VERSION "isobus-dd-11783"

NS_ :

BS_:

BU_: DD_SOURCE

BO_ 2550595584 DD_GPV4_1792: 8 DD_SOURCE
 SG_ General_purpose_valve_load_sense_pressure : 7|16@0+ (5.0,0.0) [0.0|321275.0] "kPa" Vector__XXX
 SG_ General_purpose_valve_pilot_pressure : 23|8@0+ (16.0,0.0) [0.0|4000.0] "kPa" Vector__XXX
 SG_ General_purpose_valve_assembly_load_sense_pressure : 31|16@0+ (5.0,0.0) [0.0|321275.0] "kPa" Vector__XXX
 SG_ General_purpose_valve_assembly_supply_pressure : 47|16@0+ (5.0,0.0) [0.0|321275.0] "kPa" Vector__XXX
 SG_ Valve_Pilot_Pressure_Switch : 63|2@0+ (4.0,0.0) [0.0|3.0] "" Vector__XXX

BO_ 2619539456 DD_TIM12_8960: 15 DD_SOURCE
 SG_ Auxiliary_Valve_1_Flow : 39|16@0- (0.004,-128.512) [-128.512|128.508] "%" Vector__XXX
 SG_ Auxiliary_Valve_1_Automation_Status : 23|4@0+ (16.0,0.0) [0.0|15.0] "Bit Field" Vector__XXX
 SG_ Auxiliary_Valve_1_Exit_Reason_Code : 28|5@0+ (32.0,0.0) [0.0|31.0] "Bit Field" Vector__XXX
 SG_ TIM_server_heartbeat_counter : 15|8@0+ (1.0,0.0) [0.0|255.0] "count" Vector__XXX
 SG_ Auxiliary_valve_1_flow_type : 31|2@0+ (4.0,0.0) [0.0|3.0] "bit" Vector__XXX
 SG_ TIM_v1_Server_to_Client_function_ID_Message_Code : 7|8@0+ (1.0,0.0) [0.0|255.0] "count" Vector__XXX
 SG_ Number_of_TIM_server_functions_assigned_to_CF_to_follow : 119|8@0+ (1.0,0.0) [0.0|250.0] "byte" Vector__XXX

BO_ 2619604992 DD_TIM21_9216: 8 DD_SOURCE
 SG_ Auxiliary_Valve_1_Flow_Request : 39|16@0- (0.004,-128.512) [-128.512|128.508] "%" Vector__XXX
 SG_ TIM_client_heartbeat_counter : 15|8@0+ (16.0,0.0) [0.0|255.0] "count" Vector__XXX
 SG_ TIM_client_state : 19|4@0+ (16.0,0.0) [0.0|13.0] "count" Vector__XXX
 SG_ TIM_Client_Minimum_TIM_version_number : 31|8@0+ (1.0,0.0) [0.0|250.0] "count" Vector__XXX
 SG_ TIM_v1_Client_to_Server_function_ID_Message_Code : 7|8@0+ (1.0,0.0) [0.0|255.0] "count" Vector__XXX

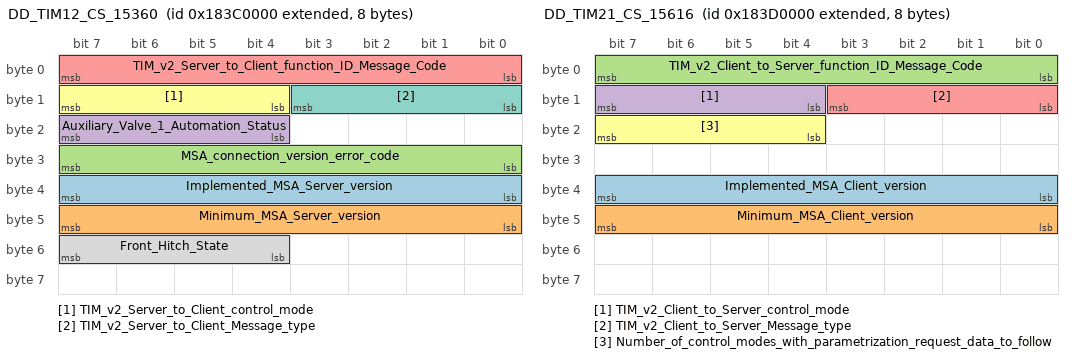
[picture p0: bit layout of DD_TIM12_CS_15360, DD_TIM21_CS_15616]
BO_ 2554068992 DD_TIM12_CS_15360: 8 DD_SOURCE
 SG_ Implemented_MSA_Server_version : 39|8@0+ (1.0,0.0) [0.0|255.0] "count" Vector__XXX
 SG_ Minimum_MSA_Server_version : 47|8@0+ (1.0,0.0) [0.0|255.0] "count" Vector__XXX
 SG_ MSA_connection_version_error_code : 31|8@0+ (1.0,0.0) [0.0|255.0] "count" Vector__XXX
 SG_ Auxiliary_Valve_1_Automation_Status : 23|4@0+ (16.0,0.0) [0.0|15.0] "Bit Field" Vector__XXX
 SG_ TIM_v2_Server_to_Client_function_ID_Message_Code : 7|8@0+ (1.0,0.0) [0.0|255.0] "count" Vector__XXX
 SG_ TIM_v2_Server_to_Client_control_mode : 15|4@0+ (16.0,0.0) [0.0|240.0] "" Vector__XXX
 SG_ TIM_v2_Server_to_Client_Message_type : 11|4@0+ (16.0,0.0) [0.0|240.0] "" Vector__XXX
 SG_ Front_Hitch_State : 55|4@0+ (16.0,0.0) [0.0|15.0] "Bit field" Vector__XXX

BO_ 2554134528 DD_TIM21_CS_15616: 8 DD_SOURCE
 SG_ Implemented_MSA_Client_version : 39|8@0+ (1.0,0.0) [0.0|255.0] "count" Vector__XXX
 SG_ Minimum_MSA_Client_version : 47|8@0+ (1.0,0.0) [0.0|255.0] "count" Vector__XXX
 SG_ TIM_v2_Client_to_Server_function_ID_Message_Code : 7|8@0+ (1.0,0.0) [0.0|255.0] "count" Vector__XXX
 SG_ TIM_v2_Client_to_Server_control_mode : 15|4@0+ (16.0,0.0) [0.0|240.0] "" Vector__XXX
 SG_ TIM_v2_Client_to_Server_Message_type : 11|4@0+ (16.0,0.0) [0.0|240.0] "" Vector__XXX
 SG_ Number_of_control_modes_with_parametrization_request_data_to_follow : 23|4@0+ (1.0,0.0) [0.0|15.0] "count" Vector__XXX

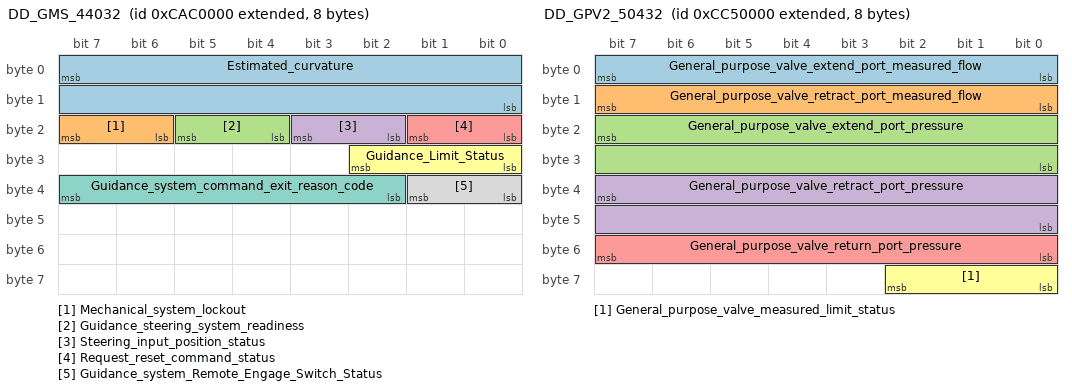
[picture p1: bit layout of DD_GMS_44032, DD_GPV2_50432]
BO_ 2360082432 DD_GMS_44032: 8 DD_SOURCE
 SG_ Estimated_curvature : 7|16@0- (0.25,-8032.0) [-8032.0|8031.75] "km-1" Vector__XXX
 SG_ Mechanical_system_lockout : 23|2@0+ (4.0,0.0) [0.0|3.0] "bit" Vector__XXX
 SG_ Guidance_steering_system_readiness : 21|2@0+ (4.0,0.0) [0.0|3.0] "bit" Vector__XXX
 SG_ Steering_input_position_status : 19|2@0+ (4.0,0.0) [0.0|3.0] "bit" Vector__XXX
 SG_ Request_reset_command_status : 17|2@0+ (4.0,0.0) [0.0|3.0] "bit" Vector__XXX
 SG_ Guidance_Limit_Status : 26|3@0+ (8.0,0.0) [0.0|7.0] "bit" Vector__XXX
 SG_ Guidance_system_command_exit_reason_code : 39|6@0+ (64.0,0.0) [0.0|63.0] "bit" Vector__XXX
 SG_ Guidance_system_Remote_Engage_Switch_Status : 33|2@0+ (4.0,0.0) [0.0|3.0] "bit" Vector__XXX

BO_ 2360147968 DD_GSC_44288: 8 DD_SOURCE
 SG_ Curvature_command : 7|16@0- (0.25,-8032.0) [-8032.0|8031.75] "km-1" Vector__XXX
 SG_ Curvature_command_status : 23|2@0+ (4.0,0.0) [0.0|3.0] "bit" Vector__XXX

BO_ 2361655296 DD_GPV3_50176: 8 DD_SOURCE
 SG_ General_purpose_valve_port_flow_Command : 7|8@0+ (0.4,0.0) [0.0|100.0] "%" Vector__XXX
 SG_ General_purpose_valve_state_Command : 23|4@0+ (16.0,0.0) [0.0|15.0] "bit" Vector__XXX
 SG_ General_purpose_value_fail_safe_mode_Command : 17|2@0+ (4.0,0.0) [0.0|3.0] "bit" Vector__XXX
 SG_ General_purpose_valve_port_flow_Extended_Resolution_Command : 31|16@0+ (0.0015625,0.0) [0.0|100.0] "%" Vector__XXX

BO_ 2361720832 DD_GPV2_50432: 8 DD_SOURCE
 SG_ General_purpose_valve_extend_port_measured_flow : 7|8@0- (1.0,-125.0) [-100.0|100.0] "%" Vector__XXX
 SG_ General_purpose_valve_retract_port_measured_flow : 15|8@0- (1.0,-125.0) [-100.0|100.0] "%" Vector__XXX
 SG_ General_purpose_valve_extend_port_pressure : 23|16@0+ (5.0,0.0) [0.0|321275.0] "kPa" Vector__XXX
 SG_ General_purpose_valve_retract_port_pressure : 39|16@0+ (5.0,0.0) [0.0|321275.0] "kPa" Vector__XXX
 SG_ General_purpose_valve_return_port_pressure : 55|8@0+ (16.0,0.0) [0.0|4000.0] "kPa" Vector__XXX
 SG_ General_purpose_valve_measured_limit_status : 58|3@0+ (8.0,0.0) [0.0|7.0] "bit" Vector__XXX

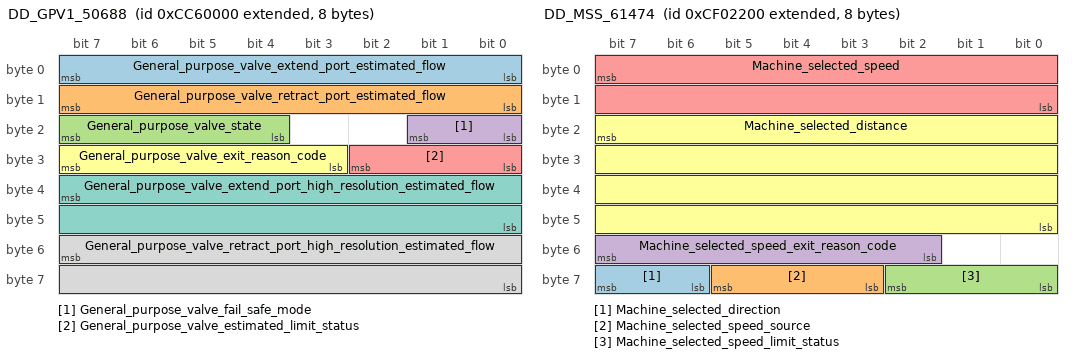
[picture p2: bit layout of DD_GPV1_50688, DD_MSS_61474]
BO_ 2361786368 DD_GPV1_50688: 8 DD_SOURCE
 SG_ General_purpose_valve_extend_port_estimated_flow : 7|8@0- (1.0,-125.0) [-100.0|100.0] "%" Vector__XXX
 SG_ General_purpose_valve_retract_port_estimated_flow : 15|8@0- (1.0,-125.0) [-100.0|100.0] "%" Vector__XXX
 SG_ General_purpose_valve_state : 23|4@0+ (16.0,0.0) [0.0|15.0] "bit" Vector__XXX
 SG_ General_purpose_valve_fail_safe_mode : 17|2@0+ (4.0,0.0) [0.0|3.0] "bit" Vector__XXX
 SG_ General_purpose_valve_estimated_limit_status : 26|3@0+ (8.0,0.0) [0.0|7.0] "bit" Vector__XXX
 SG_ General_purpose_valve_exit_reason_code : 31|5@0+ (32.0,0.0) [0.0|31.0] "bit" Vector__XXX
 SG_ General_purpose_valve_extend_port_high_resolution_estimated_flow : 39|16@0- (0.004,-125.0) [-100.0|100.0] "%" Vector__XXX
 SG_ General_purpose_valve_retract_port_high_resolution_estimated_flow : 55|16@0- (0.004,-125.0) [-100.0|100.0] "%" Vector__XXX

BO_ 2362114048 DD_PD_51968: 8 DD_SOURCE
 SG_ Process_data_command : 7|4@0+ (16.0,0.0) [0.0|15.0] "bit" Vector__XXX
 SG_ Process_data_element_number : 3|12@0+ (1.0,0.0) [0.0|4095.0] "bit" Vector__XXX
 SG_ Process_data_data_dictionary_identifier : 23|16@0+ (1.0,0.0) [0.0|65535.0] "bit" Vector__XXX
 SG_ Process_data_variable_value : 39|32@0+ (1.0,0.0) [0.0|4294967295.0] "VariantDetermined" Vector__XXX

BO_ 2563506176 DD_REQRR_52224: 8 DD_SOURCE
 SG_ PGN_of_the_request_1 : 7|24@0+ (1.0,0.0) [0.0|16.0] "PGN" Vector__XXX
 SG_ Repetition_rate_Command : 31|16@0+ (1.0,0.0) [0.0|64.0] "ms" Vector__XXX

BO_ 2362441728 DD_CL_53248: 8 DD_SOURCE
 SG_ Background_illumination_level_Command : 7|8@0+ (0.4,0.0) [0.0|102.0] "%" Vector__XXX

BO_ 2364547584 DD_MSS_61474: 8 DD_SOURCE
 SG_ Machine_selected_direction : 63|2@0+ (4.0,0.0) [0.0|3.0] "bit" Vector__XXX
 SG_ Machine_selected_speed_source : 61|3@0+ (8.0,0.0) [0.0|7.0] "bit" Vector__XXX
 SG_ Machine_selected_speed_limit_status : 58|3@0+ (8.0,0.0) [0.0|7.0] "bit" Vector__XXX
 SG_ Machine_selected_speed_exit_reason_code : 55|6@0+ (64.0,0.0) [0.0|63.0] "bit" Vector__XXX
 SG_ Machine_selected_speed : 7|16@0+ (0.001,0.0) [0.0|64.0] "m/s" Vector__XXX
 SG_ Machine_selected_distance : 23|32@0+ (0.001,0.0) [0.0|4.0] "m" Vector__XXX

BO_ 2364597248 DD_HRTBTM_61668: 8 DD_SOURCE
 SG_ Heartbeat_sequence_number : 7|8@0+ (1.0,0.0) [0.0|255.0] "count" Vector__XXX

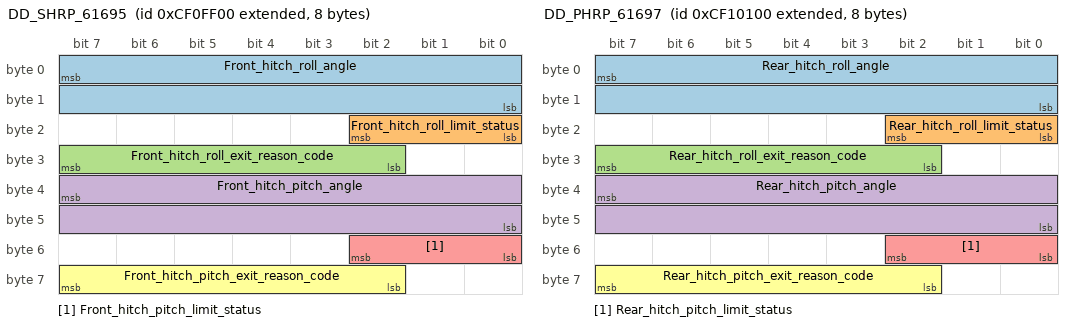
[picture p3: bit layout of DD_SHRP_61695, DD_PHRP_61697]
BO_ 2364604160 DD_SHRP_61695: 8 DD_SOURCE
 SG_ Front_hitch_roll_angle : 7|16@0- (0.002,-64.0) [-64.0|64.51] "deg" Vector__XXX
 SG_ Front_hitch_roll_limit_status : 18|3@0+ (8.0,0.0) [0.0|7.0] "bit" Vector__XXX
 SG_ Front_hitch_roll_exit_reason_code : 31|6@0+ (64.0,0.0) [0.0|63.0] "bit" Vector__XXX
 SG_ Front_hitch_pitch_angle : 39|16@0- (0.002,-64.0) [-64.0|64.51] "deg" Vector__XXX
 SG_ Front_hitch_pitch_limit_status : 50|3@0+ (8.0,0.0) [0.0|7.0] "bit" Vector__XXX
 SG_ Front_hitch_pitch_exit_reason_code : 63|6@0+ (64.0,0.0) [0.0|63.0] "bit" Vector__XXX

BO_ 2364604416 DD_SHRPC_61696: 8 DD_SOURCE
 SG_ Front_hitch_roll_command : 7|16@0- (0.002,-64.0) [-64.0|64.51] "deg" Vector__XXX
 SG_ Front_hitch_roll_sensitivity_command : 23|8@0+ (0.4,0.0) [0.0|100.0] "%" Vector__XXX
 SG_ Front_hitch_pitch_command : 31|16@0- (0.002,-64.0) [-64.0|64.51] "deg" Vector__XXX
 SG_ Front_hitch_pitch_sensitivity_command : 47|8@0+ (0.4,0.0) [0.0|100.0] "%" Vector__XXX

BO_ 2364604672 DD_PHRP_61697: 8 DD_SOURCE
 SG_ Rear_hitch_roll_angle : 7|16@0- (0.002,-64.0) [-64.0|64.51] "deg" Vector__XXX
 SG_ Rear_hitch_roll_limit_status : 18|3@0+ (8.0,0.0) [0.0|7.0] "bit" Vector__XXX
 SG_ Rear_hitch_roll_exit_reason_code : 31|6@0+ (64.0,0.0) [0.0|63.0] "bit" Vector__XXX
 SG_ Rear_hitch_pitch_angle : 39|16@0- (0.002,-64.0) [-64.0|64.51] "deg" Vector__XXX
 SG_ Rear_hitch_pitch_limit_status : 50|3@0+ (8.0,0.0) [0.0|7.0] "bit" Vector__XXX
 SG_ Rear_hitch_pitch_exit_reason_code : 63|6@0+ (64.0,0.0) [0.0|63.0] "bit" Vector__XXX

BO_ 2364604928 DD_PHRPC_61698: 8 DD_SOURCE
 SG_ Rear_hitch_roll_command : 7|16@0- (0.002,-64.0) [-64.0|64.51] "deg" Vector__XXX
 SG_ Rear_hitch_roll_sensitivity_command : 23|8@0+ (0.4,0.0) [0.0|100.0] "%" Vector__XXX
 SG_ Rear_hitch_pitch_command : 31|16@0- (0.002,-64.0) [-64.0|64.51] "deg" Vector__XXX
 SG_ Rear_hitch_pitch_sensitivity_command : 47|8@0+ (0.4,0.0) [0.0|100.0] "%" Vector__XXX

BO_ 2364620288 DD_FHYC_61758: 8 DD_SOURCE
 SG_ Front_hitch_yaw_command : 7|16@0- (1.0,-200.0) [-200.0|200.0] "deg" Vector__XXX

BO_ 2364620544 DD_RHYC_61759: 8 DD_SOURCE
 SG_ Rear_hitch_yaw_command : 7|16@0- (1.0,-200.0) [-200.0|200.0] "deg" Vector__XXX

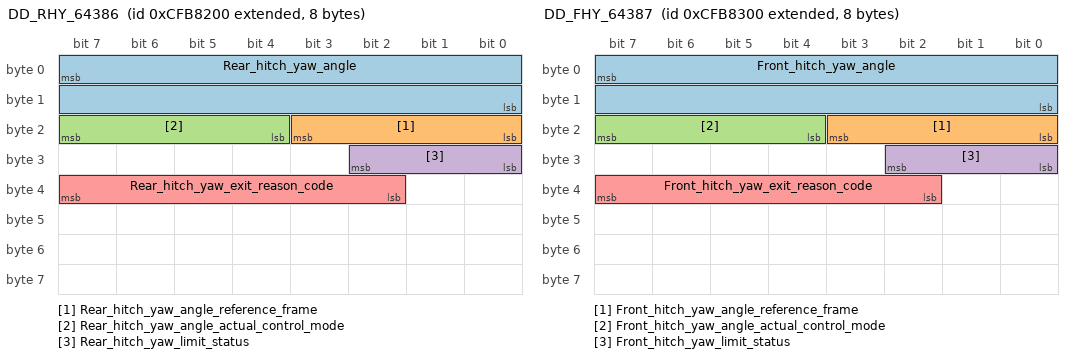
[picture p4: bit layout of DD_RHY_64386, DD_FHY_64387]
BO_ 2365293056 DD_RHY_64386: 8 DD_SOURCE
 SG_ Rear_hitch_yaw_angle : 7|16@0- (1.0,-200.0) [-200.0|200.0] "deg" Vector__XXX
 SG_ Rear_hitch_yaw_angle_reference_frame : 19|4@0+ (16.0,0.0) [0.0|15.0] "bit" Vector__XXX
 SG_ Rear_hitch_yaw_angle_actual_control_mode : 23|4@0+ (16.0,0.0) [0.0|15.0] "bit" Vector__XXX
 SG_ Rear_hitch_yaw_limit_status : 26|3@0+ (8.0,0.0) [0.0|7.0] "bit" Vector__XXX
 SG_ Rear_hitch_yaw_exit_reason_code : 39|6@0+ (64.0,0.0) [0.0|63.0] "bit" Vector__XXX

BO_ 2365293312 DD_FHY_64387: 8 DD_SOURCE
 SG_ Front_hitch_yaw_angle : 7|16@0- (1.0,-200.0) [-200.0|200.0] "deg" Vector__XXX
 SG_ Front_hitch_yaw_angle_reference_frame : 19|4@0+ (16.0,0.0) [0.0|15.0] "bit" Vector__XXX
 SG_ Front_hitch_yaw_angle_actual_control_mode : 23|4@0+ (16.0,0.0) [0.0|15.0] "bit" Vector__XXX
 SG_ Front_hitch_yaw_limit_status : 26|3@0+ (8.0,0.0) [0.0|7.0] "bit" Vector__XXX
 SG_ Front_hitch_yaw_exit_reason_code : 39|6@0+ (64.0,0.0) [0.0|63.0] "bit" Vector__XXX

BO_ 2365293568 DD_OPSTAT_64388: 8 DD_SOURCE
 SG_ Operator_Status_Sequence_Counter : 7|8@0+ (256.0,0.0) [0.0|255.0] "bit" Vector__XXX
 SG_ Operator_Presence_state : 15|2@0+ (4.0,0.0) [0.0|3.0] "bit" Vector__XXX
 SG_ Operator_Awareness_state : 13|2@0+ (4.0,0.0) [0.0|3.0] "bit" Vector__XXX
 SG_ Operator_Presence_and_Awareness_Status_Checksum : 63|8@0+ (256.0,0.0) [0.0|255.0] "bit" Vector__XXX

BO_ 2566655488 DD_PHRPS_64526: 8 DD_SOURCE
 SG_ Rear_hitch_roll_sensitivity : 7|8@0+ (0.4,0.0) [0.0|100.0] "%" Vector__XXX
 SG_ Rear_hitch_pitch_sensitivity : 15|8@0+ (0.4,0.0) [0.0|100.0] "%" Vector__XXX

BO_ 2566655744 DD_SHRPS_64527: 8 DD_SOURCE
 SG_ Front_hitch_roll_sensitivity : 7|8@0+ (0.4,0.0) [0.0|100.0] "%" Vector__XXX
 SG_ Front_hitch_pitch_sensitivity : 15|8@0+ (0.4,0.0) [0.0|100.0] "%" Vector__XXX

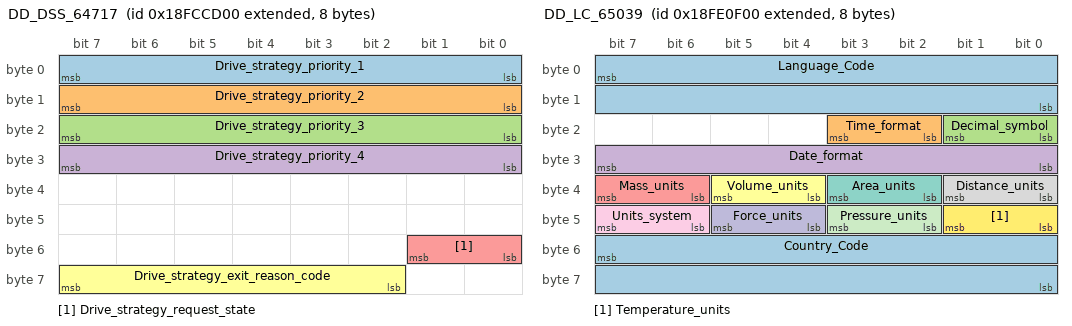
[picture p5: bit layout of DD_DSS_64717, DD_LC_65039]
BO_ 2566704384 DD_DSS_64717: 8 DD_SOURCE
 SG_ Drive_strategy_priority_1 : 7|8@0+ (256.0,0.0) [0.0|255.0] "bit" Vector__XXX
 SG_ Drive_strategy_priority_2 : 15|8@0+ (256.0,0.0) [0.0|255.0] "bit" Vector__XXX
 SG_ Drive_strategy_priority_3 : 23|8@0+ (256.0,0.0) [0.0|255.0] "bit" Vector__XXX
 SG_ Drive_strategy_priority_4 : 31|8@0+ (256.0,0.0) [0.0|255.0] "bit" Vector__XXX
 SG_ Drive_strategy_request_state : 49|2@0+ (4.0,0.0) [0.0|3.0] "bit" Vector__XXX
 SG_ Drive_strategy_exit_reason_code : 63|6@0+ (64.0,0.0) [0.0|63.0] "bit" Vector__XXX

BO_ 2365378048 DD_DSC_64718: 8 DD_SOURCE
 SG_ Drive_strategy_priority_1_request : 7|8@0+ (256.0,0.0) [0.0|255.0] "bit" Vector__XXX
 SG_ Drive_strategy_priority_2_request : 15|8@0+ (256.0,0.0) [0.0|255.0] "bit" Vector__XXX
 SG_ Drive_strategy_priority_3_request : 23|8@0+ (256.0,0.0) [0.0|255.0] "bit" Vector__XXX
 SG_ Drive_strategy_priority_4_request : 31|8@0+ (256.0,0.0) [0.0|255.0] "bit" Vector__XXX
 SG_ Restore_operator_drive_strategy_setting_request : 63|2@0+ (4.0,0.0) [0.0|3.0] "bit" Vector__XXX

BO_ 2365391360 DD_AISO_64770: 8 DD_SOURCE
 SG_ Stop_all_implement_operations : 63|2@0+ (4.0,0.0) [0.0|3.0] "bit" Vector__XXX
 SG_ Stop_All_Implement_Operations_Transition_Number : 55|8@0+ (256.0,0.0) [0.0|255.0] "bit" Vector__XXX

BO_ 2365391616 DD_IOS_64771: 8 DD_SOURCE
 SG_ Implement_operating_state_command : 63|2@0+ (4.0,0.0) [0.0|3.0] "bit" Vector__XXX

BO_ 2566730240 DD_ECUDP_64818: 8 DD_SOURCE
 SG_ Diagnostic_protocol_identification : 7|8@0+ (8.0,0.0) [0.0|2040.0] "Bit mapped" Vector__XXX

BO_ 2566734336 DD_ICC_64834: 8 DD_SOURCE
 SG_ ISOBUS_compliance_test_protocol_publication_year : 7|6@0+ (1.0,2000.0) [2000.0|2061.0] "Years" Vector__XXX
 SG_ ISOBUS_compliance_test_protocol_revision : 1|5@0+ (32.0,0.0) [0.0|30.0] "bit" Vector__XXX
 SG_ ISOBUS_compliance_certification_laboratory_ID : 10|11@0+ (2047.0,0.0) [0.0|2047.0] "bit" Vector__XXX
 SG_ ISOBUS_compliance_certification_type_Minimum_CF : 24|1@0+ (2.0,0.0) [0.0|1.0] "bit" Vector__XXX
 SG_ ISOBUS_compliance_certification_type_TECU_Class_1 : 25|1@0+ (2.0,0.0) [0.0|1.0] "bit" Vector__XXX
 SG_ ISOBUS_compliance_certification_type_TECU_Class_2 : 26|1@0+ (2.0,0.0) [0.0|1.0] "bit" Vector__XXX
 SG_ ISOBUS_compliance_certification_type_TECU_Class_3 : 27|1@0+ (2.0,0.0) [0.0|1.0] "bit" Vector__XXX
 SG_ ISOBUS_compliance_certification_type_Class_3_ECU : 28|1@0+ (2.0,0.0) [0.0|1.0] "bit" Vector__XXX
 SG_ ISOBUS_compliance_certification_type_Virtual_terminal : 29|1@0+ (2.0,0.0) [0.0|1.0] "bit" Vector__XXX
 SG_ ISOBUS_compliance_certification_type_VT_working_set_master : 30|1@0+ (2.0,0.0) [0.0|1.0] "bit" Vector__XXX
 SG_ ISOBUS_compliance_certification_type_VT_working_set_member : 31|1@0+ (2.0,0.0) [0.0|1.0] "bit" Vector__XXX
 SG_ ISOBUS_compliance_certification_type_Task_Controller : 32|1@0+ (2.0,0.0) [0.0|1.0] "bit" Vector__XXX
 SG_ ISOBUS_compliance_certification_type_TC_working_set_master : 33|1@0+ (2.0,0.0) [0.0|1.0] "bit" Vector__XXX
 SG_ ISOBUS_compliance_certification_type_TC_working_set_member : 34|1@0+ (2.0,0.0) [0.0|1.0] "bit" Vector__XXX
 SG_ ISOBUS_compliance_certification_type_File_server : 35|1@0+ (2.0,0.0) [0.0|1.0] "bit" Vector__XXX
 SG_ ISOBUS_compliance_certification_type_GPS_receiver : 36|1@0+ (2.0,0.0) [0.0|1.0] "bit" Vector__XXX
 SG_ ISOBUS_compliance_certification_reference_number : 55|16@0+ (1.0,0.0) [0.0|65535.0] "count" Vector__XXX
 SG_ ISOBUS_compliance_certification_message_revision : 40|1@0+ (2.0,0.0) [0.0|1.0] "bit" Vector__XXX

BO_ 2365408000 DD_MSSC_64835: 8 DD_SOURCE
 SG_ Machine_selected_speed_set_point_command : 7|16@0+ (0.001,0.0) [0.0|64.0] "m/s" Vector__XXX
 SG_ Machine_selected_speed_setpoint_limit : 23|16@0+ (0.001,0.0) [0.0|64.0] "m/s" Vector__XXX
 SG_ Machine_selected_direction_command : 63|2@0+ (4.0,0.0) [0.0|3.0] "bit" Vector__XXX

BO_ 2365458432 DD_RTF_65032: 8 DD_SOURCE
 SG_ Speed_information_engine_speed : 7|1@0+ (2.0,0.0) [0.0|1.0] "bit" Vector__XXX
 SG_ Speed_information_ground_based_speed : 6|1@0+ (2.0,0.0) [0.0|1.0] "bit" Vector__XXX
 SG_ Speed_information_wheel_based_speed : 5|1@0+ (2.0,0.0) [0.0|1.0] "bit" Vector__XXX
 SG_ Power_management_maintain_power : 4|1@0+ (2.0,0.0) [0.0|1.0] "bit" Vector__XXX
 SG_ Power_management_maximum_time_tractor_power : 3|1@0+ (2.0,0.0) [0.0|1.0] "bit" Vector__XXX
 SG_ Power_management_key_switch : 2|1@0+ (2.0,0.0) [0.0|1.0] "bit" Vector__XXX
 SG_ Tractor_ECU_class_request : 1|2@0+ (4.0,0.0) [0.0|3.0] "bit" Vector__XXX
 SG_ Language_command_storage_in_Tractor_ECU : 13|1@0+ (2.0,0.0) [0.0|1.0] "bit" Vector__XXX
 SG_ Lighting_minimal_set_as_existing_trailer_connector : 12|1@0+ (2.0,0.0) [0.0|1.0] "bit" Vector__XXX
 SG_ PTO_information_rear_shaft_engagement : 11|1@0+ (2.0,0.0) [0.0|1.0] "bit" Vector__XXX
 SG_ PTO_information_rear_shaft_speed : 10|1@0+ (2.0,0.0) [0.0|1.0] "bit" Vector__XXX
 SG_ Hitch_information_rear_in_work : 9|1@0+ (2.0,0.0) [0.0|1.0] "bit" Vector__XXX
 SG_ Hitch_information_rear_position : 8|1@0+ (2.0,0.0) [0.0|1.0] "bit" Vector__XXX
 SG_ Estimated_or_measured_auxiliary_valve_status : 23|1@0+ (2.0,0.0) [0.0|1.0] "bit" Vector__XXX
 SG_ Lighting_full_implement_lighting_message_set : 22|1@0+ (2.0,0.0) [0.0|1.0] "bit" Vector__XXX
 SG_ Additional_hitch_parameters_rear_draft : 21|1@0+ (2.0,0.0) [0.0|1.0] "bit" Vector__XXX
 SG_ Speed_and_distance_wheel_based_direction : 20|1@0+ (2.0,0.0) [0.0|1.0] "bit" Vector__XXX
 SG_ Speed_and_distance_wheel_based_distance : 19|1@0+ (2.0,0.0) [0.0|1.0] "bit" Vector__XXX
 SG_ Speed_and_distance_ground_based_direction : 18|1@0+ (2.0,0.0) [0.0|1.0] "bit" Vector__XXX
 SG_ Speed_and_distance_ground_based_distance : 17|1@0+ (2.0,0.0) [0.0|1.0] "bit" Vector__XXX
 SG_ Time_date : 16|1@0+ (2.0,0.0) [0.0|1.0] "bit" Vector__XXX
 SG_ PTO_commands_rear_PTO_mode_gear_command : 29|1@0+ (2.0,0.0) [0.0|1.0] "bit" Vector__XXX
 SG_ Limit_request_status_reporting : 28|1@0+ (2.0,0.0) [0.0|1.0] "bit" Vector__XXX
 SG_ Auxiliary_valve_commands : 27|1@0+ (2.0,0.0) [0.0|1.0] "bit" Vector__XXX
 SG_ PTO_commands_rear_PTO_engagement_command : 26|1@0+ (2.0,0.0) [0.0|1.0] "bit" Vector__XXX
 SG_ PTO_commands_rear_PTO_speed_command : 25|1@0+ (2.0,0.0) [0.0|1.0] "bit" Vector__XXX
 SG_ Hitch_commands_rear_hitch_position : 24|1@0+ (2.0,0.0) [0.0|1.0] "bit" Vector__XXX
 SG_ Direction_control : 39|1@0+ (2.0,0.0) [0.0|1.0] "bit" Vector__XXX
 SG_ Machine_selected_speed_control : 38|1@0+ (2.0,0.0) [0.0|1.0] "bit" Vector__XXX
 SG_ Machine_selected_speed : 37|1@0+ (2.0,0.0) [0.0|1.0] "bit" Vector__XXX
 SG_ Operator_external_light_controls : 36|1@0+ (2.0,0.0) [0.0|1.0] "bit" Vector__XXX
 SG_ Navigational_pseudo_range_noise_statistics : 34|1@0+ (2.0,0.0) [0.0|1.0] "bit" Vector__XXX
 SG_ Navigational_system_position_data : 33|1@0+ (2.0,0.0) [0.0|1.0] "bit" Vector__XXX
 SG_ Navigational_system_high_output_position : 32|1@0+ (2.0,0.0) [0.0|1.0] "bit" Vector__XXX
 SG_ PTO_commands_front_PTO_engagement_command : 47|1@0+ (2.0,0.0) [0.0|1.0] "bit" Vector__XXX
 SG_ PTO_commands_front_PTO_speed_command : 46|1@0+ (2.0,0.0) [0.0|1.0] "bit" Vector__XXX
 SG_ Hitch_commands_front_hitch_position : 45|1@0+ (2.0,0.0) [0.0|1.0] "bit" Vector__XXX
 SG_ Additional_hitch_parameters_front_draft : 44|1@0+ (2.0,0.0) [0.0|1.0] "bit" Vector__XXX
 SG_ PTO_information_front_shaft_engagement : 43|1@0+ (2.0,0.0) [0.0|1.0] "bit" Vector__XXX
 SG_ PTO_information_front_shaft_speed : 42|1@0+ (2.0,0.0) [0.0|1.0] "bit" Vector__XXX
 SG_ Hitch_information_front_in_work : 41|1@0+ (2.0,0.0) [0.0|1.0] "bit" Vector__XXX
 SG_ Hitch_information_front_position : 40|1@0+ (2.0,0.0) [0.0|1.0] "bit" Vector__XXX
 SG_ Drive_Strategy_Status_and_Commands : 55|1@0+ (2.0,0.0) [0.0|1.0] "bit" Vector__XXX
 SG_ External_Guidance_Status_and_Commands : 54|1@0+ (2.0,0.0) [0.0|1.0] "bit" Vector__XXX
 SG_ PTO_commands_front_PTO_mode_gear_command : 48|1@0+ (2.0,0.0) [0.0|1.0] "bit" Vector__XXX
 SG_ Tractor_facility_reserved_bit_indicator : 63|1@0+ (2.0,0.0) [0.0|1.0] "bit" Vector__XXX

BO_ 2365458688 DD_TFR_65033: 8 DD_SOURCE
 SG_ Speed_information_engine_speed : 7|1@0+ (2.0,0.0) [0.0|1.0] "bit" Vector__XXX
 SG_ Speed_information_ground_based_speed : 6|1@0+ (2.0,0.0) [0.0|1.0] "bit" Vector__XXX
 SG_ Speed_information_wheel_based_speed : 5|1@0+ (2.0,0.0) [0.0|1.0] "bit" Vector__XXX
 SG_ Power_management_maintain_power : 4|1@0+ (2.0,0.0) [0.0|1.0] "bit" Vector__XXX
 SG_ Power_management_maximum_time_tractor_power : 3|1@0+ (2.0,0.0) [0.0|1.0] "bit" Vector__XXX
 SG_ Power_management_key_switch : 2|1@0+ (2.0,0.0) [0.0|1.0] "bit" Vector__XXX
 SG_ Tractor_ECU_class_response : 1|2@0+ (4.0,0.0) [0.0|3.0] "bit" Vector__XXX
 SG_ Language_command_storage_in_Tractor_ECU : 13|1@0+ (2.0,0.0) [0.0|1.0] "bit" Vector__XXX
 SG_ Lighting_minimal_set_as_existing_trailer_connector : 12|1@0+ (2.0,0.0) [0.0|1.0] "bit" Vector__XXX
 SG_ PTO_information_rear_shaft_engagement : 11|1@0+ (2.0,0.0) [0.0|1.0] "bit" Vector__XXX
 SG_ PTO_information_rear_shaft_speed : 10|1@0+ (2.0,0.0) [0.0|1.0] "bit" Vector__XXX
 SG_ Hitch_information_rear_in_work : 9|1@0+ (2.0,0.0) [0.0|1.0] "bit" Vector__XXX
 SG_ Hitch_information_rear_position : 8|1@0+ (2.0,0.0) [0.0|1.0] "bit" Vector__XXX
 SG_ Estimated_or_measured_auxiliary_valve_status : 23|1@0+ (2.0,0.0) [0.0|1.0] "bit" Vector__XXX
 SG_ Lighting_full_implement_lighting_message_set : 22|1@0+ (2.0,0.0) [0.0|1.0] "bit" Vector__XXX
 SG_ Speed_and_distance_wheel_based_direction : 20|1@0+ (2.0,0.0) [0.0|1.0] "bit" Vector__XXX
 SG_ Speed_and_distance_wheel_based_distance : 19|1@0+ (2.0,0.0) [0.0|1.0] "bit" Vector__XXX
 SG_ Speed_and_distance_ground_based_direction : 18|1@0+ (2.0,0.0) [0.0|1.0] "bit" Vector__XXX
 SG_ Speed_and_distance_ground_based_distance : 17|1@0+ (2.0,0.0) [0.0|1.0] "bit" Vector__XXX
 SG_ Time_date : 16|1@0+ (2.0,0.0) [0.0|1.0] "bit" Vector__XXX
 SG_ PTO_commands_rear_PTO_mode_gear_command : 29|1@0+ (2.0,0.0) [0.0|1.0] "bit" Vector__XXX
 SG_ Tractor_facility_response_Limit_request_status_reporting : 28|1@0+ (2.0,0.0) [0.0|1.0] "bit" Vector__XXX
 SG_ Auxiliary_valve_commands : 27|1@0+ (2.0,0.0) [0.0|1.0] "bit" Vector__XXX
 SG_ PTO_commands_rear_PTO_engagement_command : 26|1@0+ (2.0,0.0) [0.0|1.0] "bit" Vector__XXX
 SG_ PTO_commands_rear_PTO_speed_command : 25|1@0+ (2.0,0.0) [0.0|1.0] "bit" Vector__XXX
 SG_ Hitch_commands_rear_hitch_position : 24|1@0+ (2.0,0.0) [0.0|1.0] "bit" Vector__XXX
 SG_ Direction_control : 39|1@0+ (2.0,0.0) [0.0|1.0] "bit" Vector__XXX
 SG_ Machine_selected_speed_control : 38|1@0+ (2.0,0.0) [0.0|1.0] "bit" Vector__XXX
 SG_ Machine_selected_speed : 37|1@0+ (2.0,0.0) [0.0|1.0] "bit" Vector__XXX
 SG_ Operator_external_light_controls : 36|1@0+ (2.0,0.0) [0.0|1.0] "bit" Vector__XXX
 SG_ Navigational_pseudo_range_noise_statistics : 34|1@0+ (2.0,0.0) [0.0|1.0] "bit" Vector__XXX
 SG_ Navigational_system_position_data : 33|1@0+ (2.0,0.0) [0.0|1.0] "bit" Vector__XXX
 SG_ Navigational_system_high_output_position : 32|1@0+ (2.0,0.0) [0.0|1.0] "bit" Vector__XXX
 SG_ PTO_commands_front_PTO_engagement_command : 47|1@0+ (2.0,0.0) [0.0|1.0] "bit" Vector__XXX
 SG_ PTO_commands_front_PTO_speed_command : 46|1@0+ (2.0,0.0) [0.0|1.0] "bit" Vector__XXX
 SG_ Hitch_commands_front_hitch_position : 45|1@0+ (2.0,0.0) [0.0|1.0] "bit" Vector__XXX
 SG_ Additional_hitch_parameters_front_draft : 44|1@0+ (2.0,0.0) [0.0|1.0] "bit" Vector__XXX
 SG_ PTO_information_front_shaft_engagement : 43|1@0+ (2.0,0.0) [0.0|1.0] "bit" Vector__XXX
 SG_ PTO_information_front_shaft_speed : 42|1@0+ (2.0,0.0) [0.0|1.0] "bit" Vector__XXX
 SG_ Hitch_information_front_in_work : 41|1@0+ (2.0,0.0) [0.0|1.0] "bit" Vector__XXX
 SG_ Hitch_information_front_position : 40|1@0+ (2.0,0.0) [0.0|1.0] "bit" Vector__XXX
 SG_ Drive_Strategy_Status_and_Commands : 55|1@0+ (2.0,0.0) [0.0|1.0] "bit" Vector__XXX
 SG_ External_Guidance_Status_and_Commands : 54|1@0+ (2.0,0.0) [0.0|1.0] "bit" Vector__XXX
 SG_ PTO_commands_front_PTO_mode_gear_command : 48|1@0+ (2.0,0.0) [0.0|1.0] "bit" Vector__XXX
 SG_ Tractor_facility_reserved_bit_indicator : 63|1@0+ (2.0,0.0) [0.0|1.0] "bit" Vector__XXX

BO_ 2365459200 DD_IRC_65035: 8 DD_SOURCE
 SG_ Tractor_control_mode_command_number_1 : 4|5@0+ (32.0,0.0) [0.0|31.0] "bit" Vector__XXX
 SG_ Tractor_control_mode_command_number_2 : 12|5@0+ (32.0,0.0) [0.0|31.0] "bit" Vector__XXX

BO_ 2633894912 DD_WSMEM_65036: 8 DD_SOURCE
 SG_ NAME_of_Working_Set_Member : 7|64@0+ (1.0,0.0) [0.0|1.8446744073709552e+19] "bit" Vector__XXX

BO_ 2633895168 DD_WSMSTR_65037: 8 DD_SOURCE
 SG_ Number_of_Members_in_Working_Set : 7|8@0+ (1.0,0.0) [0.0|250.0] "bit" Vector__XXX

BO_ 2566786560 DD_RESRR_65038: 8 DD_SOURCE
 SG_ PGN_of_the_request_2 : 7|24@0+ (1.0,0.0) [0.0|16777215.0] "PGN" Vector__XXX
 SG_ Repetition_rate : 31|16@0+ (1.0,0.0) [0.0|64.0] "ms" Vector__XXX

BO_ 2566786816 DD_LC_65039: 8 DD_SOURCE
 SG_ Language_Code : 7|16@0+ (7.0,0.0) [97.0|122.0] "7 bit ISO Latin 1 characters (lo" Vector__XXX
 SG_ Time_format : 19|2@0+ (4.0,0.0) [0.0|3.0] "bit" Vector__XXX
 SG_ Decimal_symbol : 17|2@0+ (4.0,0.0) [0.0|3.0] "bit" Vector__XXX
 SG_ Date_format : 31|8@0+ (1.0,0.0) [0.0|255.0] "binary" Vector__XXX
 SG_ Mass_units : 39|2@0+ (4.0,0.0) [0.0|3.0] "bit" Vector__XXX
 SG_ Volume_units : 37|2@0+ (4.0,0.0) [0.0|3.0] "bit" Vector__XXX
 SG_ Area_units : 35|2@0+ (4.0,0.0) [0.0|3.0] "bit" Vector__XXX
 SG_ Distance_units : 33|2@0+ (4.0,0.0) [0.0|3.0] "bit" Vector__XXX
 SG_ Units_system : 47|2@0+ (4.0,0.0) [0.0|3.0] "bit" Vector__XXX
 SG_ Force_units : 45|2@0+ (4.0,0.0) [0.0|3.0] "bit" Vector__XXX
 SG_ Pressure_units : 43|2@0+ (4.0,0.0) [0.0|3.0] "bit" Vector__XXX
 SG_ Temperature_units : 41|2@0+ (4.0,0.0) [0.0|3.0] "bit" Vector__XXX
 SG_ Country_Code : 55|16@0+ (7.0,0.0) [65.0|90.0] "7 bit ISO Latin 1 characters (up" Vector__XXX

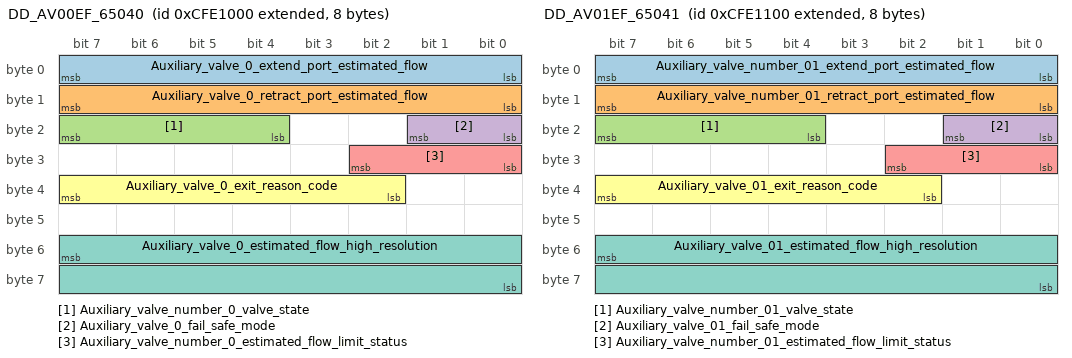
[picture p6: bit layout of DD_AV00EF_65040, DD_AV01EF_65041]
BO_ 2365460480 DD_AV00EF_65040: 8 DD_SOURCE
 SG_ Auxiliary_valve_0_extend_port_estimated_flow : 7|8@0- (1.0,-125.0) [-125.0|125.0] "%" Vector__XXX
 SG_ Auxiliary_valve_0_retract_port_estimated_flow : 15|8@0- (1.0,-125.0) [-125.0|125.0] "%" Vector__XXX
 SG_ Auxiliary_valve_number_0_valve_state : 23|4@0+ (16.0,0.0) [0.0|15.0] "bit" Vector__XXX
 SG_ Auxiliary_valve_0_fail_safe_mode : 17|2@0+ (4.0,0.0) [0.0|3.0] "bit" Vector__XXX
 SG_ Auxiliary_valve_number_0_estimated_flow_limit_status : 26|3@0+ (8.0,0.0) [0.0|7.0] "bit" Vector__XXX
 SG_ Auxiliary_valve_0_exit_reason_code : 39|6@0+ (64.0,0.0) [0.0|63.0] "bit" Vector__XXX
 SG_ Auxiliary_valve_0_estimated_flow_high_resolution : 55|16@0- (0.004,-125.0) [-100.0|100.0] "%" Vector__XXX

BO_ 2365460736 DD_AV01EF_65041: 8 DD_SOURCE
 SG_ Auxiliary_valve_number_01_extend_port_estimated_flow : 7|8@0- (1.0,-125.0) [-125.0|125.0] "%" Vector__XXX
 SG_ Auxiliary_valve_number_01_retract_port_estimated_flow : 15|8@0- (1.0,-125.0) [-125.0|125.0] "%" Vector__XXX
 SG_ Auxiliary_valve_number_01_valve_state : 23|4@0+ (16.0,0.0) [0.0|15.0] "bit" Vector__XXX
 SG_ Auxiliary_valve_01_fail_safe_mode : 17|2@0+ (4.0,0.0) [0.0|3.0] "bit" Vector__XXX
 SG_ Auxiliary_valve_number_01_estimated_flow_limit_status : 26|3@0+ (8.0,0.0) [0.0|7.0] "bit" Vector__XXX
 SG_ Auxiliary_valve_01_exit_reason_code : 39|6@0+ (64.0,0.0) [0.0|63.0] "bit" Vector__XXX
 SG_ Auxiliary_valve_01_estimated_flow_high_resolution : 55|16@0- (0.004,-125.0) [-100.0|100.0] "%" Vector__XXX

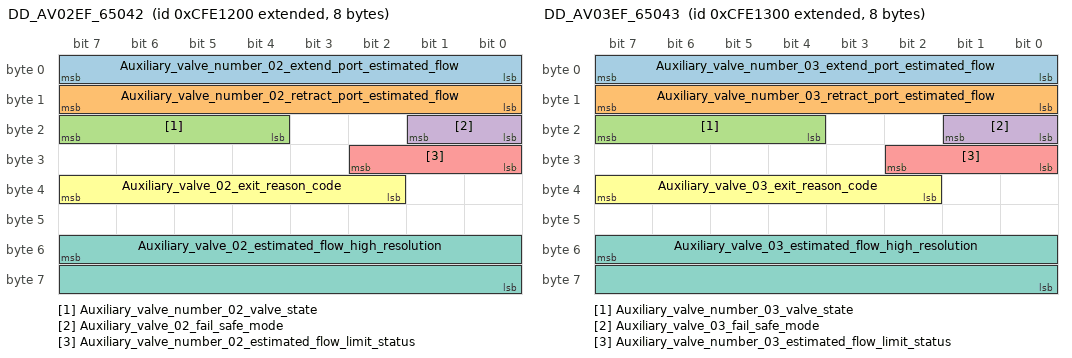
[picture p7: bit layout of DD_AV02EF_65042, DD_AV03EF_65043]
BO_ 2365460992 DD_AV02EF_65042: 8 DD_SOURCE
 SG_ Auxiliary_valve_number_02_extend_port_estimated_flow : 7|8@0- (1.0,-125.0) [-125.0|125.0] "%" Vector__XXX
 SG_ Auxiliary_valve_number_02_retract_port_estimated_flow : 15|8@0- (1.0,-125.0) [-125.0|125.0] "%" Vector__XXX
 SG_ Auxiliary_valve_number_02_valve_state : 23|4@0+ (16.0,0.0) [0.0|15.0] "bit" Vector__XXX
 SG_ Auxiliary_valve_02_fail_safe_mode : 17|2@0+ (4.0,0.0) [0.0|3.0] "bit" Vector__XXX
 SG_ Auxiliary_valve_number_02_estimated_flow_limit_status : 26|3@0+ (8.0,0.0) [0.0|7.0] "bit" Vector__XXX
 SG_ Auxiliary_valve_02_exit_reason_code : 39|6@0+ (64.0,0.0) [0.0|63.0] "bit" Vector__XXX
 SG_ Auxiliary_valve_02_estimated_flow_high_resolution : 55|16@0- (0.004,-125.0) [-100.0|100.0] "%" Vector__XXX

BO_ 2365461248 DD_AV03EF_65043: 8 DD_SOURCE
 SG_ Auxiliary_valve_number_03_extend_port_estimated_flow : 7|8@0- (1.0,-125.0) [-125.0|125.0] "%" Vector__XXX
 SG_ Auxiliary_valve_number_03_retract_port_estimated_flow : 15|8@0- (1.0,-125.0) [-125.0|125.0] "%" Vector__XXX
 SG_ Auxiliary_valve_number_03_valve_state : 23|4@0+ (16.0,0.0) [0.0|15.0] "bit" Vector__XXX
 SG_ Auxiliary_valve_03_fail_safe_mode : 17|2@0+ (4.0,0.0) [0.0|3.0] "bit" Vector__XXX
 SG_ Auxiliary_valve_number_03_estimated_flow_limit_status : 26|3@0+ (8.0,0.0) [0.0|7.0] "bit" Vector__XXX
 SG_ Auxiliary_valve_03_exit_reason_code : 39|6@0+ (64.0,0.0) [0.0|63.0] "bit" Vector__XXX
 SG_ Auxiliary_valve_03_estimated_flow_high_resolution : 55|16@0- (0.004,-125.0) [-100.0|100.0] "%" Vector__XXX

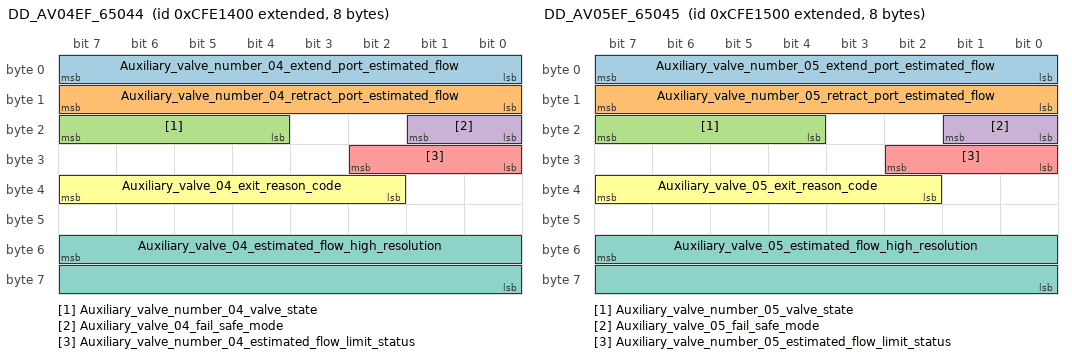
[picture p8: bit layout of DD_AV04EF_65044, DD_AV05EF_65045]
BO_ 2365461504 DD_AV04EF_65044: 8 DD_SOURCE
 SG_ Auxiliary_valve_number_04_extend_port_estimated_flow : 7|8@0- (1.0,-125.0) [-125.0|125.0] "%" Vector__XXX
 SG_ Auxiliary_valve_number_04_retract_port_estimated_flow : 15|8@0- (1.0,-125.0) [-125.0|125.0] "%" Vector__XXX
 SG_ Auxiliary_valve_number_04_valve_state : 23|4@0+ (16.0,0.0) [0.0|15.0] "bit" Vector__XXX
 SG_ Auxiliary_valve_04_fail_safe_mode : 17|2@0+ (4.0,0.0) [0.0|3.0] "bit" Vector__XXX
 SG_ Auxiliary_valve_number_04_estimated_flow_limit_status : 26|3@0+ (8.0,0.0) [0.0|7.0] "bit" Vector__XXX
 SG_ Auxiliary_valve_04_exit_reason_code : 39|6@0+ (64.0,0.0) [0.0|63.0] "bit" Vector__XXX
 SG_ Auxiliary_valve_04_estimated_flow_high_resolution : 55|16@0- (0.004,-125.0) [-100.0|100.0] "%" Vector__XXX

BO_ 2365461760 DD_AV05EF_65045: 8 DD_SOURCE
 SG_ Auxiliary_valve_number_05_extend_port_estimated_flow : 7|8@0- (1.0,-125.0) [-125.0|125.0] "%" Vector__XXX
 SG_ Auxiliary_valve_number_05_retract_port_estimated_flow : 15|8@0- (1.0,-125.0) [-125.0|125.0] "%" Vector__XXX
 SG_ Auxiliary_valve_number_05_valve_state : 23|4@0+ (16.0,0.0) [0.0|15.0] "bit" Vector__XXX
 SG_ Auxiliary_valve_05_fail_safe_mode : 17|2@0+ (4.0,0.0) [0.0|3.0] "bit" Vector__XXX
 SG_ Auxiliary_valve_number_05_estimated_flow_limit_status : 26|3@0+ (8.0,0.0) [0.0|7.0] "bit" Vector__XXX
 SG_ Auxiliary_valve_05_exit_reason_code : 39|6@0+ (64.0,0.0) [0.0|63.0] "bit" Vector__XXX
 SG_ Auxiliary_valve_05_estimated_flow_high_resolution : 55|16@0- (0.004,-125.0) [-100.0|100.0] "%" Vector__XXX

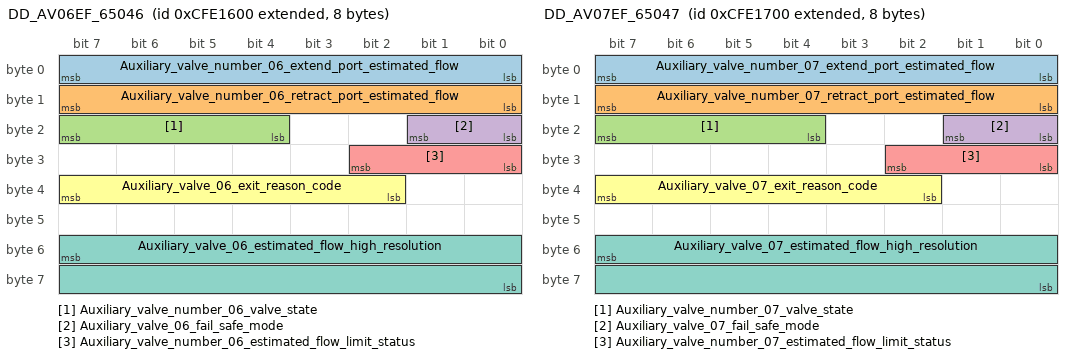
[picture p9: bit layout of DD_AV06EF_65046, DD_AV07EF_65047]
BO_ 2365462016 DD_AV06EF_65046: 8 DD_SOURCE
 SG_ Auxiliary_valve_number_06_extend_port_estimated_flow : 7|8@0- (1.0,-125.0) [-125.0|125.0] "%" Vector__XXX
 SG_ Auxiliary_valve_number_06_retract_port_estimated_flow : 15|8@0- (1.0,-125.0) [-125.0|125.0] "%" Vector__XXX
 SG_ Auxiliary_valve_number_06_valve_state : 23|4@0+ (16.0,0.0) [0.0|15.0] "bit" Vector__XXX
 SG_ Auxiliary_valve_06_fail_safe_mode : 17|2@0+ (4.0,0.0) [0.0|3.0] "bit" Vector__XXX
 SG_ Auxiliary_valve_number_06_estimated_flow_limit_status : 26|3@0+ (8.0,0.0) [0.0|7.0] "bit" Vector__XXX
 SG_ Auxiliary_valve_06_exit_reason_code : 39|6@0+ (64.0,0.0) [0.0|63.0] "bit" Vector__XXX
 SG_ Auxiliary_valve_06_estimated_flow_high_resolution : 55|16@0- (0.004,-125.0) [-100.0|100.0] "%" Vector__XXX

BO_ 2365462272 DD_AV07EF_65047: 8 DD_SOURCE
 SG_ Auxiliary_valve_number_07_extend_port_estimated_flow : 7|8@0- (1.0,-125.0) [-125.0|125.0] "%" Vector__XXX
 SG_ Auxiliary_valve_number_07_retract_port_estimated_flow : 15|8@0- (1.0,-125.0) [-125.0|125.0] "%" Vector__XXX
 SG_ Auxiliary_valve_number_07_valve_state : 23|4@0+ (16.0,0.0) [0.0|15.0] "bit" Vector__XXX
 SG_ Auxiliary_valve_07_fail_safe_mode : 17|2@0+ (4.0,0.0) [0.0|3.0] "bit" Vector__XXX
 SG_ Auxiliary_valve_number_07_estimated_flow_limit_status : 26|3@0+ (8.0,0.0) [0.0|7.0] "bit" Vector__XXX
 SG_ Auxiliary_valve_07_exit_reason_code : 39|6@0+ (64.0,0.0) [0.0|63.0] "bit" Vector__XXX
 SG_ Auxiliary_valve_07_estimated_flow_high_resolution : 55|16@0- (0.004,-125.0) [-100.0|100.0] "%" Vector__XXX

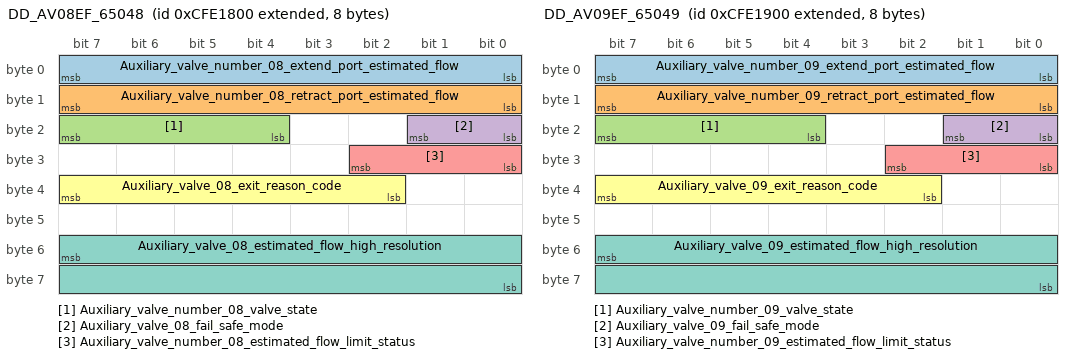
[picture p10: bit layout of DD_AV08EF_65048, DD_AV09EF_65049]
BO_ 2365462528 DD_AV08EF_65048: 8 DD_SOURCE
 SG_ Auxiliary_valve_number_08_extend_port_estimated_flow : 7|8@0- (1.0,-125.0) [-125.0|125.0] "%" Vector__XXX
 SG_ Auxiliary_valve_number_08_retract_port_estimated_flow : 15|8@0- (1.0,-125.0) [-125.0|125.0] "%" Vector__XXX
 SG_ Auxiliary_valve_number_08_valve_state : 23|4@0+ (16.0,0.0) [0.0|15.0] "bit" Vector__XXX
 SG_ Auxiliary_valve_08_fail_safe_mode : 17|2@0+ (4.0,0.0) [0.0|3.0] "bit" Vector__XXX
 SG_ Auxiliary_valve_number_08_estimated_flow_limit_status : 26|3@0+ (8.0,0.0) [0.0|7.0] "bit" Vector__XXX
 SG_ Auxiliary_valve_08_exit_reason_code : 39|6@0+ (64.0,0.0) [0.0|63.0] "bit" Vector__XXX
 SG_ Auxiliary_valve_08_estimated_flow_high_resolution : 55|16@0- (0.004,-125.0) [-100.0|100.0] "%" Vector__XXX

BO_ 2365462784 DD_AV09EF_65049: 8 DD_SOURCE
 SG_ Auxiliary_valve_number_09_extend_port_estimated_flow : 7|8@0- (1.0,-125.0) [-125.0|125.0] "%" Vector__XXX
 SG_ Auxiliary_valve_number_09_retract_port_estimated_flow : 15|8@0- (1.0,-125.0) [-125.0|125.0] "%" Vector__XXX
 SG_ Auxiliary_valve_number_09_valve_state : 23|4@0+ (16.0,0.0) [0.0|15.0] "bit" Vector__XXX
 SG_ Auxiliary_valve_09_fail_safe_mode : 17|2@0+ (4.0,0.0) [0.0|3.0] "bit" Vector__XXX
 SG_ Auxiliary_valve_number_09_estimated_flow_limit_status : 26|3@0+ (8.0,0.0) [0.0|7.0] "bit" Vector__XXX
 SG_ Auxiliary_valve_09_exit_reason_code : 39|6@0+ (64.0,0.0) [0.0|63.0] "bit" Vector__XXX
 SG_ Auxiliary_valve_09_estimated_flow_high_resolution : 55|16@0- (0.004,-125.0) [-100.0|100.0] "%" Vector__XXX

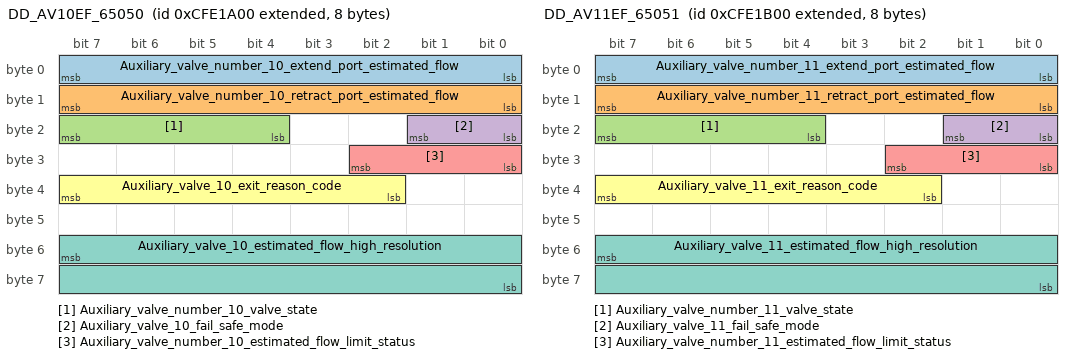
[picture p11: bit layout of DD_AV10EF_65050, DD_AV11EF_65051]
BO_ 2365463040 DD_AV10EF_65050: 8 DD_SOURCE
 SG_ Auxiliary_valve_number_10_extend_port_estimated_flow : 7|8@0- (1.0,-125.0) [-125.0|125.0] "%" Vector__XXX
 SG_ Auxiliary_valve_number_10_retract_port_estimated_flow : 15|8@0- (1.0,-125.0) [-125.0|125.0] "%" Vector__XXX
 SG_ Auxiliary_valve_number_10_valve_state : 23|4@0+ (16.0,0.0) [0.0|15.0] "bit" Vector__XXX
 SG_ Auxiliary_valve_10_fail_safe_mode : 17|2@0+ (4.0,0.0) [0.0|3.0] "bit" Vector__XXX
 SG_ Auxiliary_valve_number_10_estimated_flow_limit_status : 26|3@0+ (8.0,0.0) [0.0|7.0] "bit" Vector__XXX
 SG_ Auxiliary_valve_10_exit_reason_code : 39|6@0+ (64.0,0.0) [0.0|63.0] "bit" Vector__XXX
 SG_ Auxiliary_valve_10_estimated_flow_high_resolution : 55|16@0- (0.004,-125.0) [-100.0|100.0] "%" Vector__XXX

BO_ 2365463296 DD_AV11EF_65051: 8 DD_SOURCE
 SG_ Auxiliary_valve_number_11_extend_port_estimated_flow : 7|8@0- (1.0,-125.0) [-125.0|125.0] "%" Vector__XXX
 SG_ Auxiliary_valve_number_11_retract_port_estimated_flow : 15|8@0- (1.0,-125.0) [-125.0|125.0] "%" Vector__XXX
 SG_ Auxiliary_valve_number_11_valve_state : 23|4@0+ (16.0,0.0) [0.0|15.0] "bit" Vector__XXX
 SG_ Auxiliary_valve_11_fail_safe_mode : 17|2@0+ (4.0,0.0) [0.0|3.0] "bit" Vector__XXX
 SG_ Auxiliary_valve_number_11_estimated_flow_limit_status : 26|3@0+ (8.0,0.0) [0.0|7.0] "bit" Vector__XXX
 SG_ Auxiliary_valve_11_exit_reason_code : 39|6@0+ (64.0,0.0) [0.0|63.0] "bit" Vector__XXX
 SG_ Auxiliary_valve_11_estimated_flow_high_resolution : 55|16@0- (0.004,-125.0) [-100.0|100.0] "%" Vector__XXX

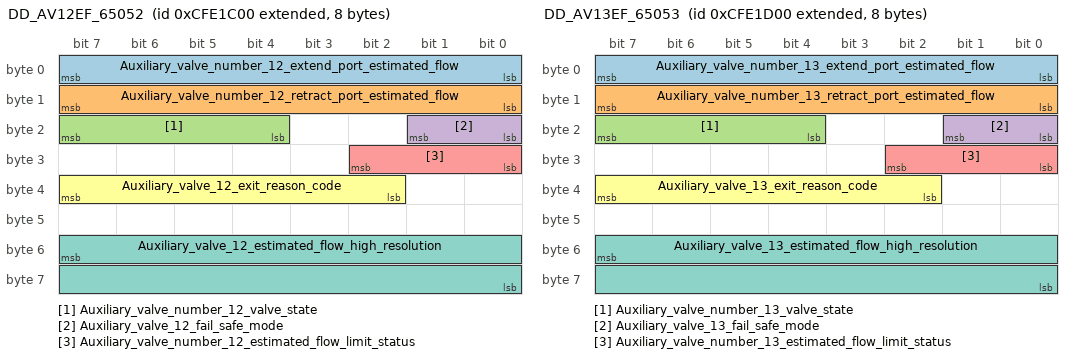
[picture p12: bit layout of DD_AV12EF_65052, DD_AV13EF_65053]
BO_ 2365463552 DD_AV12EF_65052: 8 DD_SOURCE
 SG_ Auxiliary_valve_number_12_extend_port_estimated_flow : 7|8@0- (1.0,-125.0) [-125.0|125.0] "%" Vector__XXX
 SG_ Auxiliary_valve_number_12_retract_port_estimated_flow : 15|8@0- (1.0,-125.0) [-125.0|125.0] "%" Vector__XXX
 SG_ Auxiliary_valve_number_12_valve_state : 23|4@0+ (16.0,0.0) [0.0|15.0] "bit" Vector__XXX
 SG_ Auxiliary_valve_12_fail_safe_mode : 17|2@0+ (4.0,0.0) [0.0|3.0] "bit" Vector__XXX
 SG_ Auxiliary_valve_number_12_estimated_flow_limit_status : 26|3@0+ (8.0,0.0) [0.0|7.0] "bit" Vector__XXX
 SG_ Auxiliary_valve_12_exit_reason_code : 39|6@0+ (64.0,0.0) [0.0|63.0] "bit" Vector__XXX
 SG_ Auxiliary_valve_12_estimated_flow_high_resolution : 55|16@0- (0.004,-125.0) [-100.0|100.0] "%" Vector__XXX

BO_ 2365463808 DD_AV13EF_65053: 8 DD_SOURCE
 SG_ Auxiliary_valve_number_13_extend_port_estimated_flow : 7|8@0- (1.0,-125.0) [-125.0|125.0] "%" Vector__XXX
 SG_ Auxiliary_valve_number_13_retract_port_estimated_flow : 15|8@0- (1.0,-125.0) [-125.0|125.0] "%" Vector__XXX
 SG_ Auxiliary_valve_number_13_valve_state : 23|4@0+ (16.0,0.0) [0.0|15.0] "bit" Vector__XXX
 SG_ Auxiliary_valve_13_fail_safe_mode : 17|2@0+ (4.0,0.0) [0.0|3.0] "bit" Vector__XXX
 SG_ Auxiliary_valve_number_13_estimated_flow_limit_status : 26|3@0+ (8.0,0.0) [0.0|7.0] "bit" Vector__XXX
 SG_ Auxiliary_valve_13_exit_reason_code : 39|6@0+ (64.0,0.0) [0.0|63.0] "bit" Vector__XXX
 SG_ Auxiliary_valve_13_estimated_flow_high_resolution : 55|16@0- (0.004,-125.0) [-100.0|100.0] "%" Vector__XXX

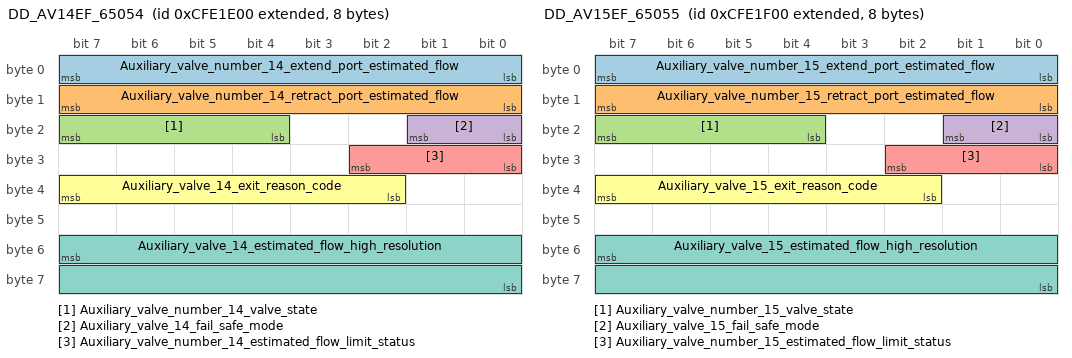
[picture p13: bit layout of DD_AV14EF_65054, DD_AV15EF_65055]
BO_ 2365464064 DD_AV14EF_65054: 8 DD_SOURCE
 SG_ Auxiliary_valve_number_14_extend_port_estimated_flow : 7|8@0- (1.0,-125.0) [-125.0|125.0] "%" Vector__XXX
 SG_ Auxiliary_valve_number_14_retract_port_estimated_flow : 15|8@0- (1.0,-125.0) [-125.0|125.0] "%" Vector__XXX
 SG_ Auxiliary_valve_number_14_valve_state : 23|4@0+ (16.0,0.0) [0.0|15.0] "bit" Vector__XXX
 SG_ Auxiliary_valve_14_fail_safe_mode : 17|2@0+ (4.0,0.0) [0.0|3.0] "bit" Vector__XXX
 SG_ Auxiliary_valve_number_14_estimated_flow_limit_status : 26|3@0+ (8.0,0.0) [0.0|7.0] "bit" Vector__XXX
 SG_ Auxiliary_valve_14_exit_reason_code : 39|6@0+ (64.0,0.0) [0.0|63.0] "bit" Vector__XXX
 SG_ Auxiliary_valve_14_estimated_flow_high_resolution : 55|16@0- (0.004,-125.0) [-100.0|100.0] "%" Vector__XXX

BO_ 2365464320 DD_AV15EF_65055: 8 DD_SOURCE
 SG_ Auxiliary_valve_number_15_extend_port_estimated_flow : 7|8@0- (1.0,-125.0) [-125.0|125.0] "%" Vector__XXX
 SG_ Auxiliary_valve_number_15_retract_port_estimated_flow : 15|8@0- (1.0,-125.0) [-125.0|125.0] "%" Vector__XXX
 SG_ Auxiliary_valve_number_15_valve_state : 23|4@0+ (16.0,0.0) [0.0|15.0] "bit" Vector__XXX
 SG_ Auxiliary_valve_15_fail_safe_mode : 17|2@0+ (4.0,0.0) [0.0|3.0] "bit" Vector__XXX
 SG_ Auxiliary_valve_number_15_estimated_flow_limit_status : 26|3@0+ (8.0,0.0) [0.0|7.0] "bit" Vector__XXX
 SG_ Auxiliary_valve_15_exit_reason_code : 39|6@0+ (64.0,0.0) [0.0|63.0] "bit" Vector__XXX
 SG_ Auxiliary_valve_15_estimated_flow_high_resolution : 55|16@0- (0.004,-125.0) [-100.0|100.0] "%" Vector__XXX

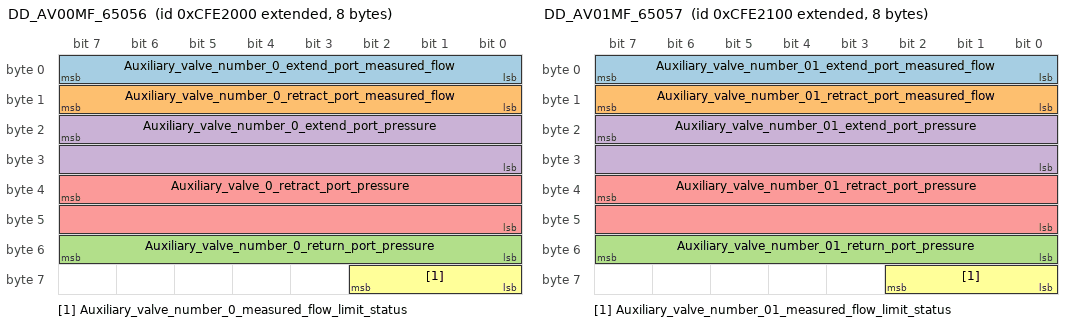
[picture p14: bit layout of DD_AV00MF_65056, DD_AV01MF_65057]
BO_ 2365464576 DD_AV00MF_65056: 8 DD_SOURCE
 SG_ Auxiliary_valve_number_0_extend_port_measured_flow : 7|8@0- (1.0,-125.0) [-125.0|125.0] "%" Vector__XXX
 SG_ Auxiliary_valve_number_0_retract_port_measured_flow : 15|8@0- (1.0,-125.0) [-125.0|125.0] "%" Vector__XXX
 SG_ Auxiliary_valve_number_0_return_port_pressure : 55|8@0+ (16.0,0.0) [0.0|4000.0] "kPa" Vector__XXX
 SG_ Auxiliary_valve_number_0_extend_port_pressure : 23|16@0+ (5.0,0.0) [0.0|321.0] "kPa" Vector__XXX
 SG_ Auxiliary_valve_0_retract_port_pressure : 39|16@0+ (5.0,0.0) [0.0|321.0] "kPa" Vector__XXX
 SG_ Auxiliary_valve_number_0_measured_flow_limit_status : 58|3@0+ (8.0,0.0) [0.0|7.0] "bit" Vector__XXX

BO_ 2365464832 DD_AV01MF_65057: 8 DD_SOURCE
 SG_ Auxiliary_valve_number_01_extend_port_measured_flow : 7|8@0- (1.0,-125.0) [-125.0|125.0] "%" Vector__XXX
 SG_ Auxiliary_valve_number_01_retract_port_measured_flow : 15|8@0- (1.0,-125.0) [-125.0|125.0] "%" Vector__XXX
 SG_ Auxiliary_valve_number_01_return_port_pressure : 55|8@0+ (16.0,0.0) [0.0|4000.0] "kPa" Vector__XXX
 SG_ Auxiliary_valve_number_01_extend_port_pressure : 23|16@0+ (5.0,0.0) [0.0|321.0] "kPa" Vector__XXX
 SG_ Auxiliary_valve_number_01_retract_port_pressure : 39|16@0+ (5.0,0.0) [0.0|321.0] "kPa" Vector__XXX
 SG_ Auxiliary_valve_number_01_measured_flow_limit_status : 58|3@0+ (8.0,0.0) [0.0|7.0] "bit" Vector__XXX

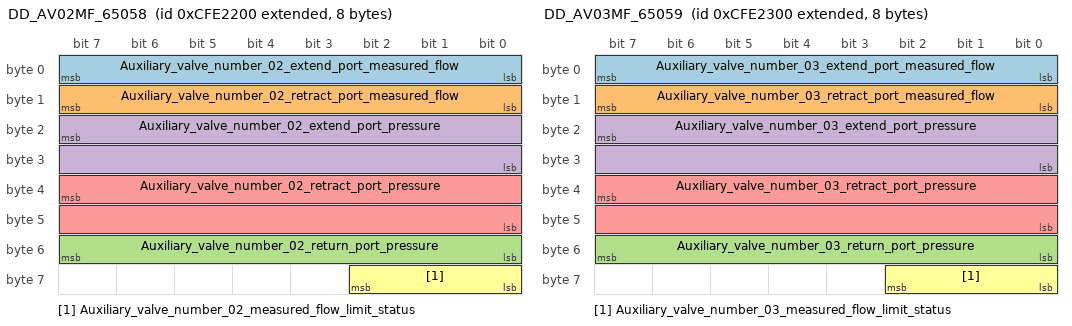
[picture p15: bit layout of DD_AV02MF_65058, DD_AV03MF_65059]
BO_ 2365465088 DD_AV02MF_65058: 8 DD_SOURCE
 SG_ Auxiliary_valve_number_02_extend_port_measured_flow : 7|8@0- (1.0,-125.0) [-125.0|125.0] "%" Vector__XXX
 SG_ Auxiliary_valve_number_02_retract_port_measured_flow : 15|8@0- (1.0,-125.0) [-125.0|125.0] "%" Vector__XXX
 SG_ Auxiliary_valve_number_02_return_port_pressure : 55|8@0+ (16.0,0.0) [0.0|4000.0] "kPa" Vector__XXX
 SG_ Auxiliary_valve_number_02_extend_port_pressure : 23|16@0+ (5.0,0.0) [0.0|321.0] "kPa" Vector__XXX
 SG_ Auxiliary_valve_number_02_retract_port_pressure : 39|16@0+ (5.0,0.0) [0.0|321.0] "kPa" Vector__XXX
 SG_ Auxiliary_valve_number_02_measured_flow_limit_status : 58|3@0+ (8.0,0.0) [0.0|7.0] "bit" Vector__XXX

BO_ 2365465344 DD_AV03MF_65059: 8 DD_SOURCE
 SG_ Auxiliary_valve_number_03_extend_port_measured_flow : 7|8@0- (1.0,-125.0) [-125.0|125.0] "%" Vector__XXX
 SG_ Auxiliary_valve_number_03_retract_port_measured_flow : 15|8@0- (1.0,-125.0) [-125.0|125.0] "%" Vector__XXX
 SG_ Auxiliary_valve_number_03_return_port_pressure : 55|8@0+ (16.0,0.0) [0.0|4000.0] "kPa" Vector__XXX
 SG_ Auxiliary_valve_number_03_extend_port_pressure : 23|16@0+ (5.0,0.0) [0.0|321.0] "kPa" Vector__XXX
 SG_ Auxiliary_valve_number_03_retract_port_pressure : 39|16@0+ (5.0,0.0) [0.0|321.0] "kPa" Vector__XXX
 SG_ Auxiliary_valve_number_03_measured_flow_limit_status : 58|3@0+ (8.0,0.0) [0.0|7.0] "bit" Vector__XXX

BO_ 2365465600 DD_AV04MF_65060: 8 DD_SOURCE
 SG_ Auxiliary_valve_number_04_extend_port_measured_flow : 7|8@0- (1.0,-125.0) [-125.0|125.0] "%" Vector__XXX
 SG_ Auxiliary_valve_number_04_retract_port_measured_flow : 15|8@0- (1.0,-125.0) [-125.0|125.0] "%" Vector__XXX
 SG_ Auxiliary_valve_number_04_return_port_pressure : 55|8@0+ (16.0,0.0) [0.0|4000.0] "kPa" Vector__XXX
 SG_ Auxiliary_valve_number_04_extend_port_pressure : 23|16@0+ (5.0,0.0) [0.0|321.0] "kPa" Vector__XXX
 SG_ Auxiliary_valve_number_04_retract_port_pressure : 39|16@0+ (5.0,0.0) [0.0|321.0] "kPa" Vector__XXX
 SG_ Auxiliary_valve_number_04_measured_flow_limit_status : 58|3@0+ (8.0,0.0) [0.0|7.0] "bit" Vector__XXX

BO_ 2365465856 DD_AV05MF_65061: 8 DD_SOURCE
 SG_ Auxiliary_valve_number_05_extend_port_measured_flow : 7|8@0- (1.0,-125.0) [-125.0|125.0] "%" Vector__XXX
 SG_ Auxiliary_valve_number_05_retract_port_measured_flow : 15|8@0- (1.0,-125.0) [-125.0|125.0] "%" Vector__XXX
 SG_ Auxiliary_valve_number_05_return_port_pressure : 55|8@0+ (16.0,0.0) [0.0|4000.0] "kPa" Vector__XXX
 SG_ Auxiliary_valve_number_05_extend_port_pressure : 23|16@0+ (5.0,0.0) [0.0|321.0] "kPa" Vector__XXX
 SG_ Auxiliary_valve_number_05_retract_port_pressure : 39|16@0+ (5.0,0.0) [0.0|321.0] "kPa" Vector__XXX
 SG_ Auxiliary_valve_number_05_measured_flow_limit_status : 58|3@0+ (8.0,0.0) [0.0|7.0] "bit" Vector__XXX

BO_ 2365466112 DD_AV06MF_65062: 8 DD_SOURCE
 SG_ Auxiliary_valve_number_06_extend_port_measured_flow : 7|8@0- (1.0,-125.0) [-125.0|125.0] "%" Vector__XXX
 SG_ Auxiliary_valve_number_06_retract_port_measured_flow : 15|8@0- (1.0,-125.0) [-125.0|125.0] "%" Vector__XXX
 SG_ Auxiliary_valve_number_06_return_port_pressure : 55|8@0+ (16.0,0.0) [0.0|4000.0] "kPa" Vector__XXX
 SG_ Auxiliary_valve_number_06_extend_port_pressure : 23|16@0+ (5.0,0.0) [0.0|321.0] "kPa" Vector__XXX
 SG_ Auxiliary_valve_number_06_retract_port_pressure : 39|16@0+ (5.0,0.0) [0.0|321.0] "kPa" Vector__XXX
 SG_ Auxiliary_valve_number_06_measured_flow_limit_status : 58|3@0+ (8.0,0.0) [0.0|7.0] "bit" Vector__XXX

BO_ 2365466368 DD_AV07MF_65063: 8 DD_SOURCE
 SG_ Auxiliary_valve_number_07_extend_port_measured_flow : 7|8@0- (1.0,-125.0) [-125.0|125.0] "%" Vector__XXX
 SG_ Auxiliary_valve_number_07_retract_port_measured_flow : 15|8@0- (1.0,-125.0) [-125.0|125.0] "%" Vector__XXX
 SG_ Auxiliary_valve_number_07_return_port_pressure : 55|8@0+ (16.0,0.0) [0.0|4000.0] "kPa" Vector__XXX
 SG_ Auxiliary_valve_number_07_extend_port_pressure : 23|16@0+ (5.0,0.0) [0.0|321.0] "kPa" Vector__XXX
 SG_ Auxiliary_valve_number_07_retract_port_pressure : 39|16@0+ (5.0,0.0) [0.0|321.0] "kPa" Vector__XXX
 SG_ Auxiliary_valve_number_07_measured_flow_limit_status : 58|3@0+ (8.0,0.0) [0.0|7.0] "bit" Vector__XXX

BO_ 2365466624 DD_AV08MF_65064: 8 DD_SOURCE
 SG_ Auxiliary_valve_number_08_extend_port_measured_flow : 7|8@0- (1.0,-125.0) [-125.0|125.0] "%" Vector__XXX
 SG_ Auxiliary_valve_number_08_retract_port_measured_flow : 15|8@0- (1.0,-125.0) [-125.0|125.0] "%" Vector__XXX
 SG_ Auxiliary_valve_number_08_return_port_pressure : 55|8@0+ (16.0,0.0) [0.0|4000.0] "kPa" Vector__XXX
 SG_ Auxiliary_valve_number_08_extend_port_pressure : 23|16@0+ (5.0,0.0) [0.0|321.0] "kPa" Vector__XXX
 SG_ Auxiliary_valve_number_08_retract_port_pressure : 39|16@0+ (5.0,0.0) [0.0|321.0] "kPa" Vector__XXX
 SG_ Auxiliary_valve_number_08_measured_flow_limit_status : 58|3@0+ (8.0,0.0) [0.0|7.0] "bit" Vector__XXX

BO_ 2365466880 DD_AV09MF_65065: 8 DD_SOURCE
 SG_ Auxiliary_valve_number_09_extend_port_measured_flow : 7|8@0- (1.0,-125.0) [-125.0|125.0] "%" Vector__XXX
 SG_ Auxiliary_valve_number_09_retract_port_measured_flow : 15|8@0- (1.0,-125.0) [-125.0|125.0] "%" Vector__XXX
 SG_ Auxiliary_valve_number_09_return_port_pressure : 55|8@0+ (16.0,0.0) [0.0|4000.0] "kPa" Vector__XXX
 SG_ Auxiliary_valve_number_09_extend_port_pressure : 23|16@0+ (5.0,0.0) [0.0|321.0] "kPa" Vector__XXX
 SG_ Auxiliary_valve_number_09_retract_port_pressure : 39|16@0+ (5.0,0.0) [0.0|321.0] "kPa" Vector__XXX
 SG_ Auxiliary_valve_number_09_measured_flow_limit_status : 58|3@0+ (8.0,0.0) [0.0|7.0] "bit" Vector__XXX

BO_ 2365467136 DD_AV10MF_65066: 8 DD_SOURCE
 SG_ Auxiliary_valve_number_10_extend_port_measured_flow : 7|8@0- (1.0,-125.0) [-125.0|125.0] "%" Vector__XXX
 SG_ Auxiliary_valve_number_10_retract_port_measured_flow : 15|8@0- (1.0,-125.0) [-125.0|125.0] "%" Vector__XXX
 SG_ Auxiliary_valve_number_10_return_port_pressure : 55|8@0+ (16.0,0.0) [0.0|4000.0] "kPa" Vector__XXX
 SG_ Auxiliary_valve_number_10_extend_port_pressure : 23|16@0+ (5.0,0.0) [0.0|321.0] "kPa" Vector__XXX
 SG_ Auxiliary_valve_number_10_retract_port_pressure : 39|16@0+ (5.0,0.0) [0.0|321.0] "kPa" Vector__XXX
 SG_ Auxiliary_valve_number_10_measured_flow_limit_status : 58|3@0+ (8.0,0.0) [0.0|7.0] "bit" Vector__XXX

BO_ 2365467392 DD_AV11MF_65067: 8 DD_SOURCE
 SG_ Auxiliary_valve_number_11_extend_port_measured_flow : 7|8@0- (1.0,-125.0) [-125.0|125.0] "%" Vector__XXX
 SG_ Auxiliary_valve_number_11_retract_port_measured_flow : 15|8@0- (1.0,-125.0) [-125.0|125.0] "%" Vector__XXX
 SG_ Auxiliary_valve_number_11_return_port_pressure : 55|8@0+ (16.0,0.0) [0.0|4000.0] "kPa" Vector__XXX
 SG_ Auxiliary_valve_number_11_extend_port_pressure : 23|16@0+ (5.0,0.0) [0.0|321.0] "kPa" Vector__XXX
 SG_ Auxiliary_valve_number_11_retract_port_pressure : 39|16@0+ (5.0,0.0) [0.0|321.0] "kPa" Vector__XXX
 SG_ Auxiliary_valve_number_11_measured_flow_limit_status : 58|3@0+ (8.0,0.0) [0.0|7.0] "bit" Vector__XXX

BO_ 2365467648 DD_AV12MF_65068: 8 DD_SOURCE
 SG_ Auxiliary_valve_number_12_extend_port_measured_flow : 7|8@0- (1.0,-125.0) [-125.0|125.0] "%" Vector__XXX
 SG_ Auxiliary_valve_number_12_retract_port_measured_flow : 15|8@0- (1.0,-125.0) [-125.0|125.0] "%" Vector__XXX
 SG_ Auxiliary_valve_number_12_return_port_pressure : 55|8@0+ (16.0,0.0) [0.0|4000.0] "kPa" Vector__XXX
 SG_ Auxiliary_valve_number_12_extend_port_pressure : 23|16@0+ (5.0,0.0) [0.0|321.0] "kPa" Vector__XXX
 SG_ Auxiliary_valve_number_12_retract_port_pressure : 39|16@0+ (5.0,0.0) [0.0|321.0] "kPa" Vector__XXX
 SG_ Auxiliary_valve_number_12_measured_flow_limit_status : 58|3@0+ (8.0,0.0) [0.0|7.0] "bit" Vector__XXX

BO_ 2365467904 DD_AV13MF_65069: 8 DD_SOURCE
 SG_ Auxiliary_valve_number_13_extend_port_measured_flow : 7|8@0- (1.0,-125.0) [-125.0|125.0] "%" Vector__XXX
 SG_ Auxiliary_valve_number_13_retract_port_measured_flow : 15|8@0- (1.0,-125.0) [-125.0|125.0] "%" Vector__XXX
 SG_ Auxiliary_valve_number_13_return_port_pressure : 55|8@0+ (16.0,0.0) [0.0|4000.0] "kPa" Vector__XXX
 SG_ Auxiliary_valve_number_13_extend_port_pressure : 23|16@0+ (5.0,0.0) [0.0|321.0] "kPa" Vector__XXX
 SG_ Auxiliary_valve_number_13_retract_port_pressure : 39|16@0+ (5.0,0.0) [0.0|321.0] "kPa" Vector__XXX
 SG_ Auxiliary_valve_number_13_measured_flow_limit_status : 58|3@0+ (8.0,0.0) [0.0|7.0] "bit" Vector__XXX

BO_ 2365468160 DD_AV14MF_65070: 8 DD_SOURCE
 SG_ Auxiliary_valve_number_14_extend_port_measured_flow : 7|8@0- (1.0,-125.0) [-125.0|125.0] "%" Vector__XXX
 SG_ Auxiliary_valve_number_14_retract_port_measured_flow : 15|8@0- (1.0,-125.0) [-125.0|125.0] "%" Vector__XXX
 SG_ Auxiliary_valve_number_14_return_port_pressure : 55|8@0+ (16.0,0.0) [0.0|4000.0] "kPa" Vector__XXX
 SG_ Auxiliary_valve_number_14_extend_port_pressure : 23|16@0+ (5.0,0.0) [0.0|321.0] "kPa" Vector__XXX
 SG_ Auxiliary_valve_number_14_retract_port_pressure : 39|16@0+ (5.0,0.0) [0.0|321.0] "kPa" Vector__XXX
 SG_ Auxiliary_valve_number_14_measured_flow_limit_status : 58|3@0+ (8.0,0.0) [0.0|7.0] "bit" Vector__XXX

BO_ 2365468416 DD_AV15MF_65071: 8 DD_SOURCE
 SG_ Auxiliary_valve_number_15_extend_port_measured_flow : 7|8@0- (1.0,-125.0) [-125.0|125.0] "%" Vector__XXX
 SG_ Auxiliary_valve_number_15_retract_port_measured_flow : 15|8@0- (1.0,-125.0) [-125.0|125.0] "%" Vector__XXX
 SG_ Auxiliary_valve_number_15_return_port_pressure : 55|8@0+ (16.0,0.0) [0.0|4000.0] "kPa" Vector__XXX
 SG_ Auxiliary_valve_number_15_extend_port_pressure : 23|16@0+ (5.0,0.0) [0.0|321.0] "kPa" Vector__XXX
 SG_ Auxiliary_valve_number_15_retract_port_pressure : 39|16@0+ (5.0,0.0) [0.0|321.0] "kPa" Vector__XXX
 SG_ Auxiliary_valve_number_15_measured_flow_limit_status : 58|3@0+ (8.0,0.0) [0.0|7.0] "bit" Vector__XXX

BO_ 2365468672 DD_AV00C_65072: 8 DD_SOURCE
 SG_ Auxiliary_valve_number_0_port_flow_Command : 7|8@0+ (0.4,0.0) [0.0|100.0] "%" Vector__XXX
 SG_ Auxiliary_valve_number_0_Resolution_mode_Command : 15|2@0+ (4.0,0.0) [0.0|3.0] "bit" Vector__XXX
 SG_ Auxiliary_valve_number_0_state_Command : 23|4@0+ (16.0,0.0) [0.0|15.0] "bit" Vector__XXX
 SG_ Auxiliary_valve_number_0_fail_safe_mode_Command : 17|2@0+ (4.0,0.0) [0.0|3.0] "bit" Vector__XXX
 SG_ Auxiliary_valve_number_0_port_flow_Extended_Resolution_Command : 31|16@0+ (0.0015625,0.0) [0.0|100.0] "%" Vector__XXX

BO_ 2365468928 DD_AV01C_65073: 8 DD_SOURCE
 SG_ Auxiliary_valve_number_1_port_flow_Command : 7|8@0+ (0.4,0.0) [0.0|100.0] "%" Vector__XXX
 SG_ Auxiliary_valve_number_1_Resolution_mode_Command : 15|2@0+ (4.0,0.0) [0.0|3.0] "bit" Vector__XXX
 SG_ Auxiliary_valve_number_1_state_Command : 23|4@0+ (16.0,0.0) [0.0|15.0] "bit" Vector__XXX
 SG_ Auxiliary_valve_number_1_fail_safe_mode_Command : 17|2@0+ (4.0,0.0) [0.0|3.0] "bit" Vector__XXX
 SG_ Auxiliary_valve_number_1_port_flow_Extended_Resolution_Command : 31|16@0+ (0.0015625,0.0) [0.0|100.0] "%" Vector__XXX

BO_ 2365469184 DD_AV02C_65074: 8 DD_SOURCE
 SG_ Auxiliary_valve_number_2_port_flow_Command : 7|8@0+ (0.4,0.0) [0.0|100.0] "%" Vector__XXX
 SG_ Auxiliary_valve_number_2_Resolution_mode_Command : 15|2@0+ (4.0,0.0) [0.0|3.0] "bit" Vector__XXX
 SG_ Auxiliary_valve_number_2_state_Command : 23|4@0+ (16.0,0.0) [0.0|15.0] "bit" Vector__XXX
 SG_ Auxiliary_valve_number_2_fail_safe_mode_Command : 17|2@0+ (4.0,0.0) [0.0|3.0] "bit" Vector__XXX
 SG_ Auxiliary_valve_number_2_port_flow_Extended_Resolution_Command : 31|16@0+ (0.0015625,0.0) [0.0|100.0] "%" Vector__XXX

BO_ 2365469440 DD_AV03C_65075: 8 DD_SOURCE
 SG_ Auxiliary_valve_number_3_port_flow_Command : 7|8@0+ (0.4,0.0) [0.0|100.0] "%" Vector__XXX
 SG_ Auxiliary_valve_number_3_Resolution_mode_Command : 15|2@0+ (4.0,0.0) [0.0|3.0] "bit" Vector__XXX
 SG_ Auxiliary_valve_number_3_state_Command : 23|4@0+ (16.0,0.0) [0.0|15.0] "bit" Vector__XXX
 SG_ Auxiliary_valve_number_3_fail_safe_mode_Command : 17|2@0+ (4.0,0.0) [0.0|3.0] "bit" Vector__XXX
 SG_ Auxiliary_valve_number_3_port_flow_Extended_Resolution_Command : 31|16@0+ (0.0015625,0.0) [0.0|100.0] "%" Vector__XXX

BO_ 2365469696 DD_AV04C_65076: 8 DD_SOURCE
 SG_ Auxiliary_valve_number_4_port_flow_Command : 7|8@0+ (0.4,0.0) [0.0|100.0] "%" Vector__XXX
 SG_ Auxiliary_valve_number_4_Resolution_mode_Command : 15|2@0+ (4.0,0.0) [0.0|3.0] "bit" Vector__XXX
 SG_ Auxiliary_valve_number_4_state_Command : 23|4@0+ (16.0,0.0) [0.0|15.0] "bit" Vector__XXX
 SG_ Auxiliary_valve_number_4_fail_safe_mode_Command : 17|2@0+ (4.0,0.0) [0.0|3.0] "bit" Vector__XXX
 SG_ Auxiliary_valve_number_4_port_flow_Extended_Resolution_Command : 31|16@0+ (0.0015625,0.0) [0.0|100.0] "%" Vector__XXX

BO_ 2365469952 DD_AV05C_65077: 8 DD_SOURCE
 SG_ Auxiliary_valve_number_5_port_flow_Command : 7|8@0+ (0.4,0.0) [0.0|100.0] "%" Vector__XXX
 SG_ Auxiliary_valve_number_5_Resolution_mode_Command : 15|2@0+ (4.0,0.0) [0.0|3.0] "bit" Vector__XXX
 SG_ Auxiliary_valve_number_5_state_Command : 23|4@0+ (16.0,0.0) [0.0|15.0] "bit" Vector__XXX
 SG_ Auxiliary_valve_number_5_fail_safe_mode_Command : 17|2@0+ (4.0,0.0) [0.0|3.0] "bit" Vector__XXX
 SG_ Auxiliary_valve_number_5_port_flow_Extended_Resolution_Command : 31|16@0+ (0.0015625,0.0) [0.0|100.0] "%" Vector__XXX

BO_ 2365470208 DD_AV06C_65078: 8 DD_SOURCE
 SG_ Auxiliary_valve_number_6_port_flow_Command : 7|8@0+ (0.4,0.0) [0.0|100.0] "%" Vector__XXX
 SG_ Auxiliary_valve_number_6_Resolution_mode_Command : 15|2@0+ (4.0,0.0) [0.0|3.0] "bit" Vector__XXX
 SG_ Auxiliary_valve_number_6_state_Command : 23|4@0+ (16.0,0.0) [0.0|15.0] "bit" Vector__XXX
 SG_ Auxiliary_valve_number_6_fail_safe_mode_Command : 17|2@0+ (4.0,0.0) [0.0|3.0] "bit" Vector__XXX
 SG_ Auxiliary_valve_number_6_port_flow_Extended_Resolution_Command : 31|16@0+ (0.0015625,0.0) [0.0|100.0] "%" Vector__XXX

BO_ 2365470464 DD_AV07C_65079: 8 DD_SOURCE
 SG_ Auxiliary_valve_number_7_port_flow_Command : 7|8@0+ (0.4,0.0) [0.0|100.0] "%" Vector__XXX
 SG_ Auxiliary_valve_number_7_Resolution_mode_Command : 15|2@0+ (4.0,0.0) [0.0|3.0] "bit" Vector__XXX
 SG_ Auxiliary_valve_number_7_state_Command : 23|4@0+ (16.0,0.0) [0.0|15.0] "bit" Vector__XXX
 SG_ Auxiliary_valve_number_7_fail_safe_mode_Command : 17|2@0+ (4.0,0.0) [0.0|3.0] "bit" Vector__XXX
 SG_ Auxiliary_valve_number_7_port_flow_Extended_Resolution_Command : 31|16@0+ (0.0015625,0.0) [0.0|100.0] "%" Vector__XXX

BO_ 2365470720 DD_AV08C_65080: 8 DD_SOURCE
 SG_ Auxiliary_valve_number_8_port_flow_Command : 7|8@0+ (0.4,0.0) [0.0|100.0] "%" Vector__XXX
 SG_ Auxiliary_valve_number_8_Resolution_mode_Command : 15|2@0+ (4.0,0.0) [0.0|3.0] "bit" Vector__XXX
 SG_ Auxiliary_valve_number_8_state_Command : 23|4@0+ (16.0,0.0) [0.0|15.0] "bit" Vector__XXX
 SG_ Auxiliary_valve_number_8_fail_safe_mode_Command : 17|2@0+ (4.0,0.0) [0.0|3.0] "bit" Vector__XXX
 SG_ Auxiliary_valve_number_8_port_flow_Extended_Resolution_Command : 31|16@0+ (0.0015625,0.0) [0.0|100.0] "%" Vector__XXX

BO_ 2365470976 DD_AV09C_65081: 8 DD_SOURCE
 SG_ Auxiliary_valve_number_9_port_flow_Command : 7|8@0+ (0.4,0.0) [0.0|100.0] "%" Vector__XXX
 SG_ Auxiliary_valve_number_9_Resolution_mode_Command : 15|2@0+ (4.0,0.0) [0.0|3.0] "bit" Vector__XXX
 SG_ Auxiliary_valve_number_9_state_Command : 23|4@0+ (16.0,0.0) [0.0|15.0] "bit" Vector__XXX
 SG_ Auxiliary_valve_number_9_fail_safe_mode_Command : 17|2@0+ (4.0,0.0) [0.0|3.0] "bit" Vector__XXX
 SG_ Auxiliary_valve_number_9_port_flow_Extended_Resolution_Command : 31|16@0+ (0.0015625,0.0) [0.0|100.0] "%" Vector__XXX

BO_ 2365471232 DD_AV10C_65082: 8 DD_SOURCE
 SG_ Auxiliary_valve_number_10_port_flow_Command : 7|8@0+ (0.4,0.0) [0.0|100.0] "%" Vector__XXX
 SG_ Auxiliary_valve_number_10_Resolution_mode_Command : 15|2@0+ (4.0,0.0) [0.0|3.0] "bit" Vector__XXX
 SG_ Auxiliary_valve_number_10_state_Command : 23|4@0+ (16.0,0.0) [0.0|15.0] "bit" Vector__XXX
 SG_ Auxiliary_valve_number_10_fail_safe_mode_Command : 17|2@0+ (4.0,0.0) [0.0|3.0] "bit" Vector__XXX
 SG_ Auxiliary_valve_number_10_port_flow_Extended_Resolution_Command : 31|16@0+ (0.0015625,0.0) [0.0|100.0] "%" Vector__XXX

BO_ 2365471488 DD_AV11C_65083: 8 DD_SOURCE
 SG_ Auxiliary_valve_number_11_port_flow_Command : 7|8@0+ (0.4,0.0) [0.0|100.0] "%" Vector__XXX
 SG_ Auxiliary_valve_number_11_Resolution_mode_Command : 15|2@0+ (4.0,0.0) [0.0|3.0] "bit" Vector__XXX
 SG_ Auxiliary_valve_number_11_state_Command : 23|4@0+ (16.0,0.0) [0.0|15.0] "bit" Vector__XXX
 SG_ Auxiliary_valve_number_11_fail_safe_mode_Command : 17|2@0+ (4.0,0.0) [0.0|3.0] "bit" Vector__XXX
 SG_ Auxiliary_valve_number_11_port_flow_Extended_Resolution_Command : 31|16@0+ (0.0015625,0.0) [0.0|100.0] "%" Vector__XXX

BO_ 2365471744 DD_AV12C_65084: 8 DD_SOURCE
 SG_ Auxiliary_valve_number_12_port_flow_Command : 7|8@0+ (0.4,0.0) [0.0|100.0] "%" Vector__XXX
 SG_ Auxiliary_valve_number_12_Resolution_mode_Command : 15|2@0+ (4.0,0.0) [0.0|3.0] "bit" Vector__XXX
 SG_ Auxiliary_valve_number_12_state_Command : 23|4@0+ (16.0,0.0) [0.0|15.0] "bit" Vector__XXX
 SG_ Auxiliary_valve_number_12_fail_safe_mode_Command : 17|2@0+ (4.0,0.0) [0.0|3.0] "bit" Vector__XXX
 SG_ Auxiliary_valve_number_12_port_flow_Extended_Resolution_Command : 31|16@0+ (0.0015625,0.0) [0.0|100.0] "%" Vector__XXX

BO_ 2365472000 DD_AV13C_65085: 8 DD_SOURCE
 SG_ Auxiliary_valve_number_13_port_flow_Command : 7|8@0+ (0.4,0.0) [0.0|100.0] "%" Vector__XXX
 SG_ Auxiliary_valve_number_13_Resolution_mode_Command : 15|2@0+ (4.0,0.0) [0.0|3.0] "bit" Vector__XXX
 SG_ Auxiliary_valve_number_13_state_Command : 23|4@0+ (16.0,0.0) [0.0|15.0] "bit" Vector__XXX
 SG_ Auxiliary_valve_number_13_fail_safe_mode_Command : 17|2@0+ (4.0,0.0) [0.0|3.0] "bit" Vector__XXX
 SG_ Auxiliary_valve_number_13_port_flow_Extended_Resolution_Command : 31|16@0+ (0.0015625,0.0) [0.0|100.0] "%" Vector__XXX

BO_ 2365472256 DD_AV14C_65086: 8 DD_SOURCE
 SG_ Auxiliary_valve_number_14_port_flow_Command : 7|8@0+ (0.4,0.0) [0.0|100.0] "%" Vector__XXX
 SG_ Auxiliary_valve_number_14_Resolution_mode_Command : 15|2@0+ (4.0,0.0) [0.0|3.0] "bit" Vector__XXX
 SG_ Auxiliary_valve_number_14_state_Command : 23|4@0+ (16.0,0.0) [0.0|15.0] "bit" Vector__XXX
 SG_ Auxiliary_valve_number_14_fail_safe_mode_Command : 17|2@0+ (4.0,0.0) [0.0|3.0] "bit" Vector__XXX
 SG_ Auxiliary_valve_number_14_port_flow_Extended_Resolution_Command : 31|16@0+ (0.0015625,0.0) [0.0|100.0] "%" Vector__XXX

BO_ 2365472512 DD_AV15C_65087: 8 DD_SOURCE
 SG_ Auxiliary_valve_number_15_port_flow_Command : 7|8@0+ (0.4,0.0) [0.0|100.0] "%" Vector__XXX
 SG_ Auxiliary_valve_number_15_Resolution_mode_Command : 15|2@0+ (4.0,0.0) [0.0|3.0] "bit" Vector__XXX
 SG_ Auxiliary_valve_number_15_state_Command : 23|4@0+ (16.0,0.0) [0.0|15.0] "bit" Vector__XXX
 SG_ Auxiliary_valve_number_15_fail_safe_mode_Command : 17|2@0+ (4.0,0.0) [0.0|3.0] "bit" Vector__XXX
 SG_ Auxiliary_valve_number_15_port_flow_Extended_Resolution_Command : 31|16@0+ (0.0015625,0.0) [0.0|100.0] "%" Vector__XXX

BO_ 2566799360 DD_LD_65088: 8 DD_SOURCE
 SG_ Daytime_running_lights : 7|2@0+ (4.0,0.0) [0.0|3.0] "bit" Vector__XXX
 SG_ Alternate_headlights : 5|2@0+ (4.0,0.0) [0.0|3.0] "bit" Vector__XXX
 SG_ Low_beam_headlights : 3|2@0+ (4.0,0.0) [0.0|3.0] "bit" Vector__XXX
 SG_ High_beam_headlights : 1|2@0+ (4.0,0.0) [0.0|3.0] "bit" Vector__XXX
 SG_ Tractor_front_fog_lights : 15|2@0+ (4.0,0.0) [0.0|3.0] "bit" Vector__XXX
 SG_ Rotating_beacon_light : 13|2@0+ (4.0,0.0) [0.0|3.0] "bit" Vector__XXX
 SG_ Right_turn_signal_lights : 11|2@0+ (4.0,0.0) [0.0|3.0] "bit" Vector__XXX
 SG_ Left_turn_signal_lights : 9|2@0+ (4.0,0.0) [0.0|3.0] "bit" Vector__XXX
 SG_ Back_up_lights_and_alarm_horn : 23|2@0+ (4.0,0.0) [0.0|3.0] "bit" Vector__XXX
 SG_ Center_stop_lights : 21|2@0+ (4.0,0.0) [0.0|3.0] "bit" Vector__XXX
 SG_ Right_stop_lights : 19|2@0+ (4.0,0.0) [0.0|3.0] "bit" Vector__XXX
 SG_ Left_stop_lights : 17|2@0+ (4.0,0.0) [0.0|3.0] "bit" Vector__XXX
 SG_ Implement_clearance_lights : 31|2@0+ (4.0,0.0) [0.0|3.0] "bit" Vector__XXX
 SG_ Tractor_clearance_lights : 29|2@0+ (4.0,0.0) [0.0|3.0] "bit" Vector__XXX
 SG_ Implement_marker_position_lights : 27|2@0+ (4.0,0.0) [0.0|3.0] "bit" Vector__XXX
 SG_ Tractor_marker_position_lights : 25|2@0+ (4.0,0.0) [0.0|3.0] "bit" Vector__XXX
 SG_ Rear_fog_lights : 39|2@0+ (4.0,0.0) [0.0|3.0] "bit" Vector__XXX
 SG_ Tractor_underside_mounted_work_lights : 37|2@0+ (4.0,0.0) [0.0|3.0] "bit" Vector__XXX
 SG_ Tractor_rear_low_mounted_work_lights : 35|2@0+ (4.0,0.0) [0.0|3.0] "bit" Vector__XXX
 SG_ Tractor_rear_high_mounted_work_lights : 33|2@0+ (4.0,0.0) [0.0|3.0] "bit" Vector__XXX
 SG_ Tractor_side_low_mounted_work_lights : 47|2@0+ (4.0,0.0) [0.0|3.0] "bit" Vector__XXX
 SG_ Tractor_side_high_mounted_work_lights : 45|2@0+ (4.0,0.0) [0.0|3.0] "bit" Vector__XXX
 SG_ Tractor_front_low_mounted_work_lights : 43|2@0+ (4.0,0.0) [0.0|3.0] "bit" Vector__XXX
 SG_ Tractor_front_high_mounted_work_lights : 41|2@0+ (4.0,0.0) [0.0|3.0] "bit" Vector__XXX
 SG_ Implement_OEM_option_2_light : 55|2@0+ (4.0,0.0) [0.0|3.0] "bit" Vector__XXX
 SG_ Implement_OEM_option_1_light : 53|2@0+ (4.0,0.0) [0.0|3.0] "bit" Vector__XXX
 SG_ Implement_right_forward_work_lights : 51|2@0+ (4.0,0.0) [0.0|3.0] "bit" Vector__XXX
 SG_ Implement_left_forward_work_lights : 49|2@0+ (4.0,0.0) [0.0|3.0] "bit" Vector__XXX
 SG_ Implement_right_facing_work_lights : 61|2@0+ (4.0,0.0) [0.0|3.0] "bit" Vector__XXX
 SG_ Implement_left_facing_work_lights : 59|2@0+ (4.0,0.0) [0.0|3.0] "bit" Vector__XXX
 SG_ Implement_rear_work_lights : 57|2@0+ (4.0,0.0) [0.0|3.0] "bit" Vector__XXX

BO_ 2365473024 DD_LCMD_65089: 8 DD_SOURCE
 SG_ Daytime_running_lights_Command : 7|2@0+ (4.0,0.0) [0.0|3.0] "bit" Vector__XXX
 SG_ Alternate_headlights_Command : 5|2@0+ (4.0,0.0) [0.0|3.0] "bit" Vector__XXX
 SG_ Low_beam_headlights_Command : 3|2@0+ (4.0,0.0) [0.0|3.0] "bit" Vector__XXX
 SG_ High_beam_headlights_Command : 1|2@0+ (4.0,0.0) [0.0|3.0] "bit" Vector__XXX
 SG_ Tractor_front_fog_lights_Command : 15|2@0+ (4.0,0.0) [0.0|3.0] "bit" Vector__XXX
 SG_ Rotating_beacon_light_Command : 13|2@0+ (4.0,0.0) [0.0|3.0] "bit" Vector__XXX
 SG_ Right_turn_signal_lights_Command : 11|2@0+ (4.0,0.0) [0.0|3.0] "bit" Vector__XXX
 SG_ Left_turn_signal_lights_Command : 9|2@0+ (4.0,0.0) [0.0|3.0] "bit" Vector__XXX
 SG_ Back_up_lights_and_alarm_horn_Command : 23|2@0+ (4.0,0.0) [0.0|3.0] "bit" Vector__XXX
 SG_ Centre_stop_lights_Command : 21|2@0+ (4.0,0.0) [0.0|3.0] "bit" Vector__XXX
 SG_ Right_stop_lights_Command : 19|2@0+ (4.0,0.0) [0.0|3.0] "bit" Vector__XXX
 SG_ Left_stop_lights_Command : 17|2@0+ (4.0,0.0) [0.0|3.0] "bit" Vector__XXX
 SG_ Implement_clearance_lights_Command : 31|2@0+ (4.0,0.0) [0.0|3.0] "bit" Vector__XXX
 SG_ Tractor_clearance_lights_Command : 29|2@0+ (4.0,0.0) [0.0|3.0] "bit" Vector__XXX
 SG_ Implement_marker_position_lights_Command : 27|2@0+ (4.0,0.0) [0.0|3.0] "bit" Vector__XXX
 SG_ Tractor_marker_position_lights_Command : 25|2@0+ (4.0,0.0) [0.0|3.0] "bit" Vector__XXX
 SG_ Rear_fog_lights_Command : 39|2@0+ (4.0,0.0) [0.0|3.0] "bit" Vector__XXX
 SG_ Tractor_underside_mounted_work_lights_Command : 37|2@0+ (4.0,0.0) [0.0|3.0] "bit" Vector__XXX
 SG_ Tractor_rear_low_mounted_work_lights_Command : 35|2@0+ (4.0,0.0) [0.0|3.0] "bit" Vector__XXX
 SG_ Tractor_rear_high_mounted_work_lights_Command : 33|2@0+ (4.0,0.0) [0.0|3.0] "bit" Vector__XXX
 SG_ Tractor_side_low_mounted_work_lights_Command : 47|2@0+ (4.0,0.0) [0.0|3.0] "bit" Vector__XXX
 SG_ Tractor_side_high_mounted_work_lights_Command : 45|2@0+ (4.0,0.0) [0.0|3.0] "bit" Vector__XXX
 SG_ Tractor_front_low_mounted_work_lights_Command : 43|2@0+ (4.0,0.0) [0.0|3.0] "bit" Vector__XXX
 SG_ Tractor_front_high_mounted_work_lights_Command : 41|2@0+ (4.0,0.0) [0.0|3.0] "bit" Vector__XXX
 SG_ Implement_OEM_option_2_light_Command : 55|2@0+ (4.0,0.0) [0.0|3.0] "bit" Vector__XXX
 SG_ Implement_OEM_option_1_light_Command : 53|2@0+ (4.0,0.0) [0.0|3.0] "bit" Vector__XXX
 SG_ Implement_right_forward_work_lights_Command : 51|2@0+ (4.0,0.0) [0.0|3.0] "bit" Vector__XXX
 SG_ Implement_left_forward_work_lights_Command : 49|2@0+ (4.0,0.0) [0.0|3.0] "bit" Vector__XXX
 SG_ Lighting_data_message_request_Command : 63|2@0+ (4.0,0.0) [0.0|3.0] "bit" Vector__XXX
 SG_ Implement_right_facing_work_lights_Command : 61|2@0+ (4.0,0.0) [0.0|3.0] "bit" Vector__XXX
 SG_ Implement_left_facing_work_lights_Command : 59|2@0+ (4.0,0.0) [0.0|3.0] "bit" Vector__XXX
 SG_ Implement_rear_work_lights_Command : 57|2@0+ (4.0,0.0) [0.0|3.0] "bit" Vector__XXX

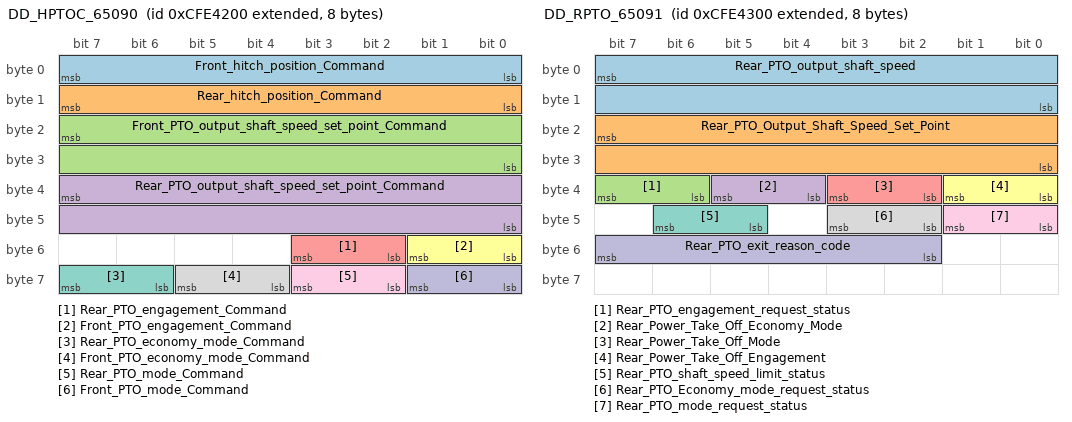
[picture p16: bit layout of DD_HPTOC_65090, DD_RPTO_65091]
BO_ 2365473280 DD_HPTOC_65090: 8 DD_SOURCE
 SG_ Front_hitch_position_Command : 7|8@0+ (0.4,0.0) [0.0|100.0] "%" Vector__XXX
 SG_ Rear_hitch_position_Command : 15|8@0+ (0.4,0.0) [0.0|100.0] "%" Vector__XXX
 SG_ Front_PTO_output_shaft_speed_set_point_Command : 23|16@0+ (0.125,0.0) [0.0|8.0] "1/min" Vector__XXX
 SG_ Rear_PTO_output_shaft_speed_set_point_Command : 39|16@0+ (0.125,0.0) [0.0|8.0] "1/min" Vector__XXX
 SG_ Rear_PTO_engagement_Command : 51|2@0+ (4.0,0.0) [0.0|3.0] "bit" Vector__XXX
 SG_ Front_PTO_engagement_Command : 49|2@0+ (4.0,0.0) [0.0|3.0] "bit" Vector__XXX
 SG_ Rear_PTO_economy_mode_Command : 63|2@0+ (4.0,0.0) [0.0|3.0] "bit" Vector__XXX
 SG_ Front_PTO_economy_mode_Command : 61|2@0+ (4.0,0.0) [0.0|3.0] "bit" Vector__XXX
 SG_ Rear_PTO_mode_Command : 59|2@0+ (4.0,0.0) [0.0|3.0] "bit" Vector__XXX
 SG_ Front_PTO_mode_Command : 57|2@0+ (4.0,0.0) [0.0|3.0] "bit" Vector__XXX

BO_ 2365473536 DD_RPTO_65091: 8 DD_SOURCE
 SG_ Rear_PTO_output_shaft_speed : 7|16@0+ (0.125,0.0) [0.0|8.0] "1/min" Vector__XXX
 SG_ Rear_PTO_Output_Shaft_Speed_Set_Point : 23|16@0+ (0.125,0.0) [0.0|8.0] "1/min" Vector__XXX
 SG_ Rear_PTO_engagement_request_status : 39|2@0+ (4.0,0.0) [0.0|3.0] "bit" Vector__XXX
 SG_ Rear_Power_Take_Off_Economy_Mode : 37|2@0+ (4.0,0.0) [0.0|3.0] "bit" Vector__XXX
 SG_ Rear_Power_Take_Off_Mode : 35|2@0+ (4.0,0.0) [0.0|3.0] "bit" Vector__XXX
 SG_ Rear_Power_Take_Off_Engagement : 33|2@0+ (4.0,0.0) [0.0|3.0] "bit" Vector__XXX
 SG_ Rear_PTO_shaft_speed_limit_status : 46|2@0+ (8.0,0.0) [0.0|7.0] "bit" Vector__XXX
 SG_ Rear_PTO_Economy_mode_request_status : 43|2@0+ (4.0,0.0) [0.0|3.0] "bit" Vector__XXX
 SG_ Rear_PTO_mode_request_status : 41|2@0+ (4.0,0.0) [0.0|3.0] "bit" Vector__XXX
 SG_ Rear_PTO_exit_reason_code : 55|6@0+ (64.0,0.0) [0.0|63.0] "bit" Vector__XXX

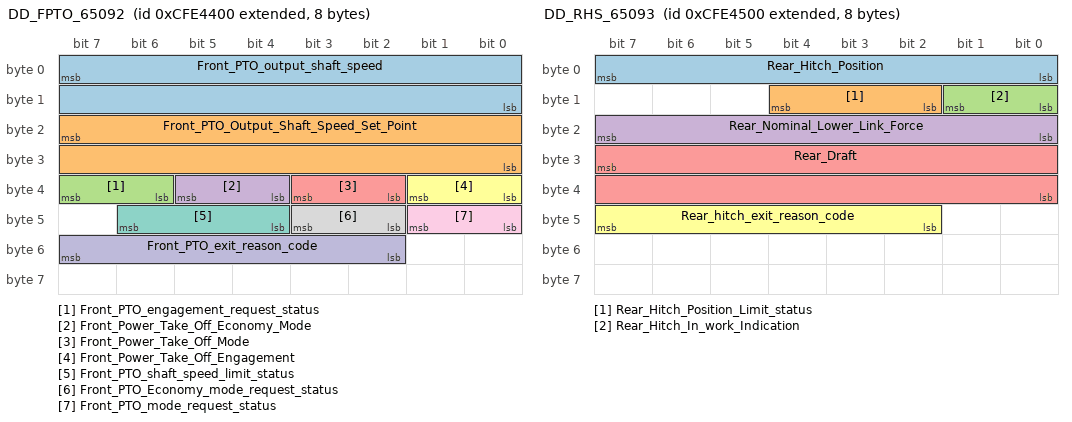
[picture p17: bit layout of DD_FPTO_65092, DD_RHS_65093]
BO_ 2365473792 DD_FPTO_65092: 8 DD_SOURCE
 SG_ Front_PTO_output_shaft_speed : 7|16@0+ (0.125,0.0) [0.0|8.0] "1/min" Vector__XXX
 SG_ Front_PTO_Output_Shaft_Speed_Set_Point : 23|16@0+ (0.125,0.0) [0.0|8.0] "1/min" Vector__XXX
 SG_ Front_PTO_engagement_request_status : 39|2@0+ (4.0,0.0) [0.0|3.0] "bit" Vector__XXX
 SG_ Front_Power_Take_Off_Economy_Mode : 37|2@0+ (4.0,0.0) [0.0|3.0] "bit" Vector__XXX
 SG_ Front_Power_Take_Off_Mode : 35|2@0+ (4.0,0.0) [0.0|3.0] "bit" Vector__XXX
 SG_ Front_Power_Take_Off_Engagement : 33|2@0+ (4.0,0.0) [0.0|3.0] "bit" Vector__XXX
 SG_ Front_PTO_shaft_speed_limit_status : 46|3@0+ (8.0,0.0) [0.0|7.0] "bit" Vector__XXX
 SG_ Front_PTO_Economy_mode_request_status : 43|2@0+ (4.0,0.0) [0.0|3.0] "bit" Vector__XXX
 SG_ Front_PTO_mode_request_status : 41|2@0+ (4.0,0.0) [0.0|3.0] "bit" Vector__XXX
 SG_ Front_PTO_exit_reason_code : 55|6@0+ (64.0,0.0) [0.0|63.0] "bit" Vector__XXX

BO_ 2365474048 DD_RHS_65093: 8 DD_SOURCE
 SG_ Rear_Hitch_Position : 7|8@0+ (0.4,0.0) [0.0|100.0] "%" Vector__XXX
 SG_ Rear_Hitch_Position_Limit_status : 12|3@0+ (8.0,0.0) [0.0|7.0] "bit" Vector__XXX
 SG_ Rear_Hitch_In_work_Indication : 9|2@0+ (4.0,0.0) [0.0|3.0] "bit" Vector__XXX
 SG_ Rear_Nominal_Lower_Link_Force : 23|8@0- (0.8,-100.0) [-100.0|100.0] "%" Vector__XXX
 SG_ Rear_Draft : 31|16@0- (10.0,-320000.0) [-320000.0|322550.0] "N" Vector__XXX
 SG_ Rear_hitch_exit_reason_code : 47|6@0+ (64.0,0.0) [0.0|63.0] "bit" Vector__XXX

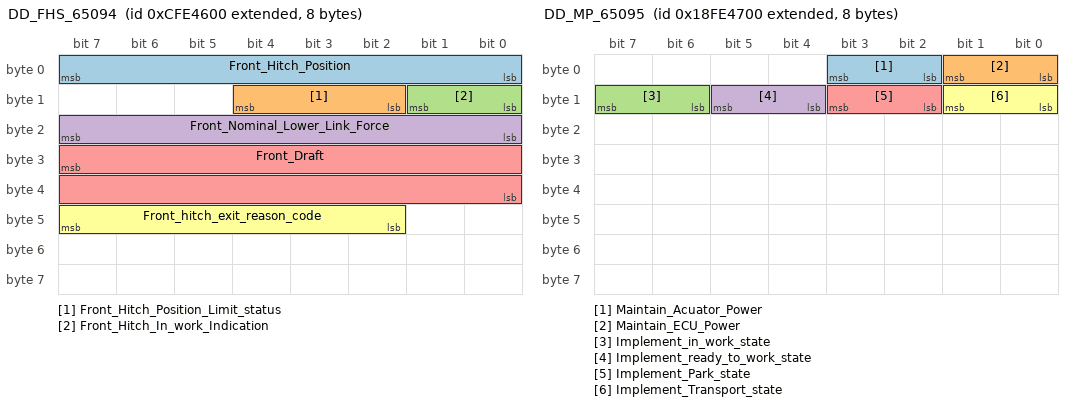
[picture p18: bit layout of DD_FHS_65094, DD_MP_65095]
BO_ 2365474304 DD_FHS_65094: 8 DD_SOURCE
 SG_ Front_Hitch_Position : 7|8@0+ (0.4,0.0) [0.0|100.0] "%" Vector__XXX
 SG_ Front_Hitch_Position_Limit_status : 12|3@0+ (8.0,0.0) [0.0|7.0] "bit" Vector__XXX
 SG_ Front_Hitch_In_work_Indication : 9|2@0+ (4.0,0.0) [0.0|3.0] "bit" Vector__XXX
 SG_ Front_Nominal_Lower_Link_Force : 23|8@0- (0.8,-100.0) [-100.0|100.0] "%" Vector__XXX
 SG_ Front_Draft : 31|16@0- (10.0,-320000.0) [-320000.0|322550.0] "N" Vector__XXX
 SG_ Front_hitch_exit_reason_code : 47|6@0+ (64.0,0.0) [0.0|63.0] "bit" Vector__XXX

BO_ 2566801152 DD_MP_65095: 8 DD_SOURCE
 SG_ Maintain_Acuator_Power : 3|2@0+ (4.0,0.0) [0.0|3.0] "bit" Vector__XXX
 SG_ Maintain_ECU_Power : 1|2@0+ (4.0,0.0) [0.0|3.0] "bit" Vector__XXX
 SG_ Implement_in_work_state : 15|2@0+ (4.0,0.0) [0.0|3.0] "bit" Vector__XXX
 SG_ Implement_ready_to_work_state : 13|2@0+ (4.0,0.0) [0.0|3.0] "bit" Vector__XXX
 SG_ Implement_Park_state : 11|2@0+ (4.0,0.0) [0.0|3.0] "bit" Vector__XXX
 SG_ Implement_Transport_state : 9|2@0+ (4.0,0.0) [0.0|3.0] "bit" Vector__XXX

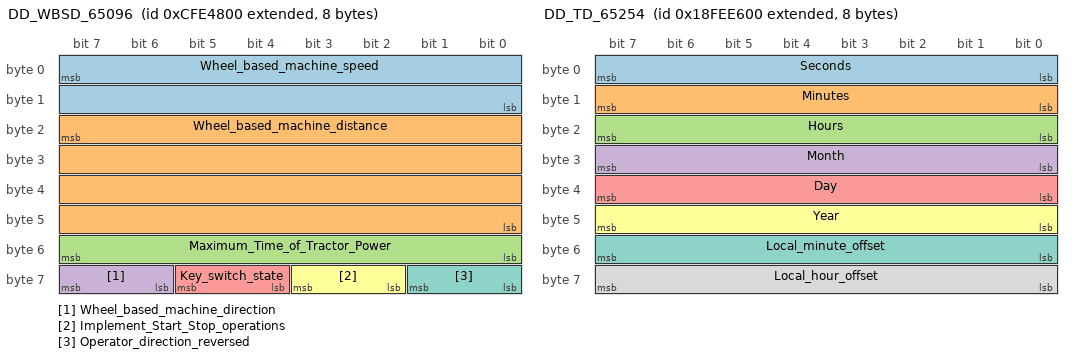
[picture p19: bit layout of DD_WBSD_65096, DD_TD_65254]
BO_ 2365474816 DD_WBSD_65096: 8 DD_SOURCE
 SG_ Wheel_based_machine_speed : 7|16@0+ (0.001,0.0) [0.0|64.255] "m/s" Vector__XXX
 SG_ Wheel_based_machine_distance : 23|32@0+ (0.001,0.0) [0.0|4211081.215] "m" Vector__XXX
 SG_ Maximum_Time_of_Tractor_Power : 55|8@0+ (1.0,0.0) [0.0|250.0] "min" Vector__XXX
 SG_ Wheel_based_machine_direction : 63|2@0+ (4.0,0.0) [0.0|3.0] "bit" Vector__XXX
 SG_ Key_switch_state : 61|2@0+ (4.0,0.0) [0.0|3.0] "bit" Vector__XXX
 SG_ Implement_Start_Stop_operations : 59|2@0+ (4.0,0.0) [0.0|3.0] "bit" Vector__XXX
 SG_ Operator_direction_reversed : 57|2@0+ (4.0,0.0) [0.0|3.0] "bit" Vector__XXX

BO_ 2365475072 DD_GBSD_65097: 8 DD_SOURCE
 SG_ Ground_based_machine_speed : 7|16@0+ (0.001,0.0) [0.0|64.255] "m/s" Vector__XXX
 SG_ Ground_based_machine_distance : 23|32@0+ (0.001,0.0) [0.0|4211081.215] "m" Vector__XXX
 SG_ Ground_based_machine_direction : 63|2@0+ (4.0,0.0) [0.0|3.0] "bit" Vector__XXX

BO_ 2566834688 DD_DM1_65226: 8 DD_SOURCE
 SG_ Suspect_Parameter_Number : 23|19@0+ (1.0,0.0) [0.0|524.0] "SPN" Vector__XXX
 SG_ Occurrence_Count : 47|7@0+ (1.0,0.0) [0.0|127.0] "OC" Vector__XXX
 SG_ SPN_Conversion_Method : 40|1@0+ (2.0,0.0) [0.0|1.0] "Bit Field" Vector__XXX

BO_ 2566834944 DD_DM2_65227: 8 DD_SOURCE
 SG_ Suspect_Parameter_Number : 23|19@0+ (1.0,0.0) [0.0|524.0] "SPN" Vector__XXX
 SG_ Occurrence_Count : 47|7@0+ (1.0,0.0) [0.0|127.0] "OC" Vector__XXX
 SG_ SPN_Conversion_Method : 40|1@0+ (2.0,0.0) [0.0|1.0] "Bit Field" Vector__XXX

BO_ 2566838784 DD_SOFT_65242: 201 DD_SOURCE
 SG_ Number_of_Software_Identification_Fields : 7|8@0+ (1.0,0.0) [0.0|125.0] "step" Vector__XXX
 SG_ Software_Identification : 15|1600@0+ (1.0,0.0) [0.0|255.0] "ASCII" Vector__XXX

BO_ 2566841856 DD_TD_65254: 8 DD_SOURCE
 SG_ Seconds : 7|8@0+ (0.25,0.0) [0.0|63.75] "s" Vector__XXX
 SG_ Minutes : 15|8@0+ (1.0,0.0) [0.0|255.0] "min" Vector__XXX
 SG_ Hours : 23|8@0+ (1.0,0.0) [0.0|255.0] "h" Vector__XXX
 SG_ Month : 31|8@0+ (1.0,0.0) [0.0|255.0] "month" Vector__XXX
 SG_ Day : 39|8@0+ (0.25,0.0) [0.0|63.75] "days" Vector__XXX
 SG_ Year : 47|8@0+ (1.0,1985.0) [0.0|2240.0] "year" Vector__XXX
 SG_ Local_minute_offset : 55|8@0+ (1.0,125.0) [0.0|380.0] "min" Vector__XXX
 SG_ Local_hour_offset : 63|8@0+ (1.0,125.0) [0.0|380.0] "h" Vector__XXX

BA_DEF_ BO_  "J1939PGN" INT 0 262143;
BA_DEF_ BO_  "GenMsgCycleTime" INT 0 60000;
BA_DEF_ BO_  "GenMsgPriority" INT 0 7;
BA_DEF_DEF_  "J1939PGN" 0;
BA_DEF_DEF_  "GenMsgCycleTime" 0;
BA_DEF_DEF_  "GenMsgPriority" 6;
BA_ "J1939PGN" BO_ 2550595584 1792;
BA_ "GenMsgCycleTime" BO_ 2550595584 100;
BA_ "J1939PGN" BO_ 2619539456 8960;
BA_ "GenMsgPriority" BO_ 2619539456 7;
BA_ "J1939PGN" BO_ 2619604992 9216;
BA_ "GenMsgPriority" BO_ 2619604992 7;
BA_ "J1939PGN" BO_ 2554068992 15360;
BA_ "J1939PGN" BO_ 2554134528 15616;
BA_ "J1939PGN" BO_ 2360082432 44032;
BA_ "GenMsgCycleTime" BO_ 2360082432 100;
BA_ "GenMsgPriority" BO_ 2360082432 3;
BA_ "J1939PGN" BO_ 2360147968 44288;
BA_ "GenMsgCycleTime" BO_ 2360147968 100;
BA_ "GenMsgPriority" BO_ 2360147968 3;
BA_ "J1939PGN" BO_ 2361655296 50176;
BA_ "GenMsgCycleTime" BO_ 2361655296 100;
BA_ "GenMsgPriority" BO_ 2361655296 3;
BA_ "J1939PGN" BO_ 2361720832 50432;
BA_ "GenMsgCycleTime" BO_ 2361720832 100;
BA_ "GenMsgPriority" BO_ 2361720832 3;
BA_ "J1939PGN" BO_ 2361786368 50688;
BA_ "GenMsgCycleTime" BO_ 2361786368 100;
BA_ "GenMsgPriority" BO_ 2361786368 3;
BA_ "J1939PGN" BO_ 2362114048 51968;
BA_ "GenMsgPriority" BO_ 2362114048 3;
BA_ "J1939PGN" BO_ 2563506176 52224;
BA_ "J1939PGN" BO_ 2362441728 53248;
BA_ "GenMsgCycleTime" BO_ 2362441728 5;
BA_ "GenMsgPriority" BO_ 2362441728 3;
BA_ "J1939PGN" BO_ 2364547584 61474;
BA_ "GenMsgCycleTime" BO_ 2364547584 100;
BA_ "GenMsgPriority" BO_ 2364547584 3;
BA_ "J1939PGN" BO_ 2364597248 61668;
BA_ "GenMsgCycleTime" BO_ 2364597248 100;
BA_ "GenMsgPriority" BO_ 2364597248 3;
BA_ "J1939PGN" BO_ 2364604160 61695;
BA_ "GenMsgCycleTime" BO_ 2364604160 100;
BA_ "GenMsgPriority" BO_ 2364604160 3;
BA_ "J1939PGN" BO_ 2364604416 61696;
BA_ "GenMsgCycleTime" BO_ 2364604416 100;
BA_ "GenMsgPriority" BO_ 2364604416 3;
BA_ "J1939PGN" BO_ 2364604672 61697;
BA_ "GenMsgCycleTime" BO_ 2364604672 100;
BA_ "GenMsgPriority" BO_ 2364604672 3;
BA_ "J1939PGN" BO_ 2364604928 61698;
BA_ "GenMsgCycleTime" BO_ 2364604928 100;
BA_ "GenMsgPriority" BO_ 2364604928 3;
BA_ "J1939PGN" BO_ 2364620288 61758;
BA_ "GenMsgCycleTime" BO_ 2364620288 100;
BA_ "GenMsgPriority" BO_ 2364620288 3;
BA_ "J1939PGN" BO_ 2364620544 61759;
BA_ "GenMsgCycleTime" BO_ 2364620544 100;
BA_ "GenMsgPriority" BO_ 2364620544 3;
BA_ "J1939PGN" BO_ 2365293056 64386;
BA_ "GenMsgCycleTime" BO_ 2365293056 100;
BA_ "GenMsgPriority" BO_ 2365293056 3;
BA_ "J1939PGN" BO_ 2365293312 64387;
BA_ "GenMsgCycleTime" BO_ 2365293312 100;
BA_ "GenMsgPriority" BO_ 2365293312 3;
BA_ "J1939PGN" BO_ 2365293568 64388;
BA_ "GenMsgCycleTime" BO_ 2365293568 1;
BA_ "GenMsgPriority" BO_ 2365293568 3;
BA_ "J1939PGN" BO_ 2566655488 64526;
BA_ "GenMsgCycleTime" BO_ 2566655488 100;
BA_ "J1939PGN" BO_ 2566655744 64527;
BA_ "GenMsgCycleTime" BO_ 2566655744 100;
BA_ "J1939PGN" BO_ 2566704384 64717;
BA_ "GenMsgCycleTime" BO_ 2566704384 500;
BA_ "J1939PGN" BO_ 2365378048 64718;
BA_ "GenMsgCycleTime" BO_ 2365378048 500;
BA_ "GenMsgPriority" BO_ 2365378048 3;
BA_ "J1939PGN" BO_ 2365391360 64770;
BA_ "GenMsgCycleTime" BO_ 2365391360 1;
BA_ "GenMsgPriority" BO_ 2365391360 3;
BA_ "J1939PGN" BO_ 2365391616 64771;
BA_ "GenMsgCycleTime" BO_ 2365391616 1;
BA_ "GenMsgPriority" BO_ 2365391616 3;
BA_ "J1939PGN" BO_ 2566730240 64818;
BA_ "J1939PGN" BO_ 2566734336 64834;
BA_ "J1939PGN" BO_ 2365408000 64835;
BA_ "GenMsgCycleTime" BO_ 2365408000 100;
BA_ "GenMsgPriority" BO_ 2365408000 3;
BA_ "J1939PGN" BO_ 2365458432 65032;
BA_ "GenMsgPriority" BO_ 2365458432 3;
BA_ "J1939PGN" BO_ 2365458688 65033;
BA_ "GenMsgPriority" BO_ 2365458688 3;
BA_ "J1939PGN" BO_ 2365459200 65035;
BA_ "GenMsgCycleTime" BO_ 2365459200 100;
BA_ "GenMsgPriority" BO_ 2365459200 3;
BA_ "J1939PGN" BO_ 2633894912 65036;
BA_ "GenMsgPriority" BO_ 2633894912 7;
BA_ "J1939PGN" BO_ 2633895168 65037;
BA_ "GenMsgPriority" BO_ 2633895168 7;
BA_ "J1939PGN" BO_ 2566786560 65038;
BA_ "J1939PGN" BO_ 2566786816 65039;
BA_ "J1939PGN" BO_ 2365460480 65040;
BA_ "GenMsgCycleTime" BO_ 2365460480 100;
BA_ "GenMsgPriority" BO_ 2365460480 3;
BA_ "J1939PGN" BO_ 2365460736 65041;
BA_ "GenMsgCycleTime" BO_ 2365460736 100;
BA_ "GenMsgPriority" BO_ 2365460736 3;
BA_ "J1939PGN" BO_ 2365460992 65042;
BA_ "GenMsgCycleTime" BO_ 2365460992 100;
BA_ "GenMsgPriority" BO_ 2365460992 3;
BA_ "J1939PGN" BO_ 2365461248 65043;
BA_ "GenMsgCycleTime" BO_ 2365461248 100;
BA_ "GenMsgPriority" BO_ 2365461248 3;
BA_ "J1939PGN" BO_ 2365461504 65044;
BA_ "GenMsgCycleTime" BO_ 2365461504 100;
BA_ "GenMsgPriority" BO_ 2365461504 3;
BA_ "J1939PGN" BO_ 2365461760 65045;
BA_ "GenMsgCycleTime" BO_ 2365461760 100;
BA_ "GenMsgPriority" BO_ 2365461760 3;
BA_ "J1939PGN" BO_ 2365462016 65046;
BA_ "GenMsgCycleTime" BO_ 2365462016 100;
BA_ "GenMsgPriority" BO_ 2365462016 3;
BA_ "J1939PGN" BO_ 2365462272 65047;
BA_ "GenMsgCycleTime" BO_ 2365462272 100;
BA_ "GenMsgPriority" BO_ 2365462272 3;
BA_ "J1939PGN" BO_ 2365462528 65048;
BA_ "GenMsgCycleTime" BO_ 2365462528 100;
BA_ "GenMsgPriority" BO_ 2365462528 3;
BA_ "J1939PGN" BO_ 2365462784 65049;
BA_ "GenMsgCycleTime" BO_ 2365462784 100;
BA_ "GenMsgPriority" BO_ 2365462784 3;
BA_ "J1939PGN" BO_ 2365463040 65050;
BA_ "GenMsgCycleTime" BO_ 2365463040 100;
BA_ "GenMsgPriority" BO_ 2365463040 3;
BA_ "J1939PGN" BO_ 2365463296 65051;
BA_ "GenMsgCycleTime" BO_ 2365463296 100;
BA_ "GenMsgPriority" BO_ 2365463296 3;
BA_ "J1939PGN" BO_ 2365463552 65052;
BA_ "GenMsgCycleTime" BO_ 2365463552 100;
BA_ "GenMsgPriority" BO_ 2365463552 3;
BA_ "J1939PGN" BO_ 2365463808 65053;
BA_ "GenMsgCycleTime" BO_ 2365463808 100;
BA_ "GenMsgPriority" BO_ 2365463808 3;
BA_ "J1939PGN" BO_ 2365464064 65054;
BA_ "GenMsgCycleTime" BO_ 2365464064 100;
BA_ "GenMsgPriority" BO_ 2365464064 3;
BA_ "J1939PGN" BO_ 2365464320 65055;
BA_ "GenMsgCycleTime" BO_ 2365464320 100;
BA_ "GenMsgPriority" BO_ 2365464320 3;
BA_ "J1939PGN" BO_ 2365464576 65056;
BA_ "GenMsgCycleTime" BO_ 2365464576 100;
BA_ "GenMsgPriority" BO_ 2365464576 3;
BA_ "J1939PGN" BO_ 2365464832 65057;
BA_ "GenMsgCycleTime" BO_ 2365464832 100;
BA_ "GenMsgPriority" BO_ 2365464832 3;
BA_ "J1939PGN" BO_ 2365465088 65058;
BA_ "GenMsgCycleTime" BO_ 2365465088 100;
BA_ "GenMsgPriority" BO_ 2365465088 3;
BA_ "J1939PGN" BO_ 2365465344 65059;
BA_ "GenMsgCycleTime" BO_ 2365465344 100;
BA_ "GenMsgPriority" BO_ 2365465344 3;
BA_ "J1939PGN" BO_ 2365465600 65060;
BA_ "GenMsgCycleTime" BO_ 2365465600 100;
BA_ "GenMsgPriority" BO_ 2365465600 3;
BA_ "J1939PGN" BO_ 2365465856 65061;
BA_ "GenMsgCycleTime" BO_ 2365465856 100;
BA_ "GenMsgPriority" BO_ 2365465856 3;
BA_ "J1939PGN" BO_ 2365466112 65062;
BA_ "GenMsgCycleTime" BO_ 2365466112 100;
BA_ "GenMsgPriority" BO_ 2365466112 3;
BA_ "J1939PGN" BO_ 2365466368 65063;
BA_ "GenMsgCycleTime" BO_ 2365466368 100;
BA_ "GenMsgPriority" BO_ 2365466368 3;
BA_ "J1939PGN" BO_ 2365466624 65064;
BA_ "GenMsgCycleTime" BO_ 2365466624 100;
BA_ "GenMsgPriority" BO_ 2365466624 3;
BA_ "J1939PGN" BO_ 2365466880 65065;
BA_ "GenMsgCycleTime" BO_ 2365466880 100;
BA_ "GenMsgPriority" BO_ 2365466880 3;
BA_ "J1939PGN" BO_ 2365467136 65066;
BA_ "GenMsgCycleTime" BO_ 2365467136 100;
BA_ "GenMsgPriority" BO_ 2365467136 3;
BA_ "J1939PGN" BO_ 2365467392 65067;
BA_ "GenMsgCycleTime" BO_ 2365467392 100;
BA_ "GenMsgPriority" BO_ 2365467392 3;
BA_ "J1939PGN" BO_ 2365467648 65068;
BA_ "GenMsgCycleTime" BO_ 2365467648 100;
BA_ "GenMsgPriority" BO_ 2365467648 3;
BA_ "J1939PGN" BO_ 2365467904 65069;
BA_ "GenMsgCycleTime" BO_ 2365467904 100;
BA_ "GenMsgPriority" BO_ 2365467904 3;
BA_ "J1939PGN" BO_ 2365468160 65070;
BA_ "GenMsgCycleTime" BO_ 2365468160 100;
BA_ "GenMsgPriority" BO_ 2365468160 3;
BA_ "J1939PGN" BO_ 2365468416 65071;
BA_ "GenMsgCycleTime" BO_ 2365468416 100;
BA_ "GenMsgPriority" BO_ 2365468416 3;
BA_ "J1939PGN" BO_ 2365468672 65072;
BA_ "GenMsgCycleTime" BO_ 2365468672 100;
BA_ "GenMsgPriority" BO_ 2365468672 3;
BA_ "J1939PGN" BO_ 2365468928 65073;
BA_ "GenMsgCycleTime" BO_ 2365468928 100;
BA_ "GenMsgPriority" BO_ 2365468928 3;
BA_ "J1939PGN" BO_ 2365469184 65074;
BA_ "GenMsgCycleTime" BO_ 2365469184 100;
BA_ "GenMsgPriority" BO_ 2365469184 3;
BA_ "J1939PGN" BO_ 2365469440 65075;
BA_ "GenMsgCycleTime" BO_ 2365469440 100;
BA_ "GenMsgPriority" BO_ 2365469440 3;
BA_ "J1939PGN" BO_ 2365469696 65076;
BA_ "GenMsgCycleTime" BO_ 2365469696 100;
BA_ "GenMsgPriority" BO_ 2365469696 3;
BA_ "J1939PGN" BO_ 2365469952 65077;
BA_ "GenMsgCycleTime" BO_ 2365469952 100;
BA_ "GenMsgPriority" BO_ 2365469952 3;
BA_ "J1939PGN" BO_ 2365470208 65078;
BA_ "GenMsgCycleTime" BO_ 2365470208 100;
BA_ "GenMsgPriority" BO_ 2365470208 3;
BA_ "J1939PGN" BO_ 2365470464 65079;
BA_ "GenMsgCycleTime" BO_ 2365470464 100;
BA_ "GenMsgPriority" BO_ 2365470464 3;
BA_ "J1939PGN" BO_ 2365470720 65080;
BA_ "GenMsgCycleTime" BO_ 2365470720 100;
BA_ "GenMsgPriority" BO_ 2365470720 3;
BA_ "J1939PGN" BO_ 2365470976 65081;
BA_ "GenMsgCycleTime" BO_ 2365470976 100;
BA_ "GenMsgPriority" BO_ 2365470976 3;
BA_ "J1939PGN" BO_ 2365471232 65082;
BA_ "GenMsgCycleTime" BO_ 2365471232 100;
BA_ "GenMsgPriority" BO_ 2365471232 3;
BA_ "J1939PGN" BO_ 2365471488 65083;
BA_ "GenMsgCycleTime" BO_ 2365471488 100;
BA_ "GenMsgPriority" BO_ 2365471488 3;
BA_ "J1939PGN" BO_ 2365471744 65084;
BA_ "GenMsgCycleTime" BO_ 2365471744 100;
BA_ "GenMsgPriority" BO_ 2365471744 3;
BA_ "J1939PGN" BO_ 2365472000 65085;
BA_ "GenMsgCycleTime" BO_ 2365472000 100;
BA_ "GenMsgPriority" BO_ 2365472000 3;
BA_ "J1939PGN" BO_ 2365472256 65086;
BA_ "GenMsgCycleTime" BO_ 2365472256 100;
BA_ "GenMsgPriority" BO_ 2365472256 3;
BA_ "J1939PGN" BO_ 2365472512 65087;
BA_ "GenMsgCycleTime" BO_ 2365472512 100;
BA_ "GenMsgPriority" BO_ 2365472512 3;
BA_ "J1939PGN" BO_ 2566799360 65088;
BA_ "J1939PGN" BO_ 2365473024 65089;
BA_ "GenMsgCycleTime" BO_ 2365473024 1;
BA_ "GenMsgPriority" BO_ 2365473024 3;
BA_ "J1939PGN" BO_ 2365473280 65090;
BA_ "GenMsgCycleTime" BO_ 2365473280 100;
BA_ "GenMsgPriority" BO_ 2365473280 3;
BA_ "J1939PGN" BO_ 2365473536 65091;
BA_ "GenMsgCycleTime" BO_ 2365473536 100;
BA_ "GenMsgPriority" BO_ 2365473536 3;
BA_ "J1939PGN" BO_ 2365473792 65092;
BA_ "GenMsgCycleTime" BO_ 2365473792 100;
BA_ "GenMsgPriority" BO_ 2365473792 3;
BA_ "J1939PGN" BO_ 2365474048 65093;
BA_ "GenMsgCycleTime" BO_ 2365474048 100;
BA_ "GenMsgPriority" BO_ 2365474048 3;
BA_ "J1939PGN" BO_ 2365474304 65094;
BA_ "GenMsgCycleTime" BO_ 2365474304 100;
BA_ "GenMsgPriority" BO_ 2365474304 3;
BA_ "J1939PGN" BO_ 2566801152 65095;
BA_ "J1939PGN" BO_ 2365474816 65096;
BA_ "GenMsgCycleTime" BO_ 2365474816 100;
BA_ "GenMsgPriority" BO_ 2365474816 3;
BA_ "J1939PGN" BO_ 2365475072 65097;
BA_ "GenMsgCycleTime" BO_ 2365475072 100;
BA_ "GenMsgPriority" BO_ 2365475072 3;
BA_ "J1939PGN" BO_ 2566834688 65226;
BA_ "GenMsgCycleTime" BO_ 2566834688 1000;
BA_ "J1939PGN" BO_ 2566834944 65227;
BA_ "J1939PGN" BO_ 2566838784 65242;
BA_ "J1939PGN" BO_ 2566841856 65254;

CM_ BO_ 2550595584 "ISOBUS DD: General Purpose Valve Pressure (PGN 1792, ISO 11783-7)";
CM_ SG_ 2550595584 General_purpose_valve_load_sense_pressure "SPN 4086 (Measured)";
CM_ SG_ 2550595584 General_purpose_valve_pilot_pressure "SPN 4087 (Measured)";
CM_ SG_ 2550595584 General_purpose_valve_assembly_load_sense_pressure "SPN 4088 (Measured)";
CM_ SG_ 2550595584 General_purpose_valve_assembly_supply_pressure "SPN 4089 (Measured)";
CM_ SG_ 2550595584 Valve_Pilot_Pressure_Switch "SPN 22130 (Measured)";
CM_ BO_ 2619539456 "ISOBUS DD: Tractor Implement Management (TIM) Server to TIM Client (PGN 8960, ISO 11783-7)";
CM_ SG_ 2619539456 Auxiliary_Valve_1_Flow "SPN 8665 (Measured)";
CM_ SG_ 2619539456 Auxiliary_Valve_1_Automation_Status "SPN 8697 (Status)";
CM_ SG_ 2619539456 Auxiliary_Valve_1_Exit_Reason_Code "SPN 8729 (Status)";
CM_ SG_ 2619539456 TIM_server_heartbeat_counter "SPN 13212 (Current Value)";
CM_ SG_ 2619539456 Auxiliary_valve_1_flow_type "SPN 13251 (Measured)";
CM_ SG_ 2619539456 TIM_v1_Server_to_Client_function_ID_Message_Code "SPN 23573 (Count (no error, N/A))";
CM_ SG_ 2619539456 Number_of_TIM_server_functions_assigned_to_CF_to_follow "SPN 23888 (Number of bytes)";
CM_ BO_ 2619604992 "ISOBUS DD: Tractor Implement Management (TIM) Client to TIM Server (PGN 9216, ISO 11783-7)";
CM_ SG_ 2619604992 Auxiliary_Valve_1_Flow_Request "SPN 8779 (Measured)";
CM_ SG_ 2619604992 TIM_client_heartbeat_counter "SPN 13285 (Current Value)";
CM_ SG_ 2619604992 TIM_client_state "SPN 13286 (Enumeration)";
CM_ SG_ 2619604992 TIM_Client_Minimum_TIM_version_number "SPN 13288 (Count)";
CM_ SG_ 2619604992 TIM_v1_Client_to_Server_function_ID_Message_Code "SPN 23575 (Count (no error, N/A))";
CM_ BO_ 2554068992 "ISOBUS DD: Tractor Implement Management (TIM) Server to TIM Client - Control Status (PGN 15360, ISO 11783-7)";
CM_ SG_ 2554068992 Implemented_MSA_Server_version "SPN 24695 (Count)";
CM_ SG_ 2554068992 Minimum_MSA_Server_version "SPN 24696 (Count)";
CM_ SG_ 2554068992 MSA_connection_version_error_code "SPN 24699 (Count)";
CM_ SG_ 2554068992 Auxiliary_Valve_1_Automation_Status "SPN 8697 (Status)";
CM_ SG_ 2554068992 TIM_v2_Server_to_Client_function_ID_Message_Code "SPN 23577 (Count (no error, N/A))";
CM_ SG_ 2554068992 TIM_v2_Server_to_Client_control_mode "SPN 23578 (Enumeration)";
CM_ SG_ 2554068992 TIM_v2_Server_to_Client_Message_type "SPN 23579 (Enumeration)";
CM_ SG_ 2554068992 Front_Hitch_State "SPN 23868 (Status)";
CM_ BO_ 2554134528 "ISOBUS DD: Tractor Implement Management (TIM) Client to TIM Server - Control Status (PGN 15616, ISO 11783-7)";
CM_ SG_ 2554134528 Implemented_MSA_Client_version "SPN 24697 (Count)";
CM_ SG_ 2554134528 Minimum_MSA_Client_version "SPN 24698 (Count)";
CM_ SG_ 2554134528 TIM_v2_Client_to_Server_function_ID_Message_Code "SPN 23580 (Count (no error, N/A))";
CM_ SG_ 2554134528 TIM_v2_Client_to_Server_control_mode "SPN 23581 (Enumeration)";
CM_ SG_ 2554134528 TIM_v2_Client_to_Server_Message_type "SPN 23582 (Enumeration)";
CM_ SG_ 2554134528 Number_of_control_modes_with_parametrization_request_data_to_follow "SPN 23875 (Count (no error, N/A))";
CM_ BO_ 2360082432 "ISOBUS DD: Agricultural Guidance Machine Info (PGN 44032, ISO 11783-7)";
CM_ SG_ 2360082432 Estimated_curvature "SPN 5238 (Measured)";
CM_ SG_ 2360082432 Mechanical_system_lockout "SPN 5243 (Measured)";
CM_ SG_ 2360082432 Guidance_steering_system_readiness "SPN 5242 (Measured)";
CM_ SG_ 2360082432 Steering_input_position_status "SPN 5241 (Measured)";
CM_ SG_ 2360082432 Request_reset_command_status "SPN 5240 (Measured)";
CM_ SG_ 2360082432 Guidance_Limit_Status "SPN 5726 (Measured)";
CM_ SG_ 2360082432 Guidance_system_command_exit_reason_code "SPN 5725 (Measured)";
CM_ SG_ 2360082432 Guidance_system_Remote_Engage_Switch_Status "SPN 9726 (Measured)";
CM_ BO_ 2360147968 "ISOBUS DD: Agricultural Guidance System command (PGN 44288, ISO 11783-7)";
CM_ SG_ 2360147968 Curvature_command "SPN 5237 (Command)";
CM_ SG_ 2360147968 Curvature_command_status "SPN 5239 (Command)";
CM_ BO_ 2361655296 "ISOBUS DD: General Purpose Valve command (PGN 50176, ISO 11783-7)";
CM_ SG_ 2361655296 General_purpose_valve_port_flow_Command "SPN 2944 (Command)";
CM_ SG_ 2361655296 General_purpose_valve_state_Command "SPN 2933 (Command)";
CM_ SG_ 2361655296 General_purpose_value_fail_safe_mode_Command "SPN 2935 (Command)";
CM_ SG_ 2361655296 General_purpose_valve_port_flow_Extended_Resolution_Command "SPN 9727 (Command)";
CM_ BO_ 2361720832 "ISOBUS DD: General Purpose Valve measured flow (PGN 50432, ISO 11783-7)";
CM_ SG_ 2361720832 General_purpose_valve_extend_port_measured_flow "SPN 2937 (Measured)";
CM_ SG_ 2361720832 General_purpose_valve_retract_port_measured_flow "SPN 2938 (Measured)";
CM_ SG_ 2361720832 General_purpose_valve_extend_port_pressure "SPN 2941 (Measured)";
CM_ SG_ 2361720832 General_purpose_valve_retract_port_pressure "SPN 2942 (Measured)";
CM_ SG_ 2361720832 General_purpose_valve_return_port_pressure "SPN 2943 (Measured)";
CM_ SG_ 2361720832 General_purpose_valve_measured_limit_status "SPN 5192 (Measured)";
CM_ BO_ 2361786368 "ISOBUS DD: General Purpose Valve estimated flow (PGN 50688, ISO 11783-7)";
CM_ SG_ 2361786368 General_purpose_valve_extend_port_estimated_flow "SPN 2939 (Measured)";
CM_ SG_ 2361786368 General_purpose_valve_retract_port_estimated_flow "SPN 2940 (Measured)";
CM_ SG_ 2361786368 General_purpose_valve_state "SPN 2932 (Measured)";
CM_ SG_ 2361786368 General_purpose_valve_fail_safe_mode "SPN 2934 (Measured)";
CM_ SG_ 2361786368 General_purpose_valve_estimated_limit_status "SPN 5193 (Measured)";
CM_ SG_ 2361786368 General_purpose_valve_exit_reason_code "SPN 9730 (Estimated)";
CM_ SG_ 2361786368 General_purpose_valve_extend_port_high_resolution_estimated_flow "SPN 9728 (Estimated)";
CM_ SG_ 2361786368 General_purpose_valve_retract_port_high_resolution_estimated_flow "SPN 9729 (Estimated)";
CM_ BO_ 2362114048 "ISOBUS DD: Process Data Message (PGN 51968, ISO 11783-7)";
CM_ SG_ 2362114048 Process_data_command "SPN 5199 ()";
CM_ SG_ 2362114048 Process_data_element_number "SPN 5200 ()";
CM_ SG_ 2362114048 Process_data_data_dictionary_identifier "SPN 5201 ()";
CM_ SG_ 2362114048 Process_data_variable_value "SPN 5202 ()";
CM_ BO_ 2563506176 "ISOBUS DD: Request for Repetition Rate (PGN 52224, ISO 11783-7)";
CM_ SG_ 2563506176 PGN_of_the_request_1 "SPN 21848 (Command)";
CM_ SG_ 2563506176 Repetition_rate_Command "SPN 2418 (Command)";
CM_ BO_ 2362441728 "ISOBUS DD: Background lighting level command (PGN 53248, ISO 11783-7)";
CM_ SG_ 2362441728 Background_illumination_level_Command "SPN 1487 (Command)";
CM_ BO_ 2364547584 "ISOBUS DD: Machine Selected Speed (PGN 61474, ISO 11783-7)";
CM_ SG_ 2364547584 Machine_selected_direction "SPN 4309 (Measured)";
CM_ SG_ 2364547584 Machine_selected_speed_source "SPN 4308 (Measured)";
CM_ SG_ 2364547584 Machine_selected_speed_limit_status "SPN 4307 (Measured)";
CM_ SG_ 2364547584 Machine_selected_speed_exit_reason_code "SPN 5818 (Measured)";
CM_ SG_ 2364547584 Machine_selected_speed "SPN 4305 (Measured)";
CM_ SG_ 2364547584 Machine_selected_distance "SPN 4306 (Measured)";
CM_ BO_ 2364597248 "ISOBUS DD: Heartbeat Message (PGN 61668, ISO 11783-7)";
CM_ SG_ 2364597248 Heartbeat_sequence_number "SPN 7345 (Current Value)";
CM_ BO_ 2364604160 "ISOBUS DD: Secondary or Front Hitch Roll and Pitch (PGN 61695, ISO 11783-7)";
CM_ SG_ 2364604160 Front_hitch_roll_angle "SPN 7790 (Measured)";
CM_ SG_ 2364604160 Front_hitch_roll_limit_status "SPN 7791 (Measured)";
CM_ SG_ 2364604160 Front_hitch_roll_exit_reason_code "SPN 7792 (Measured)";
CM_ SG_ 2364604160 Front_hitch_pitch_angle "SPN 7793 (Measured)";
CM_ SG_ 2364604160 Front_hitch_pitch_limit_status "SPN 7794 (Measured)";
CM_ SG_ 2364604160 Front_hitch_pitch_exit_reason_code "SPN 7795 (Measured)";
CM_ BO_ 2364604416 "ISOBUS DD: Secondary or Front Hitch Roll and Pitch command (PGN 61696, ISO 11783-7)";
CM_ SG_ 2364604416 Front_hitch_roll_command "SPN 7796 (Command)";
CM_ SG_ 2364604416 Front_hitch_roll_sensitivity_command "SPN 7797 (Command)";
CM_ SG_ 2364604416 Front_hitch_pitch_command "SPN 7798 (Command)";
CM_ SG_ 2364604416 Front_hitch_pitch_sensitivity_command "SPN 7799 (Command)";
CM_ BO_ 2364604672 "ISOBUS DD: Primary or Rear Hitch Roll and Pitch (PGN 61697, ISO 11783-7)";
CM_ SG_ 2364604672 Rear_hitch_roll_angle "SPN 7802 (Measured)";
CM_ SG_ 2364604672 Rear_hitch_roll_limit_status "SPN 7803 (Measured)";
CM_ SG_ 2364604672 Rear_hitch_roll_exit_reason_code "SPN 7804 (Measured)";
CM_ SG_ 2364604672 Rear_hitch_pitch_angle "SPN 7805 (Measured)";
CM_ SG_ 2364604672 Rear_hitch_pitch_limit_status "SPN 7806 (Measured)";
CM_ SG_ 2364604672 Rear_hitch_pitch_exit_reason_code "SPN 7807 (Measured)";
CM_ BO_ 2364604928 "ISOBUS DD: Primary or Rear Hitch Roll and Pitch command (PGN 61698, ISO 11783-7)";
CM_ SG_ 2364604928 Rear_hitch_roll_command "SPN 7808 (Command)";
CM_ SG_ 2364604928 Rear_hitch_roll_sensitivity_command "SPN 7809 (Command)";
CM_ SG_ 2364604928 Rear_hitch_pitch_command "SPN 7810 (Command)";
CM_ SG_ 2364604928 Rear_hitch_pitch_sensitivity_command "SPN 7811 (Command)";
CM_ BO_ 2364620288 "ISOBUS DD: Secondary or Front Hitch Yaw command (PGN 61758, ISO 11783-7)";
CM_ SG_ 2364620288 Front_hitch_yaw_command "SPN 9719 (Command)";
CM_ BO_ 2364620544 "ISOBUS DD: Primary or Rear Hitch Yaw command (PGN 61759, ISO 11783-7)";
CM_ SG_ 2364620544 Rear_hitch_yaw_command "SPN 9725 (Command)";
CM_ BO_ 2365293056 "ISOBUS DD: Primary or Rear Hitch Yaw (PGN 64386, ISO 11783-7)";
CM_ SG_ 2365293056 Rear_hitch_yaw_angle "SPN 9720 (Measured)";
CM_ SG_ 2365293056 Rear_hitch_yaw_angle_reference_frame "SPN 9721 (Measured)";
CM_ SG_ 2365293056 Rear_hitch_yaw_angle_actual_control_mode "SPN 9722 (Measured)";
CM_ SG_ 2365293056 Rear_hitch_yaw_limit_status "SPN 9723 (Measured)";
CM_ SG_ 2365293056 Rear_hitch_yaw_exit_reason_code "SPN 9724 (Measured)";
CM_ BO_ 2365293312 "ISOBUS DD: Secondary or Front Hitch Yaw (PGN 64387, ISO 11783-7)";
CM_ SG_ 2365293312 Front_hitch_yaw_angle "SPN 9714 (Measured)";
CM_ SG_ 2365293312 Front_hitch_yaw_angle_reference_frame "SPN 9715 (Measured)";
CM_ SG_ 2365293312 Front_hitch_yaw_angle_actual_control_mode "SPN 9716 (Measured)";
CM_ SG_ 2365293312 Front_hitch_yaw_limit_status "SPN 9717 (Measured)";
CM_ SG_ 2365293312 Front_hitch_yaw_exit_reason_code "SPN 9718 (Measured)";
CM_ BO_ 2365293568 "ISOBUS DD: Operator Status (PGN 64388, ISO 11783-7)";
CM_ SG_ 2365293568 Operator_Status_Sequence_Counter "SPN 5141 (Measured)";
CM_ SG_ 2365293568 Operator_Presence_state "SPN 9711 (Measured)";
CM_ SG_ 2365293568 Operator_Awareness_state "SPN 9712 (Measured)";
CM_ SG_ 2365293568 Operator_Presence_and_Awareness_Status_Checksum "SPN 9713 (Measured)";
CM_ BO_ 2566655488 "ISOBUS DD: Primary or Rear Hitch Roll and Pitch Sensitivity (PGN 64526, ISO 11783-7)";
CM_ SG_ 2566655488 Rear_hitch_roll_sensitivity "SPN 7812 (Measured)";
CM_ SG_ 2566655488 Rear_hitch_pitch_sensitivity "SPN 7813 (Measured)";
CM_ BO_ 2566655744 "ISOBUS DD: Secondary or Front Hitch Roll and Pitch Sensitivity (PGN 64527, ISO 11783-7)";
CM_ SG_ 2566655744 Front_hitch_roll_sensitivity "SPN 7800 (Measured)";
CM_ SG_ 2566655744 Front_hitch_pitch_sensitivity "SPN 7801 (Measured)";
CM_ BO_ 2566704384 "ISOBUS DD: Drive Strategy Status (PGN 64717, ISO 11783-7)";
CM_ SG_ 2566704384 Drive_strategy_priority_1 "SPN 5727 (Measured)";
CM_ SG_ 2566704384 Drive_strategy_priority_2 "SPN 5728 (Measured)";
CM_ SG_ 2566704384 Drive_strategy_priority_3 "SPN 5729 (Measured)";
CM_ SG_ 2566704384 Drive_strategy_priority_4 "SPN 5730 (Measured)";
CM_ SG_ 2566704384 Drive_strategy_request_state "SPN 5731 (Measured)";
CM_ SG_ 2566704384 Drive_strategy_exit_reason_code "SPN 5732 (Measured)";
CM_ BO_ 2365378048 "ISOBUS DD: Drive Strategy command (PGN 64718, ISO 11783-7)";
CM_ SG_ 2365378048 Drive_strategy_priority_1_request "SPN 5733 (Command)";
CM_ SG_ 2365378048 Drive_strategy_priority_2_request "SPN 5734 (Command)";
CM_ SG_ 2365378048 Drive_strategy_priority_3_request "SPN 5735 (Command)";
CM_ SG_ 2365378048 Drive_strategy_priority_4_request "SPN 5736 (Command)";
CM_ SG_ 2365378048 Restore_operator_drive_strategy_setting_request "SPN 5737 (Command)";
CM_ BO_ 2365391360 "ISOBUS DD: All implements stop operations switch state (PGN 64770, ISO 11783-7)";
CM_ SG_ 2365391360 Stop_all_implement_operations "SPN 5140 (Measured)";
CM_ SG_ 2365391360 Stop_All_Implement_Operations_Transition_Number "SPN 7443 (Measured)";
CM_ BO_ 2365391616 "ISOBUS DD: Implement Operating state command (PGN 64771, ISO 11783-7)";
CM_ SG_ 2365391616 Implement_operating_state_command "SPN 5139 (Command)";
CM_ BO_ 2566730240 "ISOBUS DD: ECU diagnostic protocol (PGN 64818, ISO 11783-7)";
CM_ SG_ 2566730240 Diagnostic_protocol_identification "SPN 21854 (Measured)";
CM_ BO_ 2566734336 "ISOBUS DD: ISOBUS compliance certification (PGN 64834, ISO 11783-7)";
CM_ SG_ 2566734336 ISOBUS_compliance_test_protocol_publication_year "SPN 4313 (Measured)";
CM_ SG_ 2566734336 ISOBUS_compliance_test_protocol_revision "SPN 4314 (Measured)";
CM_ SG_ 2566734336 ISOBUS_compliance_certification_laboratory_ID "SPN 4316 (Measured)";
CM_ SG_ 2566734336 ISOBUS_compliance_certification_type_Minimum_CF "SPN 4317 (Measured)";
CM_ SG_ 2566734336 ISOBUS_compliance_certification_type_TECU_Class_1 "SPN 4318 (Measured)";
CM_ SG_ 2566734336 ISOBUS_compliance_certification_type_TECU_Class_2 "SPN 4319 (Measured)";
CM_ SG_ 2566734336 ISOBUS_compliance_certification_type_TECU_Class_3 "SPN 4320 (Measured)";
CM_ SG_ 2566734336 ISOBUS_compliance_certification_type_Class_3_ECU "SPN 4321 (Measured)";
CM_ SG_ 2566734336 ISOBUS_compliance_certification_type_Virtual_terminal "SPN 4322 (Measured)";
CM_ SG_ 2566734336 ISOBUS_compliance_certification_type_VT_working_set_master "SPN 4323 (Measured)";
CM_ SG_ 2566734336 ISOBUS_compliance_certification_type_VT_working_set_member "SPN 4324 (Measured)";
CM_ SG_ 2566734336 ISOBUS_compliance_certification_type_Task_Controller "SPN 4325 (Measured)";
CM_ SG_ 2566734336 ISOBUS_compliance_certification_type_TC_working_set_master "SPN 4326 (Measured)";
CM_ SG_ 2566734336 ISOBUS_compliance_certification_type_TC_working_set_member "SPN 4327 (Measured)";
CM_ SG_ 2566734336 ISOBUS_compliance_certification_type_File_server "SPN 4328 (Measured)";
CM_ SG_ 2566734336 ISOBUS_compliance_certification_type_GPS_receiver "SPN 4329 (Measured)";
CM_ SG_ 2566734336 ISOBUS_compliance_certification_reference_number "SPN 4330 (Measured)";
CM_ SG_ 2566734336 ISOBUS_compliance_certification_message_revision "SPN 7446 (Measured)";
CM_ BO_ 2365408000 "ISOBUS DD: Machine Selected Speed command (PGN 64835, ISO 11783-7)";
CM_ SG_ 2365408000 Machine_selected_speed_set_point_command "SPN 4310 (Command)";
CM_ SG_ 2365408000 Machine_selected_speed_setpoint_limit "SPN 4311 (Command)";
CM_ SG_ 2365408000 Machine_selected_direction_command "SPN 4312 (Command)";
CM_ BO_ 2365458432 "ISOBUS DD: Required Tractor Facilities message (PGN 65032, ISO 11783-7)";
CM_ SG_ 2365458432 Speed_information_engine_speed "SPN 5233 (Command)";
CM_ SG_ 2365458432 Speed_information_ground_based_speed "SPN 5233 (Command)";
CM_ SG_ 2365458432 Speed_information_wheel_based_speed "SPN 5233 (Command)";
CM_ SG_ 2365458432 Power_management_maintain_power "SPN 5233 (Command)";
CM_ SG_ 2365458432 Power_management_maximum_time_tractor_power "SPN 5233 (Command)";
CM_ SG_ 2365458432 Power_management_key_switch "SPN 5233 (Command)";
CM_ SG_ 2365458432 Tractor_ECU_class_request "SPN 5232 (Command)";
CM_ SG_ 2365458432 Language_command_storage_in_Tractor_ECU "SPN 5233 (Command)";
CM_ SG_ 2365458432 Lighting_minimal_set_as_existing_trailer_connector "SPN 5233 (Command)";
CM_ SG_ 2365458432 PTO_information_rear_shaft_engagement "SPN 5233 (Command)";
CM_ SG_ 2365458432 PTO_information_rear_shaft_speed "SPN 5233 (Command)";
CM_ SG_ 2365458432 Hitch_information_rear_in_work "SPN 5233 (Command)";
CM_ SG_ 2365458432 Hitch_information_rear_position "SPN 5233 (Command)";
CM_ SG_ 2365458432 Estimated_or_measured_auxiliary_valve_status "SPN 5233 (Command)";
CM_ SG_ 2365458432 Lighting_full_implement_lighting_message_set "SPN 5233 (Command)";
CM_ SG_ 2365458432 Additional_hitch_parameters_rear_draft "SPN 5233 (Command)";
CM_ SG_ 2365458432 Speed_and_distance_wheel_based_direction "SPN 5233 (Command)";
CM_ SG_ 2365458432 Speed_and_distance_wheel_based_distance "SPN 5233 (Command)";
CM_ SG_ 2365458432 Speed_and_distance_ground_based_direction "SPN 5233 (Command)";
CM_ SG_ 2365458432 Speed_and_distance_ground_based_distance "SPN 5233 (Command)";
CM_ SG_ 2365458432 Time_date "SPN 5233 (Command)";
CM_ SG_ 2365458432 PTO_commands_rear_PTO_mode_gear_command "SPN 5233 (Command)";
CM_ SG_ 2365458432 Limit_request_status_reporting "SPN 7445 (Command)";
CM_ SG_ 2365458432 Auxiliary_valve_commands "SPN 5233 (Command)";
CM_ SG_ 2365458432 PTO_commands_rear_PTO_engagement_command "SPN 5233 (Command)";
CM_ SG_ 2365458432 PTO_commands_rear_PTO_speed_command "SPN 5233 (Command)";
CM_ SG_ 2365458432 Hitch_commands_rear_hitch_position "SPN 5233 (Command)";
CM_ SG_ 2365458432 Direction_control "SPN 5233 (Command)";
CM_ SG_ 2365458432 Machine_selected_speed_control "SPN 5233 (Command)";
CM_ SG_ 2365458432 Machine_selected_speed "SPN 5233 (Command)";
CM_ SG_ 2365458432 Operator_external_light_controls "SPN 5233 (Command)";
CM_ SG_ 2365458432 Navigational_pseudo_range_noise_statistics "SPN 5233 (Command)";
CM_ SG_ 2365458432 Navigational_system_position_data "SPN 5233 (Command)";
CM_ SG_ 2365458432 Navigational_system_high_output_position "SPN 5233 (Command)";
CM_ SG_ 2365458432 PTO_commands_front_PTO_engagement_command "SPN 5233 (Command)";
CM_ SG_ 2365458432 PTO_commands_front_PTO_speed_command "SPN 5233 (Command)";
CM_ SG_ 2365458432 Hitch_commands_front_hitch_position "SPN 5233 (Command)";
CM_ SG_ 2365458432 Additional_hitch_parameters_front_draft "SPN 5233 (Command)";
CM_ SG_ 2365458432 PTO_information_front_shaft_engagement "SPN 5233 (Command)";
CM_ SG_ 2365458432 PTO_information_front_shaft_speed "SPN 5233 (Command)";
CM_ SG_ 2365458432 Hitch_information_front_in_work "SPN 5233 (Command)";
CM_ SG_ 2365458432 Hitch_information_front_position "SPN 5233 (Command)";
CM_ SG_ 2365458432 Drive_Strategy_Status_and_Commands "SPN 5233 (Command)";
CM_ SG_ 2365458432 External_Guidance_Status_and_Commands "SPN 5233 (Command)";
CM_ SG_ 2365458432 PTO_commands_front_PTO_mode_gear_command "SPN 5233 (Command)";
CM_ SG_ 2365458432 Tractor_facility_reserved_bit_indicator "SPN 5236 (Measured)";
CM_ BO_ 2365458688 "ISOBUS DD: Tractor Facilities response message (PGN 65033, ISO 11783-7)";
CM_ SG_ 2365458688 Speed_information_engine_speed "SPN 5235 (Measured)";
CM_ SG_ 2365458688 Speed_information_ground_based_speed "SPN 5235 (Measured)";
CM_ SG_ 2365458688 Speed_information_wheel_based_speed "SPN 5235 (Measured)";
CM_ SG_ 2365458688 Power_management_maintain_power "SPN 5235 (Measured)";
CM_ SG_ 2365458688 Power_management_maximum_time_tractor_power "SPN 5235 (Measured)";
CM_ SG_ 2365458688 Power_management_key_switch "SPN 5235 (Measured)";
CM_ SG_ 2365458688 Tractor_ECU_class_response "SPN 5234 (Measured)";
CM_ SG_ 2365458688 Language_command_storage_in_Tractor_ECU "SPN 5235 (Measured)";
CM_ SG_ 2365458688 Lighting_minimal_set_as_existing_trailer_connector "SPN 5235 (Measured)";
CM_ SG_ 2365458688 PTO_information_rear_shaft_engagement "SPN 5235 (Measured)";
CM_ SG_ 2365458688 PTO_information_rear_shaft_speed "SPN 5235 (Measured)";
CM_ SG_ 2365458688 Hitch_information_rear_in_work "SPN 5235 (Measured)";
CM_ SG_ 2365458688 Hitch_information_rear_position "SPN 5235 (Measured)";
CM_ SG_ 2365458688 Estimated_or_measured_auxiliary_valve_status "SPN 5235 (Measured)";
CM_ SG_ 2365458688 Lighting_full_implement_lighting_message_set "SPN 5235 (Measured)";
CM_ SG_ 2365458688 Speed_and_distance_wheel_based_direction "SPN 5235 (Measured)";
CM_ SG_ 2365458688 Speed_and_distance_wheel_based_distance "SPN 5235 (Measured)";
CM_ SG_ 2365458688 Speed_and_distance_ground_based_direction "SPN 5235 (Measured)";
CM_ SG_ 2365458688 Speed_and_distance_ground_based_distance "SPN 5235 (Measured)";
CM_ SG_ 2365458688 Time_date "SPN 5235 (Measured)";
CM_ SG_ 2365458688 PTO_commands_rear_PTO_mode_gear_command "SPN 5235 (Measured)";
CM_ SG_ 2365458688 Tractor_facility_response_Limit_request_status_reporting "SPN 7444 (Measured)";
CM_ SG_ 2365458688 Auxiliary_valve_commands "SPN 5235 (Measured)";
CM_ SG_ 2365458688 PTO_commands_rear_PTO_engagement_command "SPN 5235 (Measured)";
CM_ SG_ 2365458688 PTO_commands_rear_PTO_speed_command "SPN 5235 (Measured)";
CM_ SG_ 2365458688 Hitch_commands_rear_hitch_position "SPN 5235 (Measured)";
CM_ SG_ 2365458688 Direction_control "SPN 5235 (Measured)";
CM_ SG_ 2365458688 Machine_selected_speed_control "SPN 5235 (Measured)";
CM_ SG_ 2365458688 Machine_selected_speed "SPN 5235 (Measured)";
CM_ SG_ 2365458688 Operator_external_light_controls "SPN 5235 (Measured)";
CM_ SG_ 2365458688 Navigational_pseudo_range_noise_statistics "SPN 5235 (Measured)";
CM_ SG_ 2365458688 Navigational_system_position_data "SPN 5235 (Measured)";
CM_ SG_ 2365458688 Navigational_system_high_output_position "SPN 5235 (Measured)";
CM_ SG_ 2365458688 PTO_commands_front_PTO_engagement_command "SPN 5235 (Measured)";
CM_ SG_ 2365458688 PTO_commands_front_PTO_speed_command "SPN 5235 (Measured)";
CM_ SG_ 2365458688 Hitch_commands_front_hitch_position "SPN 5235 (Measured)";
CM_ SG_ 2365458688 Additional_hitch_parameters_front_draft "SPN 5235 (Measured)";
CM_ SG_ 2365458688 PTO_information_front_shaft_engagement "SPN 5235 (Measured)";
CM_ SG_ 2365458688 PTO_information_front_shaft_speed "SPN 5235 (Measured)";
CM_ SG_ 2365458688 Hitch_information_front_in_work "SPN 5235 (Measured)";
CM_ SG_ 2365458688 Hitch_information_front_position "SPN 5235 (Measured)";
CM_ SG_ 2365458688 Drive_Strategy_Status_and_Commands "SPN 5235 (Measured)";
CM_ SG_ 2365458688 External_Guidance_Status_and_Commands "SPN 5235 (Measured)";
CM_ SG_ 2365458688 PTO_commands_front_PTO_mode_gear_command "SPN 5235 (Measured)";
CM_ SG_ 2365458688 Tractor_facility_reserved_bit_indicator "SPN 5236 (Measured)";
CM_ BO_ 2365459200 "ISOBUS DD: Tractor control mode command (PGN 65035, ISO 11783-7)";
CM_ SG_ 2365459200 Tractor_control_mode_command_number_1 "SPN 5204 (Command)";
CM_ SG_ 2365459200 Tractor_control_mode_command_number_2 "SPN 5204 (Command)";
CM_ BO_ 2633894912 "ISOBUS DD: Working Set Member (PGN 65036, ISO 11783-7)";
CM_ SG_ 2633894912 NAME_of_Working_Set_Member "SPN 2845 (Measured)";
CM_ BO_ 2633895168 "ISOBUS DD: Working Set Master (PGN 65037, ISO 11783-7)";
CM_ SG_ 2633895168 Number_of_Members_in_Working_Set "SPN 2409 (Measured)";
CM_ BO_ 2566786560 "ISOBUS DD: Response for Repetition Rate (PGN 65038, ISO 11783-7)";
CM_ SG_ 2566786560 PGN_of_the_request_2 "SPN 21855 (Command)";
CM_ SG_ 2566786560 Repetition_rate "SPN 5198 (Measured)";
CM_ BO_ 2566786816 "ISOBUS DD: Language command (PGN 65039, ISO 11783-7)";
CM_ SG_ 2566786816 Language_Code "SPN 2410 (Command)";
CM_ SG_ 2566786816 Time_format "SPN 2413 (Command)";
CM_ SG_ 2566786816 Decimal_symbol "SPN 2411 (Command)";
CM_ SG_ 2566786816 Date_format "SPN 2412 (Command)";
CM_ SG_ 2566786816 Mass_units "SPN 2417 (Command)";
CM_ SG_ 2566786816 Volume_units "SPN 2416 (Command)";
CM_ SG_ 2566786816 Area_units "SPN 2415 (Command)";
CM_ SG_ 2566786816 Distance_units "SPN 2414 (Command)";
CM_ SG_ 2566786816 Units_system "SPN 5197 (Command)";
CM_ SG_ 2566786816 Force_units "SPN 5196 (Command)";
CM_ SG_ 2566786816 Pressure_units "SPN 5195 (Command)";
CM_ SG_ 2566786816 Temperature_units "SPN 5194 (Command)";
CM_ SG_ 2566786816 Country_Code "SPN 9731 (Command)";
CM_ BO_ 2365460480 "ISOBUS DD: Auxiliary valve 0 estimated flow (PGN 65040, ISO 11783-7)";
CM_ SG_ 2365460480 Auxiliary_valve_0_extend_port_estimated_flow "SPN 1901 (Estimated)";
CM_ SG_ 2365460480 Auxiliary_valve_0_retract_port_estimated_flow "SPN 1902 (Estimated)";
CM_ SG_ 2365460480 Auxiliary_valve_number_0_valve_state "SPN 1903 (Measured)";
CM_ SG_ 2365460480 Auxiliary_valve_0_fail_safe_mode "SPN 1910 (Measured)";
CM_ SG_ 2365460480 Auxiliary_valve_number_0_estimated_flow_limit_status "SPN 5161 (Measured)";
CM_ SG_ 2365460480 Auxiliary_valve_0_exit_reason_code "SPN 5800 (Measured)";
CM_ SG_ 2365460480 Auxiliary_valve_0_estimated_flow_high_resolution "SPN 9732 (Estimated)";
CM_ BO_ 2365460736 "ISOBUS DD: Auxiliary valve 1 estimated flow (PGN 65041, ISO 11783-7)";
CM_ SG_ 2365460736 Auxiliary_valve_number_01_extend_port_estimated_flow "SPN 1913 (Estimated)";
CM_ SG_ 2365460736 Auxiliary_valve_number_01_retract_port_estimated_flow "SPN 1914 (Estimated)";
CM_ SG_ 2365460736 Auxiliary_valve_number_01_valve_state "SPN 1915 (Measured)";
CM_ SG_ 2365460736 Auxiliary_valve_01_fail_safe_mode "SPN 1922 (Measured)";
CM_ SG_ 2365460736 Auxiliary_valve_number_01_estimated_flow_limit_status "SPN 5163 (Measured)";
CM_ SG_ 2365460736 Auxiliary_valve_01_exit_reason_code "SPN 5801 (Measured)";
CM_ SG_ 2365460736 Auxiliary_valve_01_estimated_flow_high_resolution "SPN 9733 (Estimated)";
CM_ BO_ 2365460992 "ISOBUS DD: Auxiliary valve 2 estimated flow (PGN 65042, ISO 11783-7)";
CM_ SG_ 2365460992 Auxiliary_valve_number_02_extend_port_estimated_flow "SPN 1925 (Estimated)";
CM_ SG_ 2365460992 Auxiliary_valve_number_02_retract_port_estimated_flow "SPN 1926 (Estimated)";
CM_ SG_ 2365460992 Auxiliary_valve_number_02_valve_state "SPN 1927 (Measured)";
CM_ SG_ 2365460992 Auxiliary_valve_02_fail_safe_mode "SPN 1934 (Measured)";
CM_ SG_ 2365460992 Auxiliary_valve_number_02_estimated_flow_limit_status "SPN 5165 (Measured)";
CM_ SG_ 2365460992 Auxiliary_valve_02_exit_reason_code "SPN 5802 (Measured)";
CM_ SG_ 2365460992 Auxiliary_valve_02_estimated_flow_high_resolution "SPN 9734 (Estimated)";
CM_ BO_ 2365461248 "ISOBUS DD: Auxiliary valve 3 estimated flow (PGN 65043, ISO 11783-7)";
CM_ SG_ 2365461248 Auxiliary_valve_number_03_extend_port_estimated_flow "SPN 1937 (Estimated)";
CM_ SG_ 2365461248 Auxiliary_valve_number_03_retract_port_estimated_flow "SPN 1938 (Estimated)";
CM_ SG_ 2365461248 Auxiliary_valve_number_03_valve_state "SPN 1939 (Measured)";
CM_ SG_ 2365461248 Auxiliary_valve_03_fail_safe_mode "SPN 1946 (Measured)";
CM_ SG_ 2365461248 Auxiliary_valve_number_03_estimated_flow_limit_status "SPN 5167 (Measured)";
CM_ SG_ 2365461248 Auxiliary_valve_03_exit_reason_code "SPN 5803 (Measured)";
CM_ SG_ 2365461248 Auxiliary_valve_03_estimated_flow_high_resolution "SPN 9735 (Estimated)";
CM_ BO_ 2365461504 "ISOBUS DD: Auxiliary valve 4 estimated flow (PGN 65044, ISO 11783-7)";
CM_ SG_ 2365461504 Auxiliary_valve_number_04_extend_port_estimated_flow "SPN 1949 (Estimated)";
CM_ SG_ 2365461504 Auxiliary_valve_number_04_retract_port_estimated_flow "SPN 1950 (Estimated)";
CM_ SG_ 2365461504 Auxiliary_valve_number_04_valve_state "SPN 1951 (Measured)";
CM_ SG_ 2365461504 Auxiliary_valve_04_fail_safe_mode "SPN 1958 (Measured)";
CM_ SG_ 2365461504 Auxiliary_valve_number_04_estimated_flow_limit_status "SPN 5169 (Measured)";
CM_ SG_ 2365461504 Auxiliary_valve_04_exit_reason_code "SPN 5804 (Measured)";
CM_ SG_ 2365461504 Auxiliary_valve_04_estimated_flow_high_resolution "SPN 9736 (Estimated)";
CM_ BO_ 2365461760 "ISOBUS DD: Auxiliary valve 5 estimated flow (PGN 65045, ISO 11783-7)";
CM_ SG_ 2365461760 Auxiliary_valve_number_05_extend_port_estimated_flow "SPN 1961 (Estimated)";
CM_ SG_ 2365461760 Auxiliary_valve_number_05_retract_port_estimated_flow "SPN 1962 (Estimated)";
CM_ SG_ 2365461760 Auxiliary_valve_number_05_valve_state "SPN 1963 (Measured)";
CM_ SG_ 2365461760 Auxiliary_valve_05_fail_safe_mode "SPN 1970 (Measured)";
CM_ SG_ 2365461760 Auxiliary_valve_number_05_estimated_flow_limit_status "SPN 5171 (Measured)";
CM_ SG_ 2365461760 Auxiliary_valve_05_exit_reason_code "SPN 5805 (Measured)";
CM_ SG_ 2365461760 Auxiliary_valve_05_estimated_flow_high_resolution "SPN 9737 (Estimated)";
CM_ BO_ 2365462016 "ISOBUS DD: Auxiliary valve 6 estimated flow (PGN 65046, ISO 11783-7)";
CM_ SG_ 2365462016 Auxiliary_valve_number_06_extend_port_estimated_flow "SPN 1973 (Estimated)";
CM_ SG_ 2365462016 Auxiliary_valve_number_06_retract_port_estimated_flow "SPN 1974 (Estimated)";
CM_ SG_ 2365462016 Auxiliary_valve_number_06_valve_state "SPN 1975 (Measured)";
CM_ SG_ 2365462016 Auxiliary_valve_06_fail_safe_mode "SPN 1982 (Measured)";
CM_ SG_ 2365462016 Auxiliary_valve_number_06_estimated_flow_limit_status "SPN 5173 (Measured)";
CM_ SG_ 2365462016 Auxiliary_valve_06_exit_reason_code "SPN 5806 (Measured)";
CM_ SG_ 2365462016 Auxiliary_valve_06_estimated_flow_high_resolution "SPN 9738 (Estimated)";
CM_ BO_ 2365462272 "ISOBUS DD: Auxiliary valve 7 estimated flow (PGN 65047, ISO 11783-7)";
CM_ SG_ 2365462272 Auxiliary_valve_number_07_extend_port_estimated_flow "SPN 1985 (Estimated)";
CM_ SG_ 2365462272 Auxiliary_valve_number_07_retract_port_estimated_flow "SPN 1986 (Estimated)";
CM_ SG_ 2365462272 Auxiliary_valve_number_07_valve_state "SPN 1987 (Measured)";
CM_ SG_ 2365462272 Auxiliary_valve_07_fail_safe_mode "SPN 1994 (Measured)";
CM_ SG_ 2365462272 Auxiliary_valve_number_07_estimated_flow_limit_status "SPN 5175 (Measured)";
CM_ SG_ 2365462272 Auxiliary_valve_07_exit_reason_code "SPN 5807 (Measured)";
CM_ SG_ 2365462272 Auxiliary_valve_07_estimated_flow_high_resolution "SPN 9739 (Estimated)";
CM_ BO_ 2365462528 "ISOBUS DD: Auxiliary valve 8 estimated flow (PGN 65048, ISO 11783-7)";
CM_ SG_ 2365462528 Auxiliary_valve_number_08_extend_port_estimated_flow "SPN 1997 (Estimated)";
CM_ SG_ 2365462528 Auxiliary_valve_number_08_retract_port_estimated_flow "SPN 1998 (Estimated)";
CM_ SG_ 2365462528 Auxiliary_valve_number_08_valve_state "SPN 1999 (Measured)";
CM_ SG_ 2365462528 Auxiliary_valve_08_fail_safe_mode "SPN 2262 (Measured)";
CM_ SG_ 2365462528 Auxiliary_valve_number_08_estimated_flow_limit_status "SPN 5177 (Measured)";
CM_ SG_ 2365462528 Auxiliary_valve_08_exit_reason_code "SPN 5808 (Measured)";
CM_ SG_ 2365462528 Auxiliary_valve_08_estimated_flow_high_resolution "SPN 9740 (Estimated)";
CM_ BO_ 2365462784 "ISOBUS DD: Auxiliary valve 9 estimated flow (PGN 65049, ISO 11783-7)";
CM_ SG_ 2365462784 Auxiliary_valve_number_09_extend_port_estimated_flow "SPN 2265 (Estimated)";
CM_ SG_ 2365462784 Auxiliary_valve_number_09_retract_port_estimated_flow "SPN 2266 (Estimated)";
CM_ SG_ 2365462784 Auxiliary_valve_number_09_valve_state "SPN 2267 (Measured)";
CM_ SG_ 2365462784 Auxiliary_valve_09_fail_safe_mode "SPN 2274 (Measured)";
CM_ SG_ 2365462784 Auxiliary_valve_number_09_estimated_flow_limit_status "SPN 5179 (Measured)";
CM_ SG_ 2365462784 Auxiliary_valve_09_exit_reason_code "SPN 5809 (Measured)";
CM_ SG_ 2365462784 Auxiliary_valve_09_estimated_flow_high_resolution "SPN 9741 (Estimated)";
CM_ BO_ 2365463040 "ISOBUS DD: Auxiliary valve 10 estimated flow (PGN 65050, ISO 11783-7)";
CM_ SG_ 2365463040 Auxiliary_valve_number_10_extend_port_estimated_flow "SPN 2277 (Estimated)";
CM_ SG_ 2365463040 Auxiliary_valve_number_10_retract_port_estimated_flow "SPN 2278 (Estimated)";
CM_ SG_ 2365463040 Auxiliary_valve_number_10_valve_state "SPN 2279 (Measured)";
CM_ SG_ 2365463040 Auxiliary_valve_10_fail_safe_mode "SPN 2286 (Measured)";
CM_ SG_ 2365463040 Auxiliary_valve_number_10_estimated_flow_limit_status "SPN 5181 (Measured)";
CM_ SG_ 2365463040 Auxiliary_valve_10_exit_reason_code "SPN 5810 (Measured)";
CM_ SG_ 2365463040 Auxiliary_valve_10_estimated_flow_high_resolution "SPN 9742 (Estimated)";
CM_ BO_ 2365463296 "ISOBUS DD: Auxiliary valve 11 estimated flow (PGN 65051, ISO 11783-7)";
CM_ SG_ 2365463296 Auxiliary_valve_number_11_extend_port_estimated_flow "SPN 2289 (Estimated)";
CM_ SG_ 2365463296 Auxiliary_valve_number_11_retract_port_estimated_flow "SPN 2290 (Estimated)";
CM_ SG_ 2365463296 Auxiliary_valve_number_11_valve_state "SPN 2291 (Measured)";
CM_ SG_ 2365463296 Auxiliary_valve_11_fail_safe_mode "SPN 2298 (Measured)";
CM_ SG_ 2365463296 Auxiliary_valve_number_11_estimated_flow_limit_status "SPN 5183 (Measured)";
CM_ SG_ 2365463296 Auxiliary_valve_11_exit_reason_code "SPN 5811 (Measured)";
CM_ SG_ 2365463296 Auxiliary_valve_11_estimated_flow_high_resolution "SPN 9743 (Estimated)";
CM_ BO_ 2365463552 "ISOBUS DD: Auxiliary valve 12 estimated flow (PGN 65052, ISO 11783-7)";
CM_ SG_ 2365463552 Auxiliary_valve_number_12_extend_port_estimated_flow "SPN 2301 (Estimated)";
CM_ SG_ 2365463552 Auxiliary_valve_number_12_retract_port_estimated_flow "SPN 2302 (Estimated)";
CM_ SG_ 2365463552 Auxiliary_valve_number_12_valve_state "SPN 2303 (Measured)";
CM_ SG_ 2365463552 Auxiliary_valve_12_fail_safe_mode "SPN 2310 (Measured)";
CM_ SG_ 2365463552 Auxiliary_valve_number_12_estimated_flow_limit_status "SPN 5185 (Measured)";
CM_ SG_ 2365463552 Auxiliary_valve_12_exit_reason_code "SPN 5812 (Measured)";
CM_ SG_ 2365463552 Auxiliary_valve_12_estimated_flow_high_resolution "SPN 9744 (Estimated)";
CM_ BO_ 2365463808 "ISOBUS DD: Auxiliary valve 13 estimated flow (PGN 65053, ISO 11783-7)";
CM_ SG_ 2365463808 Auxiliary_valve_number_13_extend_port_estimated_flow "SPN 2313 (Estimated)";
CM_ SG_ 2365463808 Auxiliary_valve_number_13_retract_port_estimated_flow "SPN 2314 (Estimated)";
CM_ SG_ 2365463808 Auxiliary_valve_number_13_valve_state "SPN 2315 (Measured)";
CM_ SG_ 2365463808 Auxiliary_valve_13_fail_safe_mode "SPN 2322 (Measured)";
CM_ SG_ 2365463808 Auxiliary_valve_number_13_estimated_flow_limit_status "SPN 5187 (Measured)";
CM_ SG_ 2365463808 Auxiliary_valve_13_exit_reason_code "SPN 5813 (Measured)";
CM_ SG_ 2365463808 Auxiliary_valve_13_estimated_flow_high_resolution "SPN 9745 (Estimated)";
CM_ BO_ 2365464064 "ISOBUS DD: Auxiliary valve 14 estimated flow (PGN 65054, ISO 11783-7)";
CM_ SG_ 2365464064 Auxiliary_valve_number_14_extend_port_estimated_flow "SPN 2325 (Estimated)";
CM_ SG_ 2365464064 Auxiliary_valve_number_14_retract_port_estimated_flow "SPN 2326 (Estimated)";
CM_ SG_ 2365464064 Auxiliary_valve_number_14_valve_state "SPN 2327 (Measured)";
CM_ SG_ 2365464064 Auxiliary_valve_14_fail_safe_mode "SPN 2334 (Measured)";
CM_ SG_ 2365464064 Auxiliary_valve_number_14_estimated_flow_limit_status "SPN 5189 (Measured)";
CM_ SG_ 2365464064 Auxiliary_valve_14_exit_reason_code "SPN 5814 (Measured)";
CM_ SG_ 2365464064 Auxiliary_valve_14_estimated_flow_high_resolution "SPN 9746 (Estimated)";
CM_ BO_ 2365464320 "ISOBUS DD: Auxiliary valve 15 estimated flow (PGN 65055, ISO 11783-7)";
CM_ SG_ 2365464320 Auxiliary_valve_number_15_extend_port_estimated_flow "SPN 2337 (Estimated)";
CM_ SG_ 2365464320 Auxiliary_valve_number_15_retract_port_estimated_flow "SPN 2338 (Estimated)";
CM_ SG_ 2365464320 Auxiliary_valve_number_15_valve_state "SPN 2339 (Measured)";
CM_ SG_ 2365464320 Auxiliary_valve_15_fail_safe_mode "SPN 2346 (Measured)";
CM_ SG_ 2365464320 Auxiliary_valve_number_15_estimated_flow_limit_status "SPN 5191 (Measured)";
CM_ SG_ 2365464320 Auxiliary_valve_15_exit_reason_code "SPN 5815 (Measured)";
CM_ SG_ 2365464320 Auxiliary_valve_15_estimated_flow_high_resolution "SPN 9747 (Estimated)";
CM_ BO_ 2365464576 "ISOBUS DD: Auxiliary valve 0 measured flow (PGN 65056, ISO 11783-7)";
CM_ SG_ 2365464576 Auxiliary_valve_number_0_extend_port_measured_flow "SPN 1899 (Measured)";
CM_ SG_ 2365464576 Auxiliary_valve_number_0_retract_port_measured_flow "SPN 1900 (Measured)";
CM_ SG_ 2365464576 Auxiliary_valve_number_0_return_port_pressure "SPN 1906 (Measured)";
CM_ SG_ 2365464576 Auxiliary_valve_number_0_extend_port_pressure "SPN 1904 (Measured)";
CM_ SG_ 2365464576 Auxiliary_valve_0_retract_port_pressure "SPN 1905 (Measured)";
CM_ SG_ 2365464576 Auxiliary_valve_number_0_measured_flow_limit_status "SPN 5160 (Measured)";
CM_ BO_ 2365464832 "ISOBUS DD: Auxiliary valve 1 measured flow (PGN 65057, ISO 11783-7)";
CM_ SG_ 2365464832 Auxiliary_valve_number_01_extend_port_measured_flow "SPN 1911 (Measured)";
CM_ SG_ 2365464832 Auxiliary_valve_number_01_retract_port_measured_flow "SPN 1912 (Measured)";
CM_ SG_ 2365464832 Auxiliary_valve_number_01_return_port_pressure "SPN 1918 (Measured)";
CM_ SG_ 2365464832 Auxiliary_valve_number_01_extend_port_pressure "SPN 1916 (Measured)";
CM_ SG_ 2365464832 Auxiliary_valve_number_01_retract_port_pressure "SPN 1917 (Measured)";
CM_ SG_ 2365464832 Auxiliary_valve_number_01_measured_flow_limit_status "SPN 5162 (Measured)";
CM_ BO_ 2365465088 "ISOBUS DD: Auxiliary valve 2 measured flow (PGN 65058, ISO 11783-7)";
CM_ SG_ 2365465088 Auxiliary_valve_number_02_extend_port_measured_flow "SPN 1923 (Measured)";
CM_ SG_ 2365465088 Auxiliary_valve_number_02_retract_port_measured_flow "SPN 1924 (Measured)";
CM_ SG_ 2365465088 Auxiliary_valve_number_02_return_port_pressure "SPN 1930 (Measured)";
CM_ SG_ 2365465088 Auxiliary_valve_number_02_extend_port_pressure "SPN 1928 (Measured)";
CM_ SG_ 2365465088 Auxiliary_valve_number_02_retract_port_pressure "SPN 1929 (Measured)";
CM_ SG_ 2365465088 Auxiliary_valve_number_02_measured_flow_limit_status "SPN 5164 (Measured)";
CM_ BO_ 2365465344 "ISOBUS DD: Auxiliary valve 3 measured flow (PGN 65059, ISO 11783-7)";
CM_ SG_ 2365465344 Auxiliary_valve_number_03_extend_port_measured_flow "SPN 1935 (Measured)";
CM_ SG_ 2365465344 Auxiliary_valve_number_03_retract_port_measured_flow "SPN 1936 (Measured)";
CM_ SG_ 2365465344 Auxiliary_valve_number_03_return_port_pressure "SPN 1942 (Measured)";
CM_ SG_ 2365465344 Auxiliary_valve_number_03_extend_port_pressure "SPN 1940 (Measured)";
CM_ SG_ 2365465344 Auxiliary_valve_number_03_retract_port_pressure "SPN 1941 (Measured)";
CM_ SG_ 2365465344 Auxiliary_valve_number_03_measured_flow_limit_status "SPN 5166 (Measured)";
CM_ BO_ 2365465600 "ISOBUS DD: Auxiliary valve 4 measured flow (PGN 65060, ISO 11783-7)";
CM_ SG_ 2365465600 Auxiliary_valve_number_04_extend_port_measured_flow "SPN 1947 (Measured)";
CM_ SG_ 2365465600 Auxiliary_valve_number_04_retract_port_measured_flow "SPN 1948 (Measured)";
CM_ SG_ 2365465600 Auxiliary_valve_number_04_return_port_pressure "SPN 1954 (Measured)";
CM_ SG_ 2365465600 Auxiliary_valve_number_04_extend_port_pressure "SPN 1952 (Measured)";
CM_ SG_ 2365465600 Auxiliary_valve_number_04_retract_port_pressure "SPN 1953 (Measured)";
CM_ SG_ 2365465600 Auxiliary_valve_number_04_measured_flow_limit_status "SPN 5168 (Measured)";
CM_ BO_ 2365465856 "ISOBUS DD: Auxiliary valve 5 measured flow (PGN 65061, ISO 11783-7)";
CM_ SG_ 2365465856 Auxiliary_valve_number_05_extend_port_measured_flow "SPN 1959 (Measured)";
CM_ SG_ 2365465856 Auxiliary_valve_number_05_retract_port_measured_flow "SPN 1960 (Measured)";
CM_ SG_ 2365465856 Auxiliary_valve_number_05_return_port_pressure "SPN 1966 (Measured)";
CM_ SG_ 2365465856 Auxiliary_valve_number_05_extend_port_pressure "SPN 1964 (Measured)";
CM_ SG_ 2365465856 Auxiliary_valve_number_05_retract_port_pressure "SPN 1965 (Measured)";
CM_ SG_ 2365465856 Auxiliary_valve_number_05_measured_flow_limit_status "SPN 5170 (Measured)";
CM_ BO_ 2365466112 "ISOBUS DD: Auxiliary valve 6 measured flow (PGN 65062, ISO 11783-7)";
CM_ SG_ 2365466112 Auxiliary_valve_number_06_extend_port_measured_flow "SPN 1971 (Measured)";
CM_ SG_ 2365466112 Auxiliary_valve_number_06_retract_port_measured_flow "SPN 1972 (Measured)";
CM_ SG_ 2365466112 Auxiliary_valve_number_06_return_port_pressure "SPN 1978 (Measured)";
CM_ SG_ 2365466112 Auxiliary_valve_number_06_extend_port_pressure "SPN 1976 (Measured)";
CM_ SG_ 2365466112 Auxiliary_valve_number_06_retract_port_pressure "SPN 1977 (Measured)";
CM_ SG_ 2365466112 Auxiliary_valve_number_06_measured_flow_limit_status "SPN 5172 (Measured)";
CM_ BO_ 2365466368 "ISOBUS DD: Auxiliary valve 7 measured flow (PGN 65063, ISO 11783-7)";
CM_ SG_ 2365466368 Auxiliary_valve_number_07_extend_port_measured_flow "SPN 1983 (Measured)";
CM_ SG_ 2365466368 Auxiliary_valve_number_07_retract_port_measured_flow "SPN 1984 (Measured)";
CM_ SG_ 2365466368 Auxiliary_valve_number_07_return_port_pressure "SPN 1990 (Measured)";
CM_ SG_ 2365466368 Auxiliary_valve_number_07_extend_port_pressure "SPN 1988 (Measured)";
CM_ SG_ 2365466368 Auxiliary_valve_number_07_retract_port_pressure "SPN 1989 (Measured)";
CM_ SG_ 2365466368 Auxiliary_valve_number_07_measured_flow_limit_status "SPN 5174 (Measured)";
CM_ BO_ 2365466624 "ISOBUS DD: Auxiliary valve 8 measured flow (PGN 65064, ISO 11783-7)";
CM_ SG_ 2365466624 Auxiliary_valve_number_08_extend_port_measured_flow "SPN 1995 (Measured)";
CM_ SG_ 2365466624 Auxiliary_valve_number_08_retract_port_measured_flow "SPN 1996 (Measured)";
CM_ SG_ 2365466624 Auxiliary_valve_number_08_return_port_pressure "SPN 2258 (Measured)";
CM_ SG_ 2365466624 Auxiliary_valve_number_08_extend_port_pressure "SPN 2256 (Measured)";
CM_ SG_ 2365466624 Auxiliary_valve_number_08_retract_port_pressure "SPN 2257 (Measured)";
CM_ SG_ 2365466624 Auxiliary_valve_number_08_measured_flow_limit_status "SPN 5176 (Measured)";
CM_ BO_ 2365466880 "ISOBUS DD: Auxiliary valve 9 measured flow (PGN 65065, ISO 11783-7)";
CM_ SG_ 2365466880 Auxiliary_valve_number_09_extend_port_measured_flow "SPN 2263 (Measured)";
CM_ SG_ 2365466880 Auxiliary_valve_number_09_retract_port_measured_flow "SPN 2264 (Measured)";
CM_ SG_ 2365466880 Auxiliary_valve_number_09_return_port_pressure "SPN 2270 (Measured)";
CM_ SG_ 2365466880 Auxiliary_valve_number_09_extend_port_pressure "SPN 2268 (Measured)";
CM_ SG_ 2365466880 Auxiliary_valve_number_09_retract_port_pressure "SPN 2269 (Measured)";
CM_ SG_ 2365466880 Auxiliary_valve_number_09_measured_flow_limit_status "SPN 5178 (Measured)";
CM_ BO_ 2365467136 "ISOBUS DD: Auxiliary valve 10 measured flow (PGN 65066, ISO 11783-7)";
CM_ SG_ 2365467136 Auxiliary_valve_number_10_extend_port_measured_flow "SPN 2275 (Measured)";
CM_ SG_ 2365467136 Auxiliary_valve_number_10_retract_port_measured_flow "SPN 2276 (Measured)";
CM_ SG_ 2365467136 Auxiliary_valve_number_10_return_port_pressure "SPN 2282 (Measured)";
CM_ SG_ 2365467136 Auxiliary_valve_number_10_extend_port_pressure "SPN 2280 (Measured)";
CM_ SG_ 2365467136 Auxiliary_valve_number_10_retract_port_pressure "SPN 2281 (Measured)";
CM_ SG_ 2365467136 Auxiliary_valve_number_10_measured_flow_limit_status "SPN 5180 (Measured)";
CM_ BO_ 2365467392 "ISOBUS DD: Auxiliary valve 11 measured flow (PGN 65067, ISO 11783-7)";
CM_ SG_ 2365467392 Auxiliary_valve_number_11_extend_port_measured_flow "SPN 2287 (Measured)";
CM_ SG_ 2365467392 Auxiliary_valve_number_11_retract_port_measured_flow "SPN 2288 (Measured)";
CM_ SG_ 2365467392 Auxiliary_valve_number_11_return_port_pressure "SPN 2294 (Measured)";
CM_ SG_ 2365467392 Auxiliary_valve_number_11_extend_port_pressure "SPN 2292 (Measured)";
CM_ SG_ 2365467392 Auxiliary_valve_number_11_retract_port_pressure "SPN 2293 (Measured)";
CM_ SG_ 2365467392 Auxiliary_valve_number_11_measured_flow_limit_status "SPN 5182 (Measured)";
CM_ BO_ 2365467648 "ISOBUS DD: Auxiliary valve 12 measured flow (PGN 65068, ISO 11783-7)";
CM_ SG_ 2365467648 Auxiliary_valve_number_12_extend_port_measured_flow "SPN 2299 (Measured)";
CM_ SG_ 2365467648 Auxiliary_valve_number_12_retract_port_measured_flow "SPN 2300 (Measured)";
CM_ SG_ 2365467648 Auxiliary_valve_number_12_return_port_pressure "SPN 2306 (Measured)";
CM_ SG_ 2365467648 Auxiliary_valve_number_12_extend_port_pressure "SPN 2304 (Measured)";
CM_ SG_ 2365467648 Auxiliary_valve_number_12_retract_port_pressure "SPN 2305 (Measured)";
CM_ SG_ 2365467648 Auxiliary_valve_number_12_measured_flow_limit_status "SPN 5184 (Measured)";
CM_ BO_ 2365467904 "ISOBUS DD: Auxiliary valve 13 measured flow (PGN 65069, ISO 11783-7)";
CM_ SG_ 2365467904 Auxiliary_valve_number_13_extend_port_measured_flow "SPN 2311 (Measured)";
CM_ SG_ 2365467904 Auxiliary_valve_number_13_retract_port_measured_flow "SPN 2312 (Measured)";
CM_ SG_ 2365467904 Auxiliary_valve_number_13_return_port_pressure "SPN 2318 (Measured)";
CM_ SG_ 2365467904 Auxiliary_valve_number_13_extend_port_pressure "SPN 2316 (Measured)";
CM_ SG_ 2365467904 Auxiliary_valve_number_13_retract_port_pressure "SPN 2317 (Measured)";
CM_ SG_ 2365467904 Auxiliary_valve_number_13_measured_flow_limit_status "SPN 5186 (Measured)";
CM_ BO_ 2365468160 "ISOBUS DD: Auxiliary valve 14 measured flow (PGN 65070, ISO 11783-7)";
CM_ SG_ 2365468160 Auxiliary_valve_number_14_extend_port_measured_flow "SPN 2323 (Measured)";
CM_ SG_ 2365468160 Auxiliary_valve_number_14_retract_port_measured_flow "SPN 2324 (Measured)";
CM_ SG_ 2365468160 Auxiliary_valve_number_14_return_port_pressure "SPN 2330 (Measured)";
CM_ SG_ 2365468160 Auxiliary_valve_number_14_extend_port_pressure "SPN 2328 (Measured)";
CM_ SG_ 2365468160 Auxiliary_valve_number_14_retract_port_pressure "SPN 2329 (Measured)";
CM_ SG_ 2365468160 Auxiliary_valve_number_14_measured_flow_limit_status "SPN 5188 (Measured)";
CM_ BO_ 2365468416 "ISOBUS DD: Auxiliary valve 15 measured flow (PGN 65071, ISO 11783-7)";
CM_ SG_ 2365468416 Auxiliary_valve_number_15_extend_port_measured_flow "SPN 2335 (Measured)";
CM_ SG_ 2365468416 Auxiliary_valve_number_15_retract_port_measured_flow "SPN 2336 (Measured)";
CM_ SG_ 2365468416 Auxiliary_valve_number_15_return_port_pressure "SPN 2342 (Measured)";
CM_ SG_ 2365468416 Auxiliary_valve_number_15_extend_port_pressure "SPN 2340 (Measured)";
CM_ SG_ 2365468416 Auxiliary_valve_number_15_retract_port_pressure "SPN 2341 (Measured)";
CM_ SG_ 2365468416 Auxiliary_valve_number_15_measured_flow_limit_status "SPN 5190 (Measured)";
CM_ BO_ 2365468672 "ISOBUS DD: Auxiliary valve 0 command (PGN 65072, ISO 11783-7)";
CM_ SG_ 2365468672 Auxiliary_valve_number_0_port_flow_Command "SPN 1907 (Command)";
CM_ SG_ 2365468672 Auxiliary_valve_number_0_Resolution_mode_Command "SPN 7872 (Command)";
CM_ SG_ 2365468672 Auxiliary_valve_number_0_state_Command "SPN 1908 (Command)";
CM_ SG_ 2365468672 Auxiliary_valve_number_0_fail_safe_mode_Command "SPN 1909 (Command)";
CM_ SG_ 2365468672 Auxiliary_valve_number_0_port_flow_Extended_Resolution_Command "SPN 7856 (Command)";
CM_ BO_ 2365468928 "ISOBUS DD: Auxiliary valve 1 command (PGN 65073, ISO 11783-7)";
CM_ SG_ 2365468928 Auxiliary_valve_number_1_port_flow_Command "SPN 1919 (Command)";
CM_ SG_ 2365468928 Auxiliary_valve_number_1_Resolution_mode_Command "SPN 7873 (Command)";
CM_ SG_ 2365468928 Auxiliary_valve_number_1_state_Command "SPN 1920 (Command)";
CM_ SG_ 2365468928 Auxiliary_valve_number_1_fail_safe_mode_Command "SPN 1921 (Command)";
CM_ SG_ 2365468928 Auxiliary_valve_number_1_port_flow_Extended_Resolution_Command "SPN 7857 (Command)";
CM_ BO_ 2365469184 "ISOBUS DD: Auxiliary valve 2 command (PGN 65074, ISO 11783-7)";
CM_ SG_ 2365469184 Auxiliary_valve_number_2_port_flow_Command "SPN 1931 (Command)";
CM_ SG_ 2365469184 Auxiliary_valve_number_2_Resolution_mode_Command "SPN 7874 (Command)";
CM_ SG_ 2365469184 Auxiliary_valve_number_2_state_Command "SPN 1932 (Command)";
CM_ SG_ 2365469184 Auxiliary_valve_number_2_fail_safe_mode_Command "SPN 1933 (Command)";
CM_ SG_ 2365469184 Auxiliary_valve_number_2_port_flow_Extended_Resolution_Command "SPN 7858 (Command)";
CM_ BO_ 2365469440 "ISOBUS DD: Auxiliary valve 3 command (PGN 65075, ISO 11783-7)";
CM_ SG_ 2365469440 Auxiliary_valve_number_3_port_flow_Command "SPN 1943 (Command)";
CM_ SG_ 2365469440 Auxiliary_valve_number_3_Resolution_mode_Command "SPN 7875 (Command)";
CM_ SG_ 2365469440 Auxiliary_valve_number_3_state_Command "SPN 1944 (Command)";
CM_ SG_ 2365469440 Auxiliary_valve_number_3_fail_safe_mode_Command "SPN 1945 (Command)";
CM_ SG_ 2365469440 Auxiliary_valve_number_3_port_flow_Extended_Resolution_Command "SPN 7859 (Command)";
CM_ BO_ 2365469696 "ISOBUS DD: Auxiliary valve 4 command (PGN 65076, ISO 11783-7)";
CM_ SG_ 2365469696 Auxiliary_valve_number_4_port_flow_Command "SPN 1955 (Command)";
CM_ SG_ 2365469696 Auxiliary_valve_number_4_Resolution_mode_Command "SPN 7876 (Command)";
CM_ SG_ 2365469696 Auxiliary_valve_number_4_state_Command "SPN 1956 (Command)";
CM_ SG_ 2365469696 Auxiliary_valve_number_4_fail_safe_mode_Command "SPN 1957 (Command)";
CM_ SG_ 2365469696 Auxiliary_valve_number_4_port_flow_Extended_Resolution_Command "SPN 7860 (Command)";
CM_ BO_ 2365469952 "ISOBUS DD: Auxiliary valve 5 command (PGN 65077, ISO 11783-7)";
CM_ SG_ 2365469952 Auxiliary_valve_number_5_port_flow_Command "SPN 1967 (Command)";
CM_ SG_ 2365469952 Auxiliary_valve_number_5_Resolution_mode_Command "SPN 7877 (Command)";
CM_ SG_ 2365469952 Auxiliary_valve_number_5_state_Command "SPN 1968 (Command)";
CM_ SG_ 2365469952 Auxiliary_valve_number_5_fail_safe_mode_Command "SPN 1969 (Command)";
CM_ SG_ 2365469952 Auxiliary_valve_number_5_port_flow_Extended_Resolution_Command "SPN 7861 (Command)";
CM_ BO_ 2365470208 "ISOBUS DD: Auxiliary valve 6 command (PGN 65078, ISO 11783-7)";
CM_ SG_ 2365470208 Auxiliary_valve_number_6_port_flow_Command "SPN 1979 (Command)";
CM_ SG_ 2365470208 Auxiliary_valve_number_6_Resolution_mode_Command "SPN 7878 (Command)";
CM_ SG_ 2365470208 Auxiliary_valve_number_6_state_Command "SPN 1980 (Command)";
CM_ SG_ 2365470208 Auxiliary_valve_number_6_fail_safe_mode_Command "SPN 1981 (Command)";
CM_ SG_ 2365470208 Auxiliary_valve_number_6_port_flow_Extended_Resolution_Command "SPN 7862 (Command)";
CM_ BO_ 2365470464 "ISOBUS DD: Auxiliary valve 7 command (PGN 65079, ISO 11783-7)";
CM_ SG_ 2365470464 Auxiliary_valve_number_7_port_flow_Command "SPN 1991 (Command)";
CM_ SG_ 2365470464 Auxiliary_valve_number_7_Resolution_mode_Command "SPN 7879 (Command)";
CM_ SG_ 2365470464 Auxiliary_valve_number_7_state_Command "SPN 1992 (Command)";
CM_ SG_ 2365470464 Auxiliary_valve_number_7_fail_safe_mode_Command "SPN 1993 (Command)";
CM_ SG_ 2365470464 Auxiliary_valve_number_7_port_flow_Extended_Resolution_Command "SPN 7863 (Command)";
CM_ BO_ 2365470720 "ISOBUS DD: Auxiliary valve 8 command (PGN 65080, ISO 11783-7)";
CM_ SG_ 2365470720 Auxiliary_valve_number_8_port_flow_Command "SPN 2259 (Command)";
CM_ SG_ 2365470720 Auxiliary_valve_number_8_Resolution_mode_Command "SPN 7880 (Command)";
CM_ SG_ 2365470720 Auxiliary_valve_number_8_state_Command "SPN 2260 (Command)";
CM_ SG_ 2365470720 Auxiliary_valve_number_8_fail_safe_mode_Command "SPN 2261 (Command)";
CM_ SG_ 2365470720 Auxiliary_valve_number_8_port_flow_Extended_Resolution_Command "SPN 7864 (Command)";
CM_ BO_ 2365470976 "ISOBUS DD: Auxiliary valve 9 command (PGN 65081, ISO 11783-7)";
CM_ SG_ 2365470976 Auxiliary_valve_number_9_port_flow_Command "SPN 2271 (Command)";
CM_ SG_ 2365470976 Auxiliary_valve_number_9_Resolution_mode_Command "SPN 7881 (Command)";
CM_ SG_ 2365470976 Auxiliary_valve_number_9_state_Command "SPN 2272 (Command)";
CM_ SG_ 2365470976 Auxiliary_valve_number_9_fail_safe_mode_Command "SPN 2273 (Command)";
CM_ SG_ 2365470976 Auxiliary_valve_number_9_port_flow_Extended_Resolution_Command "SPN 7865 (Command)";
CM_ BO_ 2365471232 "ISOBUS DD: Auxiliary valve 10 command (PGN 65082, ISO 11783-7)";
CM_ SG_ 2365471232 Auxiliary_valve_number_10_port_flow_Command "SPN 2283 (Command)";
CM_ SG_ 2365471232 Auxiliary_valve_number_10_Resolution_mode_Command "SPN 7882 (Command)";
CM_ SG_ 2365471232 Auxiliary_valve_number_10_state_Command "SPN 2284 (Command)";
CM_ SG_ 2365471232 Auxiliary_valve_number_10_fail_safe_mode_Command "SPN 2285 (Command)";
CM_ SG_ 2365471232 Auxiliary_valve_number_10_port_flow_Extended_Resolution_Command "SPN 7866 (Command)";
CM_ BO_ 2365471488 "ISOBUS DD: Auxiliary valve 11 command (PGN 65083, ISO 11783-7)";
CM_ SG_ 2365471488 Auxiliary_valve_number_11_port_flow_Command "SPN 2295 (Command)";
CM_ SG_ 2365471488 Auxiliary_valve_number_11_Resolution_mode_Command "SPN 7883 (Command)";
CM_ SG_ 2365471488 Auxiliary_valve_number_11_state_Command "SPN 2296 (Command)";
CM_ SG_ 2365471488 Auxiliary_valve_number_11_fail_safe_mode_Command "SPN 2297 (Command)";
CM_ SG_ 2365471488 Auxiliary_valve_number_11_port_flow_Extended_Resolution_Command "SPN 7867 (Command)";
CM_ BO_ 2365471744 "ISOBUS DD: Auxiliary valve 12 command (PGN 65084, ISO 11783-7)";
CM_ SG_ 2365471744 Auxiliary_valve_number_12_port_flow_Command "SPN 2307 (Command)";
CM_ SG_ 2365471744 Auxiliary_valve_number_12_Resolution_mode_Command "SPN 7884 (Command)";
CM_ SG_ 2365471744 Auxiliary_valve_number_12_state_Command "SPN 2308 (Command)";
CM_ SG_ 2365471744 Auxiliary_valve_number_12_fail_safe_mode_Command "SPN 2309 (Command)";
CM_ SG_ 2365471744 Auxiliary_valve_number_12_port_flow_Extended_Resolution_Command "SPN 7868 (Command)";
CM_ BO_ 2365472000 "ISOBUS DD: Auxiliary valve 13 command (PGN 65085, ISO 11783-7)";
CM_ SG_ 2365472000 Auxiliary_valve_number_13_port_flow_Command "SPN 2319 (Command)";
CM_ SG_ 2365472000 Auxiliary_valve_number_13_Resolution_mode_Command "SPN 7885 (Command)";
CM_ SG_ 2365472000 Auxiliary_valve_number_13_state_Command "SPN 2320 (Command)";
CM_ SG_ 2365472000 Auxiliary_valve_number_13_fail_safe_mode_Command "SPN 2321 (Command)";
CM_ SG_ 2365472000 Auxiliary_valve_number_13_port_flow_Extended_Resolution_Command "SPN 7869 (Command)";
CM_ BO_ 2365472256 "ISOBUS DD: Auxiliary valve 14 command (PGN 65086, ISO 11783-7)";
CM_ SG_ 2365472256 Auxiliary_valve_number_14_port_flow_Command "SPN 2331 (Command)";
CM_ SG_ 2365472256 Auxiliary_valve_number_14_Resolution_mode_Command "SPN 7886 (Command)";
CM_ SG_ 2365472256 Auxiliary_valve_number_14_state_Command "SPN 2332 (Command)";
CM_ SG_ 2365472256 Auxiliary_valve_number_14_fail_safe_mode_Command "SPN 2333 (Command)";
CM_ SG_ 2365472256 Auxiliary_valve_number_14_port_flow_Extended_Resolution_Command "SPN 7870 (Command)";
CM_ BO_ 2365472512 "ISOBUS DD: Auxiliary valve 15 command (PGN 65087, ISO 11783-7)";
CM_ SG_ 2365472512 Auxiliary_valve_number_15_port_flow_Command "SPN 2343 (Command)";
CM_ SG_ 2365472512 Auxiliary_valve_number_15_Resolution_mode_Command "SPN 7887 (Command)";
CM_ SG_ 2365472512 Auxiliary_valve_number_15_state_Command "SPN 2344 (Command)";
CM_ SG_ 2365472512 Auxiliary_valve_number_15_fail_safe_mode_Command "SPN 2345 (Command)";
CM_ SG_ 2365472512 Auxiliary_valve_number_15_port_flow_Extended_Resolution_Command "SPN 7871 (Command)";
CM_ BO_ 2566799360 "ISOBUS DD: Lighting Data (PGN 65088, ISO 11783-7)";
CM_ SG_ 2566799360 Daytime_running_lights "SPN 2404 (Measured)";
CM_ SG_ 2566799360 Alternate_headlights "SPN 2352 (Measured)";
CM_ SG_ 2566799360 Low_beam_headlights "SPN 2350 (Measured)";
CM_ SG_ 2566799360 High_beam_headlights "SPN 2348 (Measured)";
CM_ SG_ 2566799360 Tractor_front_fog_lights "SPN 2388 (Measured)";
CM_ SG_ 2566799360 Rotating_beacon_light "SPN 2386 (Measured)";
CM_ SG_ 2566799360 Right_turn_signal_lights "SPN 2370 (Measured)";
CM_ SG_ 2566799360 Left_turn_signal_lights "SPN 2368 (Measured)";
CM_ SG_ 2566799360 Back_up_lights_and_alarm_horn "SPN 2392 (Measured)";
CM_ SG_ 2566799360 Center_stop_lights "SPN 2376 (Measured)";
CM_ SG_ 2566799360 Right_stop_lights "SPN 2374 (Measured)";
CM_ SG_ 2566799360 Left_stop_lights "SPN 2372 (Measured)";
CM_ SG_ 2566799360 Implement_clearance_lights "SPN 2384 (Measured)";
CM_ SG_ 2566799360 Tractor_clearance_lights "SPN 2382 (Measured)";
CM_ SG_ 2566799360 Implement_marker_position_lights "SPN 2380 (Measured)";
CM_ SG_ 2566799360 Tractor_marker_position_lights "SPN 2378 (Measured)";
CM_ SG_ 2566799360 Rear_fog_lights "SPN 2390 (Measured)";
CM_ SG_ 2566799360 Tractor_underside_mounted_work_lights "SPN 2358 (Measured)";
CM_ SG_ 2566799360 Tractor_rear_low_mounted_work_lights "SPN 2360 (Measured)";
CM_ SG_ 2566799360 Tractor_rear_high_mounted_work_lights "SPN 2362 (Measured)";
CM_ SG_ 2566799360 Tractor_side_low_mounted_work_lights "SPN 2364 (Measured)";
CM_ SG_ 2566799360 Tractor_side_high_mounted_work_lights "SPN 2366 (Measured)";
CM_ SG_ 2566799360 Tractor_front_low_mounted_work_lights "SPN 2354 (Measured)";
CM_ SG_ 2566799360 Tractor_front_high_mounted_work_lights "SPN 2356 (Measured)";
CM_ SG_ 2566799360 Implement_OEM_option_2_light "SPN 2398 (Measured)";
CM_ SG_ 2566799360 Implement_OEM_option_1_light "SPN 2396 (Measured)";
CM_ SG_ 2566799360 Implement_right_forward_work_lights "SPN 2407 (Measured)";
CM_ SG_ 2566799360 Implement_left_forward_work_lights "SPN 2598 (Measured)";
CM_ SG_ 2566799360 Implement_right_facing_work_lights "SPN 2402 (Measured)";
CM_ SG_ 2566799360 Implement_left_facing_work_lights "SPN 2400 (Measured)";
CM_ SG_ 2566799360 Implement_rear_work_lights "SPN 2394 (Measured)";
CM_ BO_ 2365473024 "ISOBUS DD: Lighting command (PGN 65089, ISO 11783-7)";
CM_ SG_ 2365473024 Daytime_running_lights_Command "SPN 2403 (Command)";
CM_ SG_ 2365473024 Alternate_headlights_Command "SPN 2351 (Command)";
CM_ SG_ 2365473024 Low_beam_headlights_Command "SPN 2349 (Command)";
CM_ SG_ 2365473024 High_beam_headlights_Command "SPN 2347 (Command)";
CM_ SG_ 2365473024 Tractor_front_fog_lights_Command "SPN 2387 (Command)";
CM_ SG_ 2365473024 Rotating_beacon_light_Command "SPN 2385 (Command)";
CM_ SG_ 2365473024 Right_turn_signal_lights_Command "SPN 2369 (Command)";
CM_ SG_ 2365473024 Left_turn_signal_lights_Command "SPN 2367 (Command)";
CM_ SG_ 2365473024 Back_up_lights_and_alarm_horn_Command "SPN 2391 (Command)";
CM_ SG_ 2365473024 Centre_stop_lights_Command "SPN 2375 (Command)";
CM_ SG_ 2365473024 Right_stop_lights_Command "SPN 2373 (Command)";
CM_ SG_ 2365473024 Left_stop_lights_Command "SPN 2371 (Command)";
CM_ SG_ 2365473024 Implement_clearance_lights_Command "SPN 2383 (Command)";
CM_ SG_ 2365473024 Tractor_clearance_lights_Command "SPN 2381 (Command)";
CM_ SG_ 2365473024 Implement_marker_position_lights_Command "SPN 2379 (Command)";
CM_ SG_ 2365473024 Tractor_marker_position_lights_Command "SPN 2377 (Command)";
CM_ SG_ 2365473024 Rear_fog_lights_Command "SPN 2389 (Command)";
CM_ SG_ 2365473024 Tractor_underside_mounted_work_lights_Command "SPN 2357 (Command)";
CM_ SG_ 2365473024 Tractor_rear_low_mounted_work_lights_Command "SPN 2359 (Command)";
CM_ SG_ 2365473024 Tractor_rear_high_mounted_work_lights_Command "SPN 2361 (Command)";
CM_ SG_ 2365473024 Tractor_side_low_mounted_work_lights_Command "SPN 2363 (Command)";
CM_ SG_ 2365473024 Tractor_side_high_mounted_work_lights_Command "SPN 2365 (Command)";
CM_ SG_ 2365473024 Tractor_front_low_mounted_work_lights_Command "SPN 2353 (Command)";
CM_ SG_ 2365473024 Tractor_front_high_mounted_work_lights_Command "SPN 2355 (Command)";
CM_ SG_ 2365473024 Implement_OEM_option_2_light_Command "SPN 2397 (Command)";
CM_ SG_ 2365473024 Implement_OEM_option_1_light_Command "SPN 2395 (Command)";
CM_ SG_ 2365473024 Implement_right_forward_work_lights_Command "SPN 2406 (Command)";
CM_ SG_ 2365473024 Implement_left_forward_work_lights_Command "SPN 2597 (Command)";
CM_ SG_ 2365473024 Lighting_data_message_request_Command "SPN 2393 (Command)";
CM_ SG_ 2365473024 Implement_right_facing_work_lights_Command "SPN 2401 (Command)";
CM_ SG_ 2365473024 Implement_left_facing_work_lights_Command "SPN 2399 (Command)";
CM_ SG_ 2365473024 Implement_rear_work_lights_Command "SPN 2405 (Command)";
CM_ BO_ 2365473280 "ISOBUS DD: Hitch and PTO commands (PGN 65090, ISO 11783-7)";
CM_ SG_ 2365473280 Front_hitch_position_Command "SPN 1874 (Command)";
CM_ SG_ 2365473280 Rear_hitch_position_Command "SPN 1875 (Command)";
CM_ SG_ 2365473280 Front_PTO_output_shaft_speed_set_point_Command "SPN 1886 (Command)";
CM_ SG_ 2365473280 Rear_PTO_output_shaft_speed_set_point_Command "SPN 1887 (Command)";
CM_ SG_ 2365473280 Rear_PTO_engagement_Command "SPN 1894 (Command)";
CM_ SG_ 2365473280 Front_PTO_engagement_Command "SPN 1893 (Command)";
CM_ SG_ 2365473280 Rear_PTO_economy_mode_Command "SPN 1898 (Command)";
CM_ SG_ 2365473280 Front_PTO_economy_mode_Command "SPN 1897 (Command)";
CM_ SG_ 2365473280 Rear_PTO_mode_Command "SPN 1896 (Command)";
CM_ SG_ 2365473280 Front_PTO_mode_Command "SPN 1895 (Command)";
CM_ BO_ 2365473536 "ISOBUS DD: Primary or Rear Power Take off Output Shaft (PGN 65091, ISO 11783-7)";
CM_ SG_ 2365473536 Rear_PTO_output_shaft_speed "SPN 1883 (Measured)";
CM_ SG_ 2365473536 Rear_PTO_Output_Shaft_Speed_Set_Point "SPN 1885 (Measured)";
CM_ SG_ 2365473536 Rear_PTO_engagement_request_status "SPN 5156 (Measured)";
CM_ SG_ 2365473536 Rear_Power_Take_Off_Economy_Mode "SPN 1892 (Measured)";
CM_ SG_ 2365473536 Rear_Power_Take_Off_Mode "SPN 1890 (Measured)";
CM_ SG_ 2365473536 Rear_Power_Take_Off_Engagement "SPN 2408 (Measured)";
CM_ SG_ 2365473536 Rear_PTO_shaft_speed_limit_status "SPN 5159 (Measured)";
CM_ SG_ 2365473536 Rear_PTO_Economy_mode_request_status "SPN 5158 (Measured)";
CM_ SG_ 2365473536 Rear_PTO_mode_request_status "SPN 5157 (Measured)";
CM_ SG_ 2365473536 Rear_PTO_exit_reason_code "SPN 5820 (Measured)";
CM_ BO_ 2365473792 "ISOBUS DD: Secondary or Front Power Take off Output Shaft (PGN 65092, ISO 11783-7)";
CM_ SG_ 2365473792 Front_PTO_output_shaft_speed "SPN 1882 (Measured)";
CM_ SG_ 2365473792 Front_PTO_Output_Shaft_Speed_Set_Point "SPN 1884 (Measured)";
CM_ SG_ 2365473792 Front_PTO_engagement_request_status "SPN 5152 (Measured)";
CM_ SG_ 2365473792 Front_Power_Take_Off_Economy_Mode "SPN 1891 (Measured)";
CM_ SG_ 2365473792 Front_Power_Take_Off_Mode "SPN 1889 (Measured)";
CM_ SG_ 2365473792 Front_Power_Take_Off_Engagement "SPN 1888 (Measured)";
CM_ SG_ 2365473792 Front_PTO_shaft_speed_limit_status "SPN 5155 (Measured)";
CM_ SG_ 2365473792 Front_PTO_Economy_mode_request_status "SPN 5154 (Measured)";
CM_ SG_ 2365473792 Front_PTO_mode_request_status "SPN 5153 (Measured)";
CM_ SG_ 2365473792 Front_PTO_exit_reason_code "SPN 5817 (Measured)";
CM_ BO_ 2365474048 "ISOBUS DD: Primary or Rear Hitch Status (PGN 65093, ISO 11783-7)";
CM_ SG_ 2365474048 Rear_Hitch_Position "SPN 1873 (Measured)";
CM_ SG_ 2365474048 Rear_Hitch_Position_Limit_status "SPN 5151 (Measured)";
CM_ SG_ 2365474048 Rear_Hitch_In_work_Indication "SPN 1877 (Measured)";
CM_ SG_ 2365474048 Rear_Nominal_Lower_Link_Force "SPN 1881 (Measured)";
CM_ SG_ 2365474048 Rear_Draft "SPN 1879 (Measured)";
CM_ SG_ 2365474048 Rear_hitch_exit_reason_code "SPN 5819 (Measured)";
CM_ BO_ 2365474304 "ISOBUS DD: Secondary or Front Hitch Status (PGN 65094, ISO 11783-7)";
CM_ SG_ 2365474304 Front_Hitch_Position "SPN 1872 (Measured)";
CM_ SG_ 2365474304 Front_Hitch_Position_Limit_status "SPN 5150 (Measured)";
CM_ SG_ 2365474304 Front_Hitch_In_work_Indication "SPN 1876 (Measured)";
CM_ SG_ 2365474304 Front_Nominal_Lower_Link_Force "SPN 1880 (Measured)";
CM_ SG_ 2365474304 Front_Draft "SPN 1878 (Measured)";
CM_ SG_ 2365474304 Front_hitch_exit_reason_code "SPN 5816 (Measured)";
CM_ BO_ 2566801152 "ISOBUS DD: Maintain Power (PGN 65095, ISO 11783-7)";
CM_ SG_ 2566801152 Maintain_Acuator_Power "SPN 1868 (Command)";
CM_ SG_ 2566801152 Maintain_ECU_Power "SPN 1867 (Command)";
CM_ SG_ 2566801152 Implement_in_work_state "SPN 7447 (Measured)";
CM_ SG_ 2566801152 Implement_ready_to_work_state "SPN 1871 (Measured)";
CM_ SG_ 2566801152 Implement_Park_state "SPN 1870 (Measured)";
CM_ SG_ 2566801152 Implement_Transport_state "SPN 1869 (Measured)";
CM_ BO_ 2365474816 "ISOBUS DD: Wheel-based Speed and Distance (PGN 65096, ISO 11783-7)";
CM_ SG_ 2365474816 Wheel_based_machine_speed "SPN 1862 (Measured)";
CM_ SG_ 2365474816 Wheel_based_machine_distance "SPN 1863 (Measured)";
CM_ SG_ 2365474816 Maximum_Time_of_Tractor_Power "SPN 1866 (Measured)";
CM_ SG_ 2365474816 Wheel_based_machine_direction "SPN 1864 (Measured)";
CM_ SG_ 2365474816 Key_switch_state "SPN 1865 (Measured)";
CM_ SG_ 2365474816 Implement_Start_Stop_operations "SPN 5203 (Measured)";
CM_ SG_ 2365474816 Operator_direction_reversed "SPN 5244 (Measured)";
CM_ BO_ 2365475072 "ISOBUS DD: Ground-based Speed and Distance (PGN 65097, ISO 11783-7)";
CM_ SG_ 2365475072 Ground_based_machine_speed "SPN 1859 (Measured)";
CM_ SG_ 2365475072 Ground_based_machine_distance "SPN 1860 (Measured)";
CM_ SG_ 2365475072 Ground_based_machine_direction "SPN 1861 (Measured)";
CM_ BO_ 2566834688 "ISOBUS DD: Active Diagnostic Trouble Codes (PGN 65226, ISO 11783-7)";
CM_ SG_ 2566834688 Suspect_Parameter_Number "SPN 1214 (Measured)";
CM_ SG_ 2566834688 Occurrence_Count "SPN 1216 (Measured)";
CM_ SG_ 2566834688 SPN_Conversion_Method "SPN 1706 (Measured)";
CM_ BO_ 2566834944 "ISOBUS DD: Previously Active Diagnostic Trouble Codes (PGN 65227, ISO 11783-7)";
CM_ SG_ 2566834944 Suspect_Parameter_Number "SPN 1214 (Measured)";
CM_ SG_ 2566834944 Occurrence_Count "SPN 1216 (Measured)";
CM_ SG_ 2566834944 SPN_Conversion_Method "SPN 1706 (Measured)";
CM_ BO_ 2566838784 "ISOBUS DD: Software Identification (PGN 65242, ISO 11783-7)";
CM_ SG_ 2566838784 Number_of_Software_Identification_Fields "SPN 965 (Measured)";
CM_ SG_ 2566838784 Software_Identification "SPN 234 (Measured)";
CM_ BO_ 2566841856 "ISOBUS DD: Time/Date (PGN 65254, ISO 11783-7)";
CM_ SG_ 2566841856 Seconds "SPN 959 (Measured)";
CM_ SG_ 2566841856 Minutes "SPN 960 (Measured)";
CM_ SG_ 2566841856 Hours "SPN 961 (Measured)";
CM_ SG_ 2566841856 Month "SPN 963 (Measured)";
CM_ SG_ 2566841856 Day "SPN 962 (Measured)";
CM_ SG_ 2566841856 Year "SPN 964 (Measured)";
CM_ SG_ 2566841856 Local_minute_offset "SPN 1601 (Measured)";
CM_ SG_ 2566841856 Local_hour_offset "SPN 1602 (Measured)";
